VERSION ""

NS_ :

BS_:

BU_: Turbocharger OnBoardDataLogger OffBoardDiagnosticTool2 OffBoardDiagnosticTool1 FileServer ParkingBrakeController SeatController2 FanDriveController SteeringColumnUnit CommunicationUnitRadio CommunicationUnitSatellite CommunicationUnitCellular PropulsionBatteryCharger ChassisController2 ChassisController1 EngineValveControl AuxiliaryHeater2 AuxiliaryHeater1 ClutchUnit RampControl InformationSystem1 SuspensionSystemController2 OilSensor VehicleDynamicStability ExhaustEmissionController TransmissionDisplay2 TransmissionDisplay1 ClimateControl2 WaterPumpController RearAxleSteeringController LightingOperatorControl SeatController1 IgnitionController2 IgnitionController1 TirePressureController CabController2 CabController1 PneumaticSystemController SuspensionSystemController1 HydraulicPumpController EnduranceBrakingSystem RetarderExhaustEngine2 OnBoardDiagnosticUnit HeadwayController RetarderExhaustEngine1 CabDisplay1 ManagementComputer VirtualTerminal OffVehicleGateway PowerTakeOffFront HitchControl AuxiliaryValveControl BodyController TractorTrailerBridge1 StarterSystem ElectricalSystem VehicleSecurity VehicleNavigation AerodynamicControl ElectricalChargingSystem ClimateControl1 TripRecorder InstrumentCluster SuspensionDriveAxle2 SuspensionDriveAxle1 SuspensionSteerAxle SteeringController FuelSystem CruiseControl RetarderDriveline RetarderEngine BrakesDriveAxle2 BrakesDriveAxle1 BrakesSystemController BrakesSteerAxle AxleDrive2 AxleDrive1 AxleSteering PowerTakeOff ShiftConsoleSecondary ShiftConsolePrimary Transmission2 Transmission1 Engine2 Engine1

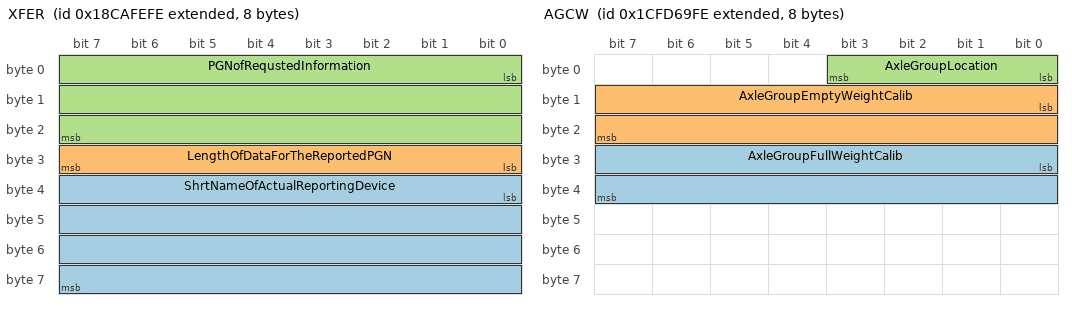
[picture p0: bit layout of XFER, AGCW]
BO_ 2563440382 XFER: 8 Vector__XXX
 SG_ ShrtNameOfActualReportingDevice : 32|32@1+ (1,0) [0|0] "(2^32 - 1)" Vector__XXX
 SG_ LengthOfDataForTheReportedPGN : 24|8@1+ (1,0) [0|255] "" Vector__XXX
 SG_ PGNofRequstedInformation : 0|24@1+ (1,0) [0|16777215] "" Vector__XXX

BO_ 2632711934 TPDT: 8 Vector__XXX
 SG_ SequenceNumber : 0|8@1+ (1,0) [0|255] "" Vector__XXX

BO_ 2632777470 TPCM: 8 Vector__XXX
 SG_ TotalNumberOfPacketsEoMA m19 : 24|8@1+ (1,0) [0|255] "" Vector__XXX
 SG_ TotalMessageSizeEoMA m19 : 8|16@1+ (1,0) [0|64255] "counts" Vector__XXX
 SG_ TotalMessageSizeBAM m32 : 8|16@1+ (1,0) [0|64255] "counts" Vector__XXX
 SG_ TotalNumberOfPacketsBAM m32 : 24|8@1+ (1,0) [0|255] "" Vector__XXX
 SG_ ConnectionAbortReason m255 : 8|8@1+ (1,0) [0|255] "" Vector__XXX
 SG_ NextPacketNumberToBeSent m17 : 16|8@1+ (1,0) [0|255] "" Vector__XXX
 SG_ NumberOfPacketsThatCanBeSent m17 : 8|8@1+ (1,0) [0|255] "" Vector__XXX
 SG_ PGNumber : 40|24@1+ (1,0) [0|16777200] "" Vector__XXX
 SG_ MaximumNumberOfPackets m16 : 32|8@1+ (1,0) [0|255] "" Vector__XXX
 SG_ TotalNumberOfPackets m16 : 24|8@1+ (1,0) [0|255] "" Vector__XXX
 SG_ TotalMessageSize m16 : 8|16@1+ (1,0) [0|64255] "counts" Vector__XXX
 SG_ ControlByte M : 0|8@1+ (1,0) [0|255] "" Vector__XXX

BO_ 2563374846 RQST2: 8 Vector__XXX
 SG_ UseTransferMode : 24|2@1+ (1,0) [0|3] "" Vector__XXX
 SG_ ParameterGroupNumber : 0|24@1+ (1,0) [0|16777215] "" Vector__XXX

BO_ 2565537534 RQST: 3 Vector__XXX
 SG_ ParameterGroupNumber : 0|24@1+ (1,0) [0|16777215] "" Vector__XXX

BO_ 2499635966 AGW: 8 Vector__XXX
 SG_ AxleGroupWeight : 8|16@1+ (2,0) [0|128510] "kg" Vector__XXX
 SG_ AxleGroupLocation : 0|4@1+ (1,0) [0|15] "" Vector__XXX

BO_ 2633853438 AGCW: 8 Vector__XXX
 SG_ AxleGroupFullWeightCalib : 24|16@1+ (2,0) [0|128510] "kg" Vector__XXX
 SG_ AxleGroupEmptyWeightCalib : 8|16@1+ (2,0) [0|128510] "kg" Vector__XXX
 SG_ AxleGroupLocation : 0|4@1+ (1,0) [0|15] "" Vector__XXX

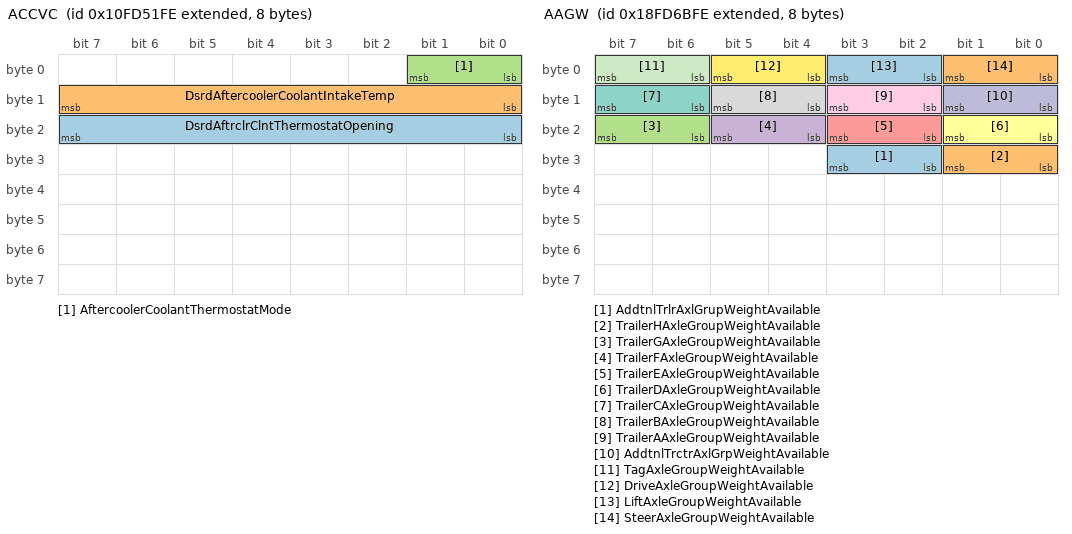
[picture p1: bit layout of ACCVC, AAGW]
BO_ 2432520702 ACCVC: 8 Vector__XXX
 SG_ DsrdAftrclrClntThermostatOpening : 16|8@1+ (0.4,0) [0|100] "%" Vector__XXX
 SG_ DsrdAftercoolerCoolantIntakeTemp : 8|8@1+ (1,-40) [-40|210] "deg C" Vector__XXX
 SG_ AftercoolerCoolantThermostatMode : 0|2@1+ (1,0) [0|3] "" Vector__XXX

BO_ 2566745086 AAGW: 8 Vector__XXX
 SG_ AddtnlTrlrAxlGrupWeightAvailable : 26|2@1+ (1,0) [0|3] "" Vector__XXX
 SG_ TrailerHAxleGroupWeightAvailable : 24|2@1+ (1,0) [0|3] "" Vector__XXX
 SG_ TrailerGAxleGroupWeightAvailable : 22|2@1+ (1,0) [0|3] "" Vector__XXX
 SG_ TrailerFAxleGroupWeightAvailable : 20|2@1+ (1,0) [0|3] "" Vector__XXX
 SG_ TrailerEAxleGroupWeightAvailable : 18|2@1+ (1,0) [0|3] "" Vector__XXX
 SG_ TrailerDAxleGroupWeightAvailable : 16|2@1+ (1,0) [0|3] "" Vector__XXX
 SG_ TrailerCAxleGroupWeightAvailable : 14|2@1+ (1,0) [0|3] "" Vector__XXX
 SG_ TrailerBAxleGroupWeightAvailable : 12|2@1+ (1,0) [0|3] "" Vector__XXX
 SG_ TrailerAAxleGroupWeightAvailable : 10|2@1+ (1,0) [0|3] "" Vector__XXX
 SG_ AddtnlTrctrAxlGrpWeightAvailable : 8|2@1+ (1,0) [0|3] "" Vector__XXX
 SG_ TagAxleGroupWeightAvailable : 6|2@1+ (1,0) [0|3] "" Vector__XXX
 SG_ DriveAxleGroupWeightAvailable : 4|2@1+ (1,0) [0|3] "" Vector__XXX
 SG_ LiftAxleGroupWeightAvailable : 2|2@1+ (1,0) [0|3] "" Vector__XXX
 SG_ SteerAxleGroupWeightAvailable : 0|2@1+ (1,0) [0|3] "" Vector__XXX

BO_ 2566739198 DM52: 22 Vector__XXX
 SG_ FlashRedStopLamp : 12|2@1+ (1,0) [0|3] "" Vector__XXX
 SG_ FlashProtectLamp : 8|2@1+ (1,0) [0|3] "" Vector__XXX
 SG_ FlashMalfuncIndicatorLamp : 14|2@1+ (1,0) [0|3] "" Vector__XXX
 SG_ FlashAmberWarningLamp : 10|2@1+ (1,0) [0|3] "" Vector__XXX
 SG_ MalfunctionIndicatorLampStatus : 6|2@1+ (1,0) [0|3] "" Vector__XXX
 SG_ AmberWarningLampStatus : 2|2@1+ (1,0) [0|3] "" Vector__XXX
 SG_ RedStopLampState : 4|2@1+ (1,0) [0|3] "" Vector__XXX
 SG_ ProtectLampStatus : 0|2@1+ (1,0) [0|3] "" Vector__XXX
 SG_ DTC5 : 144|32@1+ (1,0) [0|4294967295] "" Vector__XXX
 SG_ DTC4 : 112|32@1+ (1,0) [0|4294967295] "" Vector__XXX
 SG_ DTC3 : 80|32@1+ (1,0) [0|4294967295] "" Vector__XXX
 SG_ DTC2 : 48|32@1+ (1,0) [0|4294967295] "" Vector__XXX
 SG_ DTC1 : 16|32@1+ (1,0) [0|4294967295] "" Vector__XXX

BO_ 2566739454 DM51: 22 Vector__XXX
 SG_ FlashRedStopLamp : 12|2@1+ (1,0) [0|3] "" Vector__XXX
 SG_ FlashProtectLamp : 8|2@1+ (1,0) [0|3] "" Vector__XXX
 SG_ FlashMalfuncIndicatorLamp : 14|2@1+ (1,0) [0|3] "" Vector__XXX
 SG_ FlashAmberWarningLamp : 10|2@1+ (1,0) [0|3] "" Vector__XXX
 SG_ MalfunctionIndicatorLampStatus : 6|2@1+ (1,0) [0|3] "" Vector__XXX
 SG_ AmberWarningLampStatus : 2|2@1+ (1,0) [0|3] "" Vector__XXX
 SG_ RedStopLampState : 4|2@1+ (1,0) [0|3] "" Vector__XXX
 SG_ ProtectLampStatus : 0|2@1+ (1,0) [0|3] "" Vector__XXX
 SG_ DTC5 : 144|32@1+ (1,0) [0|4294967295] "" Vector__XXX
 SG_ DTC4 : 112|32@1+ (1,0) [0|4294967295] "" Vector__XXX
 SG_ DTC3 : 80|32@1+ (1,0) [0|4294967295] "" Vector__XXX
 SG_ DTC2 : 48|32@1+ (1,0) [0|4294967295] "" Vector__XXX
 SG_ DTC1 : 16|32@1+ (1,0) [0|4294967295] "" Vector__XXX

BO_ 2566739710 DM50: 22 Vector__XXX
 SG_ FlashRedStopLamp : 12|2@1+ (1,0) [0|3] "" Vector__XXX
 SG_ FlashProtectLamp : 8|2@1+ (1,0) [0|3] "" Vector__XXX
 SG_ FlashMalfuncIndicatorLamp : 14|2@1+ (1,0) [0|3] "" Vector__XXX
 SG_ FlashAmberWarningLamp : 10|2@1+ (1,0) [0|3] "" Vector__XXX
 SG_ MalfunctionIndicatorLampStatus : 6|2@1+ (1,0) [0|3] "" Vector__XXX
 SG_ AmberWarningLampStatus : 2|2@1+ (1,0) [0|3] "" Vector__XXX
 SG_ RedStopLampState : 4|2@1+ (1,0) [0|3] "" Vector__XXX
 SG_ ProtectLampStatus : 0|2@1+ (1,0) [0|3] "" Vector__XXX
 SG_ DTC5 : 144|32@1+ (1,0) [0|4294967295] "" Vector__XXX
 SG_ DTC4 : 112|32@1+ (1,0) [0|4294967295] "" Vector__XXX
 SG_ DTC3 : 80|32@1+ (1,0) [0|4294967295] "" Vector__XXX
 SG_ DTC2 : 48|32@1+ (1,0) [0|4294967295] "" Vector__XXX
 SG_ DTC1 : 16|32@1+ (1,0) [0|4294967295] "" Vector__XXX

BO_ 2566739966 DM49: 22 Vector__XXX
 SG_ FlashRedStopLamp : 12|2@1+ (1,0) [0|3] "" Vector__XXX
 SG_ FlashProtectLamp : 8|2@1+ (1,0) [0|3] "" Vector__XXX
 SG_ FlashMalfuncIndicatorLamp : 14|2@1+ (1,0) [0|3] "" Vector__XXX
 SG_ FlashAmberWarningLamp : 10|2@1+ (1,0) [0|3] "" Vector__XXX
 SG_ MalfunctionIndicatorLampStatus : 6|2@1+ (1,0) [0|3] "" Vector__XXX
 SG_ AmberWarningLampStatus : 2|2@1+ (1,0) [0|3] "" Vector__XXX
 SG_ RedStopLampState : 4|2@1+ (1,0) [0|3] "" Vector__XXX
 SG_ ProtectLampStatus : 0|2@1+ (1,0) [0|3] "" Vector__XXX
 SG_ DTC5 : 144|32@1+ (1,0) [0|4294967295] "" Vector__XXX
 SG_ DTC4 : 112|32@1+ (1,0) [0|4294967295] "" Vector__XXX
 SG_ DTC3 : 80|32@1+ (1,0) [0|4294967295] "" Vector__XXX
 SG_ DTC2 : 48|32@1+ (1,0) [0|4294967295] "" Vector__XXX
 SG_ DTC1 : 16|32@1+ (1,0) [0|4294967295] "" Vector__XXX

BO_ 2566740222 DM48: 22 Vector__XXX
 SG_ FlashRedStopLamp : 12|2@1+ (1,0) [0|3] "" Vector__XXX
 SG_ FlashProtectLamp : 8|2@1+ (1,0) [0|3] "" Vector__XXX
 SG_ FlashMalfuncIndicatorLamp : 14|2@1+ (1,0) [0|3] "" Vector__XXX
 SG_ FlashAmberWarningLamp : 10|2@1+ (1,0) [0|3] "" Vector__XXX
 SG_ MalfunctionIndicatorLampStatus : 6|2@1+ (1,0) [0|3] "" Vector__XXX
 SG_ AmberWarningLampStatus : 2|2@1+ (1,0) [0|3] "" Vector__XXX
 SG_ RedStopLampState : 4|2@1+ (1,0) [0|3] "" Vector__XXX
 SG_ ProtectLampStatus : 0|2@1+ (1,0) [0|3] "" Vector__XXX
 SG_ DTC5 : 144|32@1+ (1,0) [0|4294967295] "" Vector__XXX
 SG_ DTC4 : 112|32@1+ (1,0) [0|4294967295] "" Vector__XXX
 SG_ DTC3 : 80|32@1+ (1,0) [0|4294967295] "" Vector__XXX
 SG_ DTC2 : 48|32@1+ (1,0) [0|4294967295] "" Vector__XXX
 SG_ DTC1 : 16|32@1+ (1,0) [0|4294967295] "" Vector__XXX

BO_ 2566740478 DM47: 22 Vector__XXX
 SG_ FlashRedStopLamp : 12|2@1+ (1,0) [0|3] "" Vector__XXX
 SG_ FlashProtectLamp : 8|2@1+ (1,0) [0|3] "" Vector__XXX
 SG_ FlashMalfuncIndicatorLamp : 14|2@1+ (1,0) [0|3] "" Vector__XXX
 SG_ FlashAmberWarningLamp : 10|2@1+ (1,0) [0|3] "" Vector__XXX
 SG_ MalfunctionIndicatorLampStatus : 6|2@1+ (1,0) [0|3] "" Vector__XXX
 SG_ AmberWarningLampStatus : 2|2@1+ (1,0) [0|3] "" Vector__XXX
 SG_ RedStopLampState : 4|2@1+ (1,0) [0|3] "" Vector__XXX
 SG_ ProtectLampStatus : 0|2@1+ (1,0) [0|3] "" Vector__XXX
 SG_ DTC5 : 144|32@1+ (1,0) [0|4294967295] "" Vector__XXX
 SG_ DTC4 : 112|32@1+ (1,0) [0|4294967295] "" Vector__XXX
 SG_ DTC3 : 80|32@1+ (1,0) [0|4294967295] "" Vector__XXX
 SG_ DTC2 : 48|32@1+ (1,0) [0|4294967295] "" Vector__XXX
 SG_ DTC1 : 16|32@1+ (1,0) [0|4294967295] "" Vector__XXX

BO_ 2566740734 DM46: 22 Vector__XXX
 SG_ FlashRedStopLamp : 12|2@1+ (1,0) [0|3] "" Vector__XXX
 SG_ FlashProtectLamp : 8|2@1+ (1,0) [0|3] "" Vector__XXX
 SG_ FlashMalfuncIndicatorLamp : 14|2@1+ (1,0) [0|3] "" Vector__XXX
 SG_ FlashAmberWarningLamp : 10|2@1+ (1,0) [0|3] "" Vector__XXX
 SG_ MalfunctionIndicatorLampStatus : 6|2@1+ (1,0) [0|3] "" Vector__XXX
 SG_ AmberWarningLampStatus : 2|2@1+ (1,0) [0|3] "" Vector__XXX
 SG_ RedStopLampState : 4|2@1+ (1,0) [0|3] "" Vector__XXX
 SG_ ProtectLampStatus : 0|2@1+ (1,0) [0|3] "" Vector__XXX
 SG_ DTC5 : 144|32@1+ (1,0) [0|4294967295] "" Vector__XXX
 SG_ DTC4 : 112|32@1+ (1,0) [0|4294967295] "" Vector__XXX
 SG_ DTC3 : 80|32@1+ (1,0) [0|4294967295] "" Vector__XXX
 SG_ DTC2 : 48|32@1+ (1,0) [0|4294967295] "" Vector__XXX
 SG_ DTC1 : 16|32@1+ (1,0) [0|4294967295] "" Vector__XXX

BO_ 2566740990 DM45: 22 Vector__XXX
 SG_ FlashRedStopLamp : 12|2@1+ (1,0) [0|3] "" Vector__XXX
 SG_ FlashProtectLamp : 8|2@1+ (1,0) [0|3] "" Vector__XXX
 SG_ FlashMalfuncIndicatorLamp : 14|2@1+ (1,0) [0|3] "" Vector__XXX
 SG_ FlashAmberWarningLamp : 10|2@1+ (1,0) [0|3] "" Vector__XXX
 SG_ MalfunctionIndicatorLampStatus : 6|2@1+ (1,0) [0|3] "" Vector__XXX
 SG_ AmberWarningLampStatus : 2|2@1+ (1,0) [0|3] "" Vector__XXX
 SG_ RedStopLampState : 4|2@1+ (1,0) [0|3] "" Vector__XXX
 SG_ ProtectLampStatus : 0|2@1+ (1,0) [0|3] "" Vector__XXX
 SG_ DTC5 : 144|32@1+ (1,0) [0|4294967295] "" Vector__XXX
 SG_ DTC4 : 112|32@1+ (1,0) [0|4294967295] "" Vector__XXX
 SG_ DTC3 : 80|32@1+ (1,0) [0|4294967295] "" Vector__XXX
 SG_ DTC2 : 48|32@1+ (1,0) [0|4294967295] "" Vector__XXX
 SG_ DTC1 : 16|32@1+ (1,0) [0|4294967295] "" Vector__XXX

BO_ 2566741246 DM44: 22 Vector__XXX
 SG_ FlashRedStopLamp : 12|2@1+ (1,0) [0|3] "" Vector__XXX
 SG_ FlashProtectLamp : 8|2@1+ (1,0) [0|3] "" Vector__XXX
 SG_ FlashMalfuncIndicatorLamp : 14|2@1+ (1,0) [0|3] "" Vector__XXX
 SG_ FlashAmberWarningLamp : 10|2@1+ (1,0) [0|3] "" Vector__XXX
 SG_ MalfunctionIndicatorLampStatus : 6|2@1+ (1,0) [0|3] "" Vector__XXX
 SG_ AmberWarningLampStatus : 2|2@1+ (1,0) [0|3] "" Vector__XXX
 SG_ RedStopLampState : 4|2@1+ (1,0) [0|3] "" Vector__XXX
 SG_ ProtectLampStatus : 0|2@1+ (1,0) [0|3] "" Vector__XXX
 SG_ DTC5 : 144|32@1+ (1,0) [0|4294967295] "" Vector__XXX
 SG_ DTC4 : 112|32@1+ (1,0) [0|4294967295] "" Vector__XXX
 SG_ DTC3 : 80|32@1+ (1,0) [0|4294967295] "" Vector__XXX
 SG_ DTC2 : 48|32@1+ (1,0) [0|4294967295] "" Vector__XXX
 SG_ DTC1 : 16|32@1+ (1,0) [0|4294967295] "" Vector__XXX

BO_ 2566741502 DM43: 22 Vector__XXX
 SG_ FlashRedStopLamp : 12|2@1+ (1,0) [0|3] "" Vector__XXX
 SG_ FlashProtectLamp : 8|2@1+ (1,0) [0|3] "" Vector__XXX
 SG_ FlashMalfuncIndicatorLamp : 14|2@1+ (1,0) [0|3] "" Vector__XXX
 SG_ FlashAmberWarningLamp : 10|2@1+ (1,0) [0|3] "" Vector__XXX
 SG_ MalfunctionIndicatorLampStatus : 6|2@1+ (1,0) [0|3] "" Vector__XXX
 SG_ AmberWarningLampStatus : 2|2@1+ (1,0) [0|3] "" Vector__XXX
 SG_ RedStopLampState : 4|2@1+ (1,0) [0|3] "" Vector__XXX
 SG_ ProtectLampStatus : 0|2@1+ (1,0) [0|3] "" Vector__XXX
 SG_ DTC5 : 144|32@1+ (1,0) [0|4294967295] "" Vector__XXX
 SG_ DTC4 : 112|32@1+ (1,0) [0|4294967295] "" Vector__XXX
 SG_ DTC3 : 80|32@1+ (1,0) [0|4294967295] "" Vector__XXX
 SG_ DTC2 : 48|32@1+ (1,0) [0|4294967295] "" Vector__XXX
 SG_ DTC1 : 16|32@1+ (1,0) [0|4294967295] "" Vector__XXX

BO_ 2566741758 DM42: 22 Vector__XXX
 SG_ FlashRedStopLamp : 12|2@1+ (1,0) [0|3] "" Vector__XXX
 SG_ FlashProtectLamp : 8|2@1+ (1,0) [0|3] "" Vector__XXX
 SG_ FlashMalfuncIndicatorLamp : 14|2@1+ (1,0) [0|3] "" Vector__XXX
 SG_ FlashAmberWarningLamp : 10|2@1+ (1,0) [0|3] "" Vector__XXX
 SG_ MalfunctionIndicatorLampStatus : 6|2@1+ (1,0) [0|3] "" Vector__XXX
 SG_ AmberWarningLampStatus : 2|2@1+ (1,0) [0|3] "" Vector__XXX
 SG_ RedStopLampState : 4|2@1+ (1,0) [0|3] "" Vector__XXX
 SG_ ProtectLampStatus : 0|2@1+ (1,0) [0|3] "" Vector__XXX
 SG_ DTC5 : 144|32@1+ (1,0) [0|4294967295] "" Vector__XXX
 SG_ DTC4 : 112|32@1+ (1,0) [0|4294967295] "" Vector__XXX
 SG_ DTC3 : 80|32@1+ (1,0) [0|4294967295] "" Vector__XXX
 SG_ DTC2 : 48|32@1+ (1,0) [0|4294967295] "" Vector__XXX
 SG_ DTC1 : 16|32@1+ (1,0) [0|4294967295] "" Vector__XXX

BO_ 2566742014 DM41: 22 Vector__XXX
 SG_ FlashRedStopLamp : 12|2@1+ (1,0) [0|3] "" Vector__XXX
 SG_ FlashProtectLamp : 8|2@1+ (1,0) [0|3] "" Vector__XXX
 SG_ FlashMalfuncIndicatorLamp : 14|2@1+ (1,0) [0|3] "" Vector__XXX
 SG_ FlashAmberWarningLamp : 10|2@1+ (1,0) [0|3] "" Vector__XXX
 SG_ MalfunctionIndicatorLampStatus : 6|2@1+ (1,0) [0|3] "" Vector__XXX
 SG_ AmberWarningLampStatus : 2|2@1+ (1,0) [0|3] "" Vector__XXX
 SG_ RedStopLampState : 4|2@1+ (1,0) [0|3] "" Vector__XXX
 SG_ ProtectLampStatus : 0|2@1+ (1,0) [0|3] "" Vector__XXX
 SG_ DTC5 : 144|32@1+ (1,0) [0|4294967295] "" Vector__XXX
 SG_ DTC4 : 112|32@1+ (1,0) [0|4294967295] "" Vector__XXX
 SG_ DTC3 : 80|32@1+ (1,0) [0|4294967295] "" Vector__XXX
 SG_ DTC2 : 48|32@1+ (1,0) [0|4294967295] "" Vector__XXX
 SG_ DTC1 : 16|32@1+ (1,0) [0|4294967295] "" Vector__XXX

BO_ 2560622334 DM35: 22 Vector__XXX
 SG_ FlashRedStopLamp : 12|2@1+ (1,0) [0|3] "" Vector__XXX
 SG_ FlashProtectLamp : 8|2@1+ (1,0) [0|3] "" Vector__XXX
 SG_ FlashMalfuncIndicatorLamp : 14|2@1+ (1,0) [0|3] "" Vector__XXX
 SG_ FlashAmberWarningLamp : 10|2@1+ (1,0) [0|3] "" Vector__XXX
 SG_ MalfunctionIndicatorLampStatus : 6|2@1+ (1,0) [0|3] "" Vector__XXX
 SG_ AmberWarningLampStatus : 2|2@1+ (1,0) [0|3] "" Vector__XXX
 SG_ RedStopLampState : 4|2@1+ (1,0) [0|3] "" Vector__XXX
 SG_ ProtectLampStatus : 0|2@1+ (1,0) [0|3] "" Vector__XXX
 SG_ DTC5 : 144|32@1+ (1,0) [0|4294967295] "" Vector__XXX
 SG_ DTC4 : 112|32@1+ (1,0) [0|4294967295] "" Vector__XXX
 SG_ DTC3 : 80|32@1+ (1,0) [0|4294967295] "" Vector__XXX
 SG_ DTC2 : 48|32@1+ (1,0) [0|4294967295] "" Vector__XXX
 SG_ DTC1 : 16|32@1+ (1,0) [0|4294967295] "" Vector__XXX

BO_ 2566744062 ZNVW: 8 Vector__XXX
 SG_ ZeroNetVehicleWeightChange : 0|2@1+ (1,0) [0|3] "" Vector__XXX

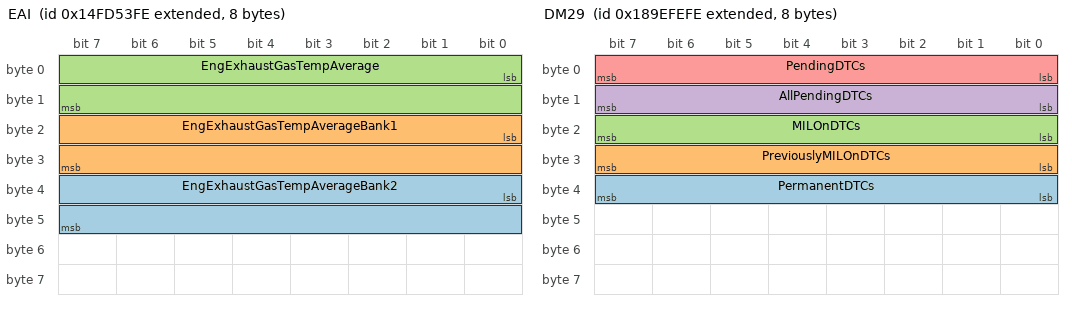
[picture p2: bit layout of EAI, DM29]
BO_ 2499630078 EAI: 8 Vector__XXX
 SG_ EngExhaustGasTempAverageBank2 : 32|16@1+ (0.03125,-273) [-273|1734.96875] "deg C" Vector__XXX
 SG_ EngExhaustGasTempAverageBank1 : 16|16@1+ (0.03125,-273) [-273|1734.96875] "deg C" Vector__XXX
 SG_ EngExhaustGasTempAverage : 0|16@1+ (0.03125,-273) [-273|1734.96875] "deg C" Vector__XXX

BO_ 2560556798 DM29: 8 Vector__XXX
 SG_ PermanentDTCs : 32|8@1+ (1,0) [0|255] "" Vector__XXX
 SG_ PreviouslyMILOnDTCs : 24|8@1+ (1,0) [0|255] "" Vector__XXX
 SG_ MILOnDTCs : 16|8@1+ (1,0) [0|255] "" Vector__XXX
 SG_ AllPendingDTCs : 8|8@1+ (1,0) [0|255] "" Vector__XXX
 SG_ PendingDTCs : 0|8@1+ (1,0) [0|255] "" Vector__XXX

BO_ 2566750462 DM28: 22 Vector__XXX
 SG_ FlashRedStopLamp : 12|2@1+ (1,0) [0|3] "" Vector__XXX
 SG_ FlashProtectLamp : 8|2@1+ (1,0) [0|3] "" Vector__XXX
 SG_ FlashMalfuncIndicatorLamp : 14|2@1+ (1,0) [0|3] "" Vector__XXX
 SG_ FlashAmberWarningLamp : 10|2@1+ (1,0) [0|3] "" Vector__XXX
 SG_ MalfunctionIndicatorLampStatus : 6|2@1+ (1,0) [0|3] "" Vector__XXX
 SG_ AmberWarningLampStatus : 2|2@1+ (1,0) [0|3] "" Vector__XXX
 SG_ RedStopLampState : 4|2@1+ (1,0) [0|3] "" Vector__XXX
 SG_ ProtectLampStatus : 0|2@1+ (1,0) [0|3] "" Vector__XXX
 SG_ DTC5 : 144|32@1+ (1,0) [0|4294967295] "" Vector__XXX
 SG_ DTC4 : 112|32@1+ (1,0) [0|4294967295] "" Vector__XXX
 SG_ DTC3 : 80|32@1+ (1,0) [0|4294967295] "" Vector__XXX
 SG_ DTC2 : 48|32@1+ (1,0) [0|4294967295] "" Vector__XXX
 SG_ DTC1 : 16|32@1+ (1,0) [0|4294967295] "" Vector__XXX

BO_ 2566750974 DM27: 22 Vector__XXX
 SG_ FlashRedStopLamp : 12|2@1+ (1,0) [0|3] "" Vector__XXX
 SG_ FlashProtectLamp : 8|2@1+ (1,0) [0|3] "" Vector__XXX
 SG_ FlashMalfuncIndicatorLamp : 14|2@1+ (1,0) [0|3] "" Vector__XXX
 SG_ FlashAmberWarningLamp : 10|2@1+ (1,0) [0|3] "" Vector__XXX
 SG_ MalfunctionIndicatorLampStatus : 6|2@1+ (1,0) [0|3] "" Vector__XXX
 SG_ AmberWarningLampStatus : 2|2@1+ (1,0) [0|3] "" Vector__XXX
 SG_ RedStopLampState : 4|2@1+ (1,0) [0|3] "" Vector__XXX
 SG_ ProtectLampStatus : 0|2@1+ (1,0) [0|3] "" Vector__XXX
 SG_ DTC5 : 144|32@1+ (1,0) [0|4294967295] "" Vector__XXX
 SG_ DTC4 : 112|32@1+ (1,0) [0|4294967295] "" Vector__XXX
 SG_ DTC3 : 80|32@1+ (1,0) [0|4294967295] "" Vector__XXX
 SG_ DTC2 : 48|32@1+ (1,0) [0|4294967295] "" Vector__XXX
 SG_ DTC1 : 16|32@1+ (1,0) [0|4294967295] "" Vector__XXX

BO_ 2566754558 AETC: 61 Vector__XXX
 SG_ AETCTorqueValue14 : 472|16@1+ (1,0) [0|65535] "Nm" Vector__XXX
 SG_ AETCTorqueValue13 : 440|16@1+ (1,0) [0|65535] "Nm" Vector__XXX
 SG_ AETCTorqueValue12 : 408|16@1+ (1,0) [0|65535] "Nm" Vector__XXX
 SG_ AETCTorqueValue11 : 376|16@1+ (1,0) [0|65535] "Nm" Vector__XXX
 SG_ AETCTorqueValue10 : 344|16@1+ (1,0) [0|65535] "Nm" Vector__XXX
 SG_ AETCTorqueValue09 : 312|16@1+ (1,0) [0|65535] "Nm" Vector__XXX
 SG_ AETCTorqueValue08 : 280|16@1+ (1,0) [0|65535] "Nm" Vector__XXX
 SG_ AETCTorqueValue07 : 248|16@1+ (1,0) [0|65535] "Nm" Vector__XXX
 SG_ AETCTorqueValue06 : 216|16@1+ (1,0) [0|65535] "Nm" Vector__XXX
 SG_ AETCTorqueValue05 : 184|16@1+ (1,0) [0|65535] "Nm" Vector__XXX
 SG_ AETCTorqueValue04 : 152|16@1+ (1,0) [0|65535] "Nm" Vector__XXX
 SG_ AETCTorqueValue03 : 120|16@1+ (1,0) [0|65535] "Nm" Vector__XXX
 SG_ AETCTorqueValue02 : 88|16@1+ (1,0) [0|65535] "Nm" Vector__XXX
 SG_ AETCTorqueValue01 : 56|16@1+ (1,0) [0|65535] "Nm" Vector__XXX
 SG_ AETCSpeedValue14 : 456|16@1+ (0.125,0) [0|8191.875] "rpm" Vector__XXX
 SG_ AETCSpeedValue13 : 424|16@1+ (0.125,0) [0|8191.875] "rpm" Vector__XXX
 SG_ AETCSpeedValue12 : 392|16@1+ (0.125,0) [0|8191.875] "rpm" Vector__XXX
 SG_ AETCSpeedValue11 : 360|16@1+ (0.125,0) [0|8191.875] "rpm" Vector__XXX
 SG_ AETCSpeedValue10 : 328|16@1+ (0.125,0) [0|8191.875] "rpm" Vector__XXX
 SG_ AETCSpeedValue09 : 296|16@1+ (0.125,0) [0|8191.875] "rpm" Vector__XXX
 SG_ AETCSpeedValue08 : 264|16@1+ (0.125,0) [0|8191.875] "rpm" Vector__XXX
 SG_ AETCSpeedValue07 : 232|16@1+ (0.125,0) [0|8191.875] "rpm" Vector__XXX
 SG_ AETCSpeedValue06 : 200|16@1+ (0.125,0) [0|8191.875] "rpm" Vector__XXX
 SG_ AETCSpeedValue05 : 168|16@1+ (0.125,0) [0|8191.875] "rpm" Vector__XXX
 SG_ AETCSpeedValue04 : 136|16@1+ (0.125,0) [0|8191.875] "rpm" Vector__XXX
 SG_ AETCSpeedValue03 : 104|16@1+ (0.125,0) [0|8191.875] "rpm" Vector__XXX
 SG_ AETCSpeedValue02 : 72|16@1+ (0.125,0) [0|8191.875] "rpm" Vector__XXX
 SG_ AETCSpeedValue01 : 40|16@1+ (0.125,0) [0|8191.875] "rpm" Vector__XXX
 SG_ AETCTorqueValue00 : 24|16@1+ (1,0) [0|65535] "Nm" Vector__XXX
 SG_ AETCSpeedValue00 : 8|16@1+ (0.125,0) [0|8191.875] "rpm" Vector__XXX
 SG_ NumberOfAETCDataPoints : 4|4@1+ (1,0) [0|15] "" Vector__XXX
 SG_ AETCDataCollectionStandard : 0|4@1+ (1,0) [0|15] "" Vector__XXX

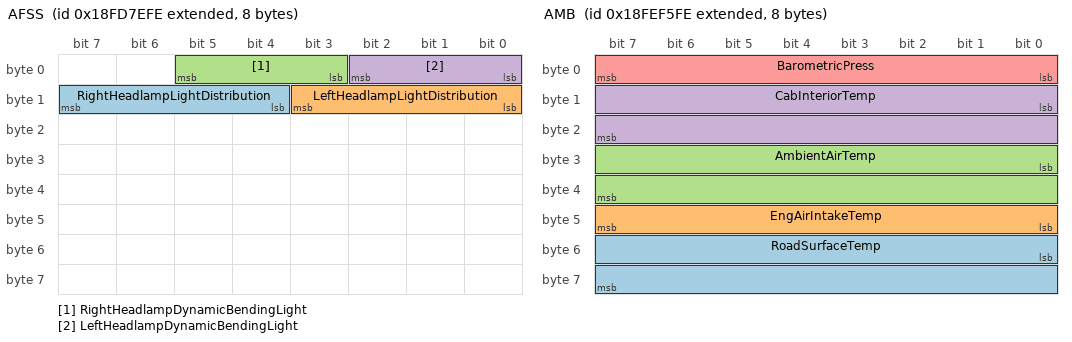
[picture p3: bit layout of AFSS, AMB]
BO_ 2566749950 AFSS: 8 Vector__XXX
 SG_ RightHeadlampLightDistribution : 12|4@1+ (1,0) [0|15] "" Vector__XXX
 SG_ LeftHeadlampLightDistribution : 8|4@1+ (1,0) [0|15] "" Vector__XXX
 SG_ RightHeadlampDynamicBendingLight : 3|3@1+ (1,0) [0|7] "" Vector__XXX
 SG_ LeftHeadlampDynamicBendingLight : 0|3@1+ (1,0) [0|7] "" Vector__XXX

BO_ 2566838782 AUXIO1: 8 Vector__XXX
 SG_ AuxI_OChannel2 : 48|16@1+ (1,0) [0|64255] "" Vector__XXX
 SG_ AuxI_OChannel1 : 32|16@1+ (1,0) [0|64255] "" Vector__XXX
 SG_ AuxI_O13 : 30|2@1+ (1,0) [0|3] "" Vector__XXX
 SG_ AuxI_O14 : 28|2@1+ (1,0) [0|3] "" Vector__XXX
 SG_ AuxI_O15 : 26|2@1+ (1,0) [0|3] "" Vector__XXX
 SG_ AuxI_O16 : 24|2@1+ (1,0) [0|3] "" Vector__XXX
 SG_ AuxI_O09 : 22|2@1+ (1,0) [0|3] "" Vector__XXX
 SG_ AuxI_O10 : 20|2@1+ (1,0) [0|3] "" Vector__XXX
 SG_ AuxI_O11 : 18|2@1+ (1,0) [0|3] "" Vector__XXX
 SG_ AuxI_O12 : 16|2@1+ (1,0) [0|3] "" Vector__XXX
 SG_ AuxI_O05 : 14|2@1+ (1,0) [0|3] "" Vector__XXX
 SG_ AuxI_O06 : 12|2@1+ (1,0) [0|3] "" Vector__XXX
 SG_ AuxI_O07 : 10|2@1+ (1,0) [0|3] "" Vector__XXX
 SG_ AuxI_O08 : 8|2@1+ (1,0) [0|3] "" Vector__XXX
 SG_ AuxI_O01 : 6|2@1+ (1,0) [0|3] "" Vector__XXX
 SG_ AuxI_O02 : 4|2@1+ (1,0) [0|3] "" Vector__XXX
 SG_ AuxI_O03 : 2|2@1+ (1,0) [0|3] "" Vector__XXX
 SG_ AuxI_O04 : 0|2@1+ (1,0) [0|3] "" Vector__XXX

BO_ 2561146622 AUXIO2: 8 Vector__XXX
 SG_ AuxI_O45 : 62|2@1+ (1,0) [0|3] "" Vector__XXX
 SG_ AuxI_O46 : 60|2@1+ (1,0) [0|3] "" Vector__XXX
 SG_ AuxI_O47 : 58|2@1+ (1,0) [0|3] "" Vector__XXX
 SG_ AuxI_O48 : 56|2@1+ (1,0) [0|3] "" Vector__XXX
 SG_ AuxI_O41 : 54|2@1+ (1,0) [0|3] "" Vector__XXX
 SG_ AuxI_O42 : 52|2@1+ (1,0) [0|3] "" Vector__XXX
 SG_ AuxI_O43 : 50|2@1+ (1,0) [0|3] "" Vector__XXX
 SG_ AuxI_O44 : 48|2@1+ (1,0) [0|3] "" Vector__XXX
 SG_ AuxI_O37 : 46|2@1+ (1,0) [0|3] "" Vector__XXX
 SG_ AuxI_O38 : 44|2@1+ (1,0) [0|3] "" Vector__XXX
 SG_ AuxI_O39 : 42|2@1+ (1,0) [0|3] "" Vector__XXX
 SG_ AuxI_O40 : 40|2@1+ (1,0) [0|3] "" Vector__XXX
 SG_ AuxI_O33 : 38|2@1+ (1,0) [0|3] "" Vector__XXX
 SG_ AuxI_O34 : 36|2@1+ (1,0) [0|3] "" Vector__XXX
 SG_ AuxI_O35 : 34|2@1+ (1,0) [0|3] "" Vector__XXX
 SG_ AuxI_O36 : 32|2@1+ (1,0) [0|3] "" Vector__XXX
 SG_ AuxI_O29 : 30|2@1+ (1,0) [0|3] "" Vector__XXX
 SG_ AuxI_O30 : 28|2@1+ (1,0) [0|3] "" Vector__XXX
 SG_ AuxI_O31 : 26|2@1+ (1,0) [0|3] "" Vector__XXX
 SG_ AuxI_O32 : 24|2@1+ (1,0) [0|3] "" Vector__XXX
 SG_ AuxI_O25 : 22|2@1+ (1,0) [0|3] "" Vector__XXX
 SG_ AuxI_O26 : 20|2@1+ (1,0) [0|3] "" Vector__XXX
 SG_ AuxI_O27 : 18|2@1+ (1,0) [0|3] "" Vector__XXX
 SG_ AuxI_O28 : 16|2@1+ (1,0) [0|3] "" Vector__XXX
 SG_ AuxI_O21 : 14|2@1+ (1,0) [0|3] "" Vector__XXX
 SG_ AuxI_O22 : 12|2@1+ (1,0) [0|3] "" Vector__XXX
 SG_ AuxI_O23 : 10|2@1+ (1,0) [0|3] "" Vector__XXX
 SG_ AuxI_O24 : 8|2@1+ (1,0) [0|3] "" Vector__XXX
 SG_ AuxI_O17 : 6|2@1+ (1,0) [0|3] "" Vector__XXX
 SG_ AuxI_O18 : 4|2@1+ (1,0) [0|3] "" Vector__XXX
 SG_ AuxI_O19 : 2|2@1+ (1,0) [0|3] "" Vector__XXX
 SG_ AuxI_O20 : 0|2@1+ (1,0) [0|3] "" Vector__XXX

BO_ 2561081086 AUXIO3: 8 Vector__XXX
 SG_ AuxI_O77 : 62|2@1+ (1,0) [0|3] "" Vector__XXX
 SG_ AuxI_O78 : 60|2@1+ (1,0) [0|3] "" Vector__XXX
 SG_ AuxI_O79 : 58|2@1+ (1,0) [0|3] "" Vector__XXX
 SG_ AuxI_O80 : 56|2@1+ (1,0) [0|3] "" Vector__XXX
 SG_ AuxI_O73 : 54|2@1+ (1,0) [0|3] "" Vector__XXX
 SG_ AuxI_O74 : 52|2@1+ (1,0) [0|3] "" Vector__XXX
 SG_ AuxI_O75 : 50|2@1+ (1,0) [0|3] "" Vector__XXX
 SG_ AuxI_O76 : 48|2@1+ (1,0) [0|3] "" Vector__XXX
 SG_ AuxI_O69 : 46|2@1+ (1,0) [0|3] "" Vector__XXX
 SG_ AuxI_O70 : 44|2@1+ (1,0) [0|3] "" Vector__XXX
 SG_ AuxI_O71 : 42|2@1+ (1,0) [0|3] "" Vector__XXX
 SG_ AuxI_O72 : 40|2@1+ (1,0) [0|3] "" Vector__XXX
 SG_ AuxI_O65 : 38|2@1+ (1,0) [0|3] "" Vector__XXX
 SG_ AuxI_O66 : 36|2@1+ (1,0) [0|3] "" Vector__XXX
 SG_ AuxI_O67 : 34|2@1+ (1,0) [0|3] "" Vector__XXX
 SG_ AuxI_O68 : 32|2@1+ (1,0) [0|3] "" Vector__XXX
 SG_ AuxI_O61 : 30|2@1+ (1,0) [0|3] "" Vector__XXX
 SG_ AuxI_O62 : 28|2@1+ (1,0) [0|3] "" Vector__XXX
 SG_ AuxI_O63 : 26|2@1+ (1,0) [0|3] "" Vector__XXX
 SG_ AuxI_O64 : 24|2@1+ (1,0) [0|3] "" Vector__XXX
 SG_ AuxI_O57 : 22|2@1+ (1,0) [0|3] "" Vector__XXX
 SG_ AuxI_O58 : 20|2@1+ (1,0) [0|3] "" Vector__XXX
 SG_ AuxI_O59 : 18|2@1+ (1,0) [0|3] "" Vector__XXX
 SG_ AuxI_O60 : 16|2@1+ (1,0) [0|3] "" Vector__XXX
 SG_ AuxI_O53 : 14|2@1+ (1,0) [0|3] "" Vector__XXX
 SG_ AuxI_O54 : 12|2@1+ (1,0) [0|3] "" Vector__XXX
 SG_ AuxI_O55 : 10|2@1+ (1,0) [0|3] "" Vector__XXX
 SG_ AuxI_O56 : 8|2@1+ (1,0) [0|3] "" Vector__XXX
 SG_ AuxI_O49 : 6|2@1+ (1,0) [0|3] "" Vector__XXX
 SG_ AuxI_O50 : 4|2@1+ (1,0) [0|3] "" Vector__XXX
 SG_ AuxI_O51 : 2|2@1+ (1,0) [0|3] "" Vector__XXX
 SG_ AuxI_O52 : 0|2@1+ (1,0) [0|3] "" Vector__XXX

BO_ 2561015550 AUXIO4: 8 Vector__XXX
 SG_ AuxI_O109 : 62|2@1+ (1,0) [0|3] "" Vector__XXX
 SG_ AuxI_O110 : 60|2@1+ (1,0) [0|3] "" Vector__XXX
 SG_ AuxI_O111 : 58|2@1+ (1,0) [0|3] "" Vector__XXX
 SG_ AuxI_O112 : 56|2@1+ (1,0) [0|3] "" Vector__XXX
 SG_ AuxI_O105 : 54|2@1+ (1,0) [0|3] "" Vector__XXX
 SG_ AuxI_O106 : 52|2@1+ (1,0) [0|3] "" Vector__XXX
 SG_ AuxI_O107 : 50|2@1+ (1,0) [0|3] "" Vector__XXX
 SG_ AuxI_O108 : 48|2@1+ (1,0) [0|3] "" Vector__XXX
 SG_ AuxI_O101 : 46|2@1+ (1,0) [0|3] "" Vector__XXX
 SG_ AuxI_O102 : 44|2@1+ (1,0) [0|3] "" Vector__XXX
 SG_ AuxI_O103 : 42|2@1+ (1,0) [0|3] "" Vector__XXX
 SG_ AuxI_O104 : 40|2@1+ (1,0) [0|3] "" Vector__XXX
 SG_ AuxI_O97 : 38|2@1+ (1,0) [0|3] "" Vector__XXX
 SG_ AuxI_O98 : 36|2@1+ (1,0) [0|3] "" Vector__XXX
 SG_ AuxI_O99 : 34|2@1+ (1,0) [0|3] "" Vector__XXX
 SG_ AuxI_O100 : 32|2@1+ (1,0) [0|3] "" Vector__XXX
 SG_ AuxI_O93 : 30|2@1+ (1,0) [0|3] "" Vector__XXX
 SG_ AuxI_O94 : 28|2@1+ (1,0) [0|3] "" Vector__XXX
 SG_ AuxI_O95 : 26|2@1+ (1,0) [0|3] "" Vector__XXX
 SG_ AuxI_O96 : 24|2@1+ (1,0) [0|3] "" Vector__XXX
 SG_ AuxI_O89 : 22|2@1+ (1,0) [0|3] "" Vector__XXX
 SG_ AuxI_O90 : 20|2@1+ (1,0) [0|3] "" Vector__XXX
 SG_ AuxI_O91 : 18|2@1+ (1,0) [0|3] "" Vector__XXX
 SG_ AuxI_O92 : 16|2@1+ (1,0) [0|3] "" Vector__XXX
 SG_ AuxI_O85 : 14|2@1+ (1,0) [0|3] "" Vector__XXX
 SG_ AuxI_O86 : 12|2@1+ (1,0) [0|3] "" Vector__XXX
 SG_ AuxI_O87 : 10|2@1+ (1,0) [0|3] "" Vector__XXX
 SG_ AuxI_O88 : 8|2@1+ (1,0) [0|3] "" Vector__XXX
 SG_ AuxI_O81 : 6|2@1+ (1,0) [0|3] "" Vector__XXX
 SG_ AuxI_O82 : 4|2@1+ (1,0) [0|3] "" Vector__XXX
 SG_ AuxI_O83 : 2|2@1+ (1,0) [0|3] "" Vector__XXX
 SG_ AuxI_O84 : 0|2@1+ (1,0) [0|3] "" Vector__XXX

BO_ 2566746622 BSA: 8 Vector__XXX
 SG_ TrailerBrakeStrokeAxle5Right : 57|3@1+ (1,0) [0|7] "" Vector__XXX
 SG_ TrailerBrakeStrokeAxle5Left : 54|3@1+ (1,0) [0|7] "" Vector__XXX
 SG_ TrailerBrakeStrokeAxle4Right : 51|3@1+ (1,0) [0|7] "" Vector__XXX
 SG_ TrailerBrakeStrokeAxle4Left : 48|3@1+ (1,0) [0|7] "" Vector__XXX
 SG_ TrailerBrakeStrokeAxle3Right : 45|3@1+ (1,0) [0|7] "" Vector__XXX
 SG_ TrailerBrakeStrokeAxle3Left : 42|3@1+ (1,0) [0|7] "" Vector__XXX
 SG_ TrailerBrakeStrokeAxle2Right : 39|3@1+ (1,0) [0|7] "" Vector__XXX
 SG_ TrailerBrakeStrokeAxle2Left : 36|3@1+ (1,0) [0|7] "" Vector__XXX
 SG_ TrailerBrakeStrokeAxle1Right : 33|3@1+ (1,0) [0|7] "" Vector__XXX
 SG_ TrailerBrakeStrokeAxle1Left : 30|3@1+ (1,0) [0|7] "" Vector__XXX
 SG_ TractorBrakeStrokeAxle5Right : 27|3@1+ (1,0) [0|7] "" Vector__XXX
 SG_ TractorBrakeStrokeAxle5Left : 24|3@1+ (1,0) [0|7] "" Vector__XXX
 SG_ TractorBrakeStrokeAxle4Right : 21|3@1+ (1,0) [0|7] "" Vector__XXX
 SG_ TractorBrakeStrokeAxle4Left : 18|3@1+ (1,0) [0|7] "" Vector__XXX
 SG_ TractorBrakeStrokeAxle3Right : 15|3@1+ (1,0) [0|7] "" Vector__XXX
 SG_ TractorBrakeStrokeAxle3Left : 12|3@1+ (1,0) [0|7] "" Vector__XXX
 SG_ TractorBrakeStrokeAxle2Right : 9|3@1+ (1,0) [0|7] "" Vector__XXX
 SG_ TractorBrakeStrokeAxle2Left : 6|3@1+ (1,0) [0|7] "" Vector__XXX
 SG_ TractorBrakeStrokeAxle1Right : 3|3@1+ (1,0) [0|7] "" Vector__XXX
 SG_ TractorBrakeStrokeAxle1Left : 0|3@1+ (1,0) [0|7] "" Vector__XXX

BO_ 2566845950 AMB: 8 Vector__XXX
 SG_ RoadSurfaceTemp : 48|16@1+ (0.03125,-273) [-273|1734.96875] "deg C" Vector__XXX
 SG_ EngAirIntakeTemp : 40|8@1+ (1,-40) [-40|210] "deg C" Vector__XXX
 SG_ AmbientAirTemp : 24|16@1+ (0.03125,-273) [-273|1734.96875] "deg C" Vector__XXX
 SG_ CabInteriorTemp : 8|16@1+ (0.03125,-273) [-273|1734.96875] "deg C" Vector__XXX
 SG_ BarometricPress : 0|8@1+ (0.5,0) [0|125] "kPa" Vector__XXX

BO_ 2566840062 AIR2: 8 Vector__XXX
 SG_ EngAirStartPress : 0|8@1+ (4,0) [0|1000] "kPa" Vector__XXX

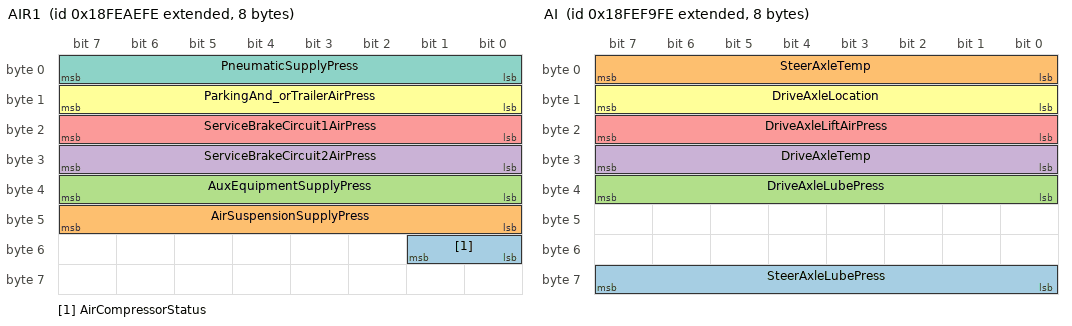
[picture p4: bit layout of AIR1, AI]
BO_ 2566827774 AIR1: 8 Vector__XXX
 SG_ AirCompressorStatus : 48|2@1+ (1,0) [0|3] "" Vector__XXX
 SG_ AirSuspensionSupplyPress : 40|8@1+ (8,0) [0|2000] "kPa" Vector__XXX
 SG_ AuxEquipmentSupplyPress : 32|8@1+ (8,0) [0|2000] "kPa" Vector__XXX
 SG_ ServiceBrakeCircuit2AirPress : 24|8@1+ (8,0) [0|2000] "kPa" Vector__XXX
 SG_ ServiceBrakeCircuit1AirPress : 16|8@1+ (8,0) [0|2000] "kPa" Vector__XXX
 SG_ ParkingAnd_orTrailerAirPress : 8|8@1+ (8,0) [0|2000] "kPa" Vector__XXX
 SG_ PneumaticSupplyPress : 0|8@1+ (8,0) [0|2000] "kPa" Vector__XXX

BO_ 2566846974 AI: 8 Vector__XXX
 SG_ SteerAxleLubePress : 56|8@1+ (4,0) [0|1000] "kPa" Vector__XXX
 SG_ SteerAxleTemp : 0|8@1+ (1,-40) [-40|210] "deg C" Vector__XXX
 SG_ DriveAxleLubePress : 32|8@1+ (4,0) [0|1000] "kPa" Vector__XXX
 SG_ DriveAxleTemp : 24|8@1+ (1,-40) [-40|210] "deg C" Vector__XXX
 SG_ DriveAxleLiftAirPress : 16|8@1+ (4,0) [0|1000] "kPa" Vector__XXX
 SG_ DriveAxleLocation : 8|8@1+ (1,0) [0|255] "" Vector__XXX

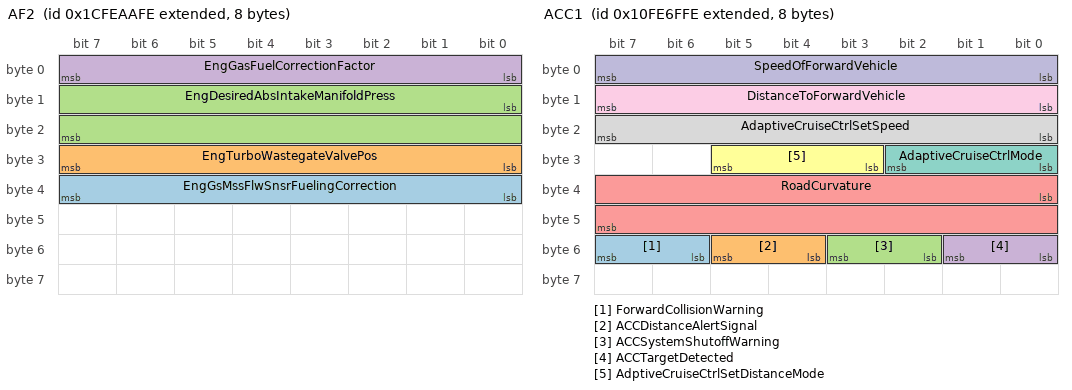
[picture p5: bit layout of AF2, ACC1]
BO_ 2633935614 AF2: 8 Vector__XXX
 SG_ EngGsMssFlwSnsrFuelingCorrection : 32|8@1+ (1,-125) [-125|125] "%" Vector__XXX
 SG_ EngTurboWastegateValvePos : 24|8@1+ (0.4,0) [0|100] "%" Vector__XXX
 SG_ EngDesiredAbsIntakeManifoldPress : 8|16@1+ (0.1,0) [0|6425.5] "kPa" Vector__XXX
 SG_ EngGasFuelCorrectionFactor : 0|8@1+ (1,0) [0|250] "%" Vector__XXX

BO_ 2566803966 ACC2: 8 Vector__XXX
 SG_ RequestedACCDistanceMode : 5|3@1+ (1,0) [0|7] "" Vector__XXX
 SG_ ACCUsageDemand : 0|2@1+ (1,0) [0|3] "" Vector__XXX

BO_ 2432593918 ACC1: 8 Vector__XXX
 SG_ ForwardCollisionWarning : 54|2@1+ (1,0) [0|3] "" Vector__XXX
 SG_ ACCDistanceAlertSignal : 52|2@1+ (1,0) [0|3] "" Vector__XXX
 SG_ ACCSystemShutoffWarning : 50|2@1+ (1,0) [0|3] "" Vector__XXX
 SG_ ACCTargetDetected : 48|2@1+ (1,0) [0|3] "" Vector__XXX
 SG_ RoadCurvature : 32|16@1+ (0.0078125,-250) [-250|251.992] "1/km" Vector__XXX
 SG_ AdptiveCruiseCtrlSetDistanceMode : 27|3@1+ (1,0) [0|7] "" Vector__XXX
 SG_ AdaptiveCruiseCtrlMode : 24|3@1+ (1,0) [0|7] "" Vector__XXX
 SG_ AdaptiveCruiseCtrlSetSpeed : 16|8@1+ (1,0) [0|250] "km/h" Vector__XXX
 SG_ DistanceToForwardVehicle : 8|8@1+ (1,0) [0|250] "m" Vector__XXX
 SG_ SpeedOfForwardVehicle : 0|8@1+ (1,0) [0|250] "km/h" Vector__XXX

BO_ 2633935102 ACTL: 8 Vector__XXX
 SG_ ArticulationAngle : 0|8@1+ (1,-125) [-125|125] "deg" Vector__XXX

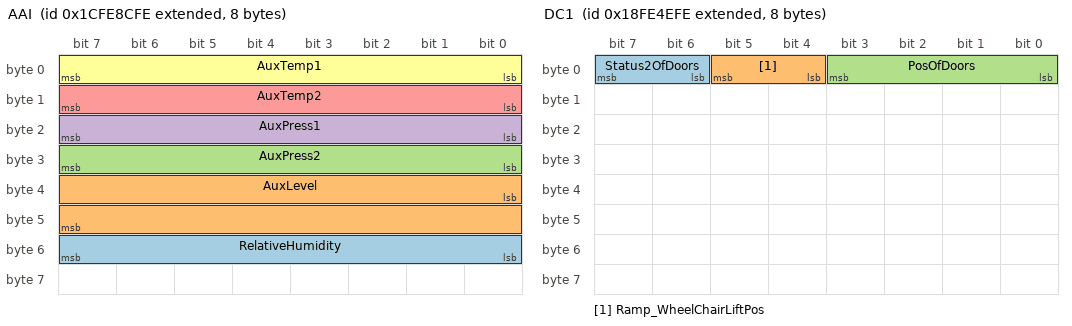
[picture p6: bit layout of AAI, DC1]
BO_ 2633927934 AAI: 8 Vector__XXX
 SG_ RelativeHumidity : 48|8@1+ (0.4,0) [0|100] "%" Vector__XXX
 SG_ AuxLevel : 32|16@1+ (0.1,0) [0|6425.5] "mm" Vector__XXX
 SG_ AuxPress2 : 24|8@1+ (16,0) [0|4000] "kPa" Vector__XXX
 SG_ AuxPress1 : 16|8@1+ (16,0) [0|4000] "kPa" Vector__XXX
 SG_ AuxTemp2 : 8|8@1+ (1,-40) [-40|210] "deg C" Vector__XXX
 SG_ AuxTemp1 : 0|8@1+ (1,-40) [-40|210] "deg C" Vector__XXX

BO_ 2566847998 A1: 8 Vector__XXX
 SG_ EngBlowerBypassValvePos : 0|8@1+ (0.4,0) [0|100] "%" Vector__XXX
 SG_ EngGasSupplyPress : 8|16@1+ (0.5,0) [0|32127.5] "kPa" Vector__XXX

BO_ 2565406462 ACKM: 8 Vector__XXX
 SG_ AddressBusy m3 : 32|8@1+ (1,0) [0|255] "" Vector__XXX
 SG_ ControlByte M : 0|8@1+ (1,0) [0|255] "" Vector__XXX
 SG_ ParameterGroupNumber : 40|24@1+ (1,0) [0|16777215] "" Vector__XXX
 SG_ GroupFunctionValue : 8|8@1+ (1,0) [0|255] "" Vector__XXX
 SG_ AddressAccessDenied m2 : 32|8@1+ (1,0) [0|255] "" Vector__XXX
 SG_ AddressNegativeAcknowledgement m1 : 32|8@1+ (1,0) [0|255] "" Vector__XXX
 SG_ AddressAcknowledged m0 : 32|8@1+ (1,0) [0|255] "" Vector__XXX

BO_ 2566803198 DC1: 8 Vector__XXX
 SG_ Status2OfDoors : 6|2@1+ (1,0) [0|3] "" Vector__XXX
 SG_ Ramp_WheelChairLiftPos : 4|2@1+ (1,0) [0|3] "" Vector__XXX
 SG_ PosOfDoors : 0|4@1+ (1,0) [0|15] "" Vector__XXX

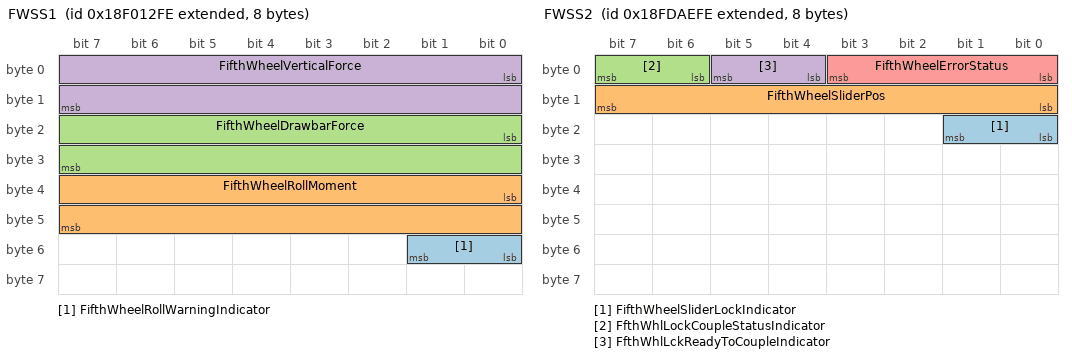
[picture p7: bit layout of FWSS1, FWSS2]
BO_ 2565870334 FWSS1: 8 Vector__XXX
 SG_ FifthWheelRollWarningIndicator : 48|2@1+ (1,0) [0|3] "" Vector__XXX
 SG_ FifthWheelRollMoment : 32|16@1+ (10,-320000) [-320000|322550] "N" Vector__XXX
 SG_ FifthWheelDrawbarForce : 16|16@1+ (10,-320000) [-320000|322550] "N" Vector__XXX
 SG_ FifthWheelVerticalForce : 0|16@1+ (5,0) [0|321275] "N" Vector__XXX

BO_ 2566762238 FWSS2: 8 Vector__XXX
 SG_ FifthWheelSliderLockIndicator : 16|2@1+ (1,0) [0|3] "" Vector__XXX
 SG_ FifthWheelSliderPos : 8|8@1+ (10,0) [0|2500] "mm" Vector__XXX
 SG_ FfthWhlLockCoupleStatusIndicator : 6|2@1+ (1,0) [0|3] "" Vector__XXX
 SG_ FfthWhlLckReadyToCoupleIndicator : 4|2@1+ (1,0) [0|3] "" Vector__XXX
 SG_ FifthWheelErrorStatus : 0|4@1+ (1,0) [0|15] "" Vector__XXX

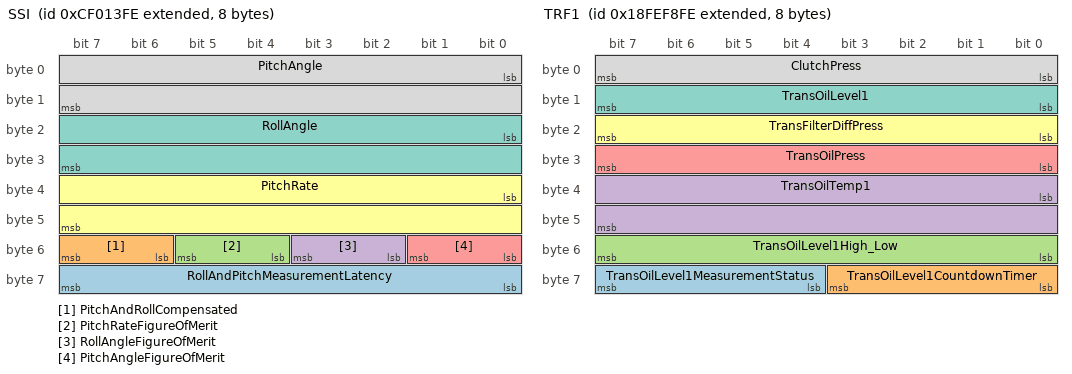
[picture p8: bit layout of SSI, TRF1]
BO_ 2364543998 SSI: 8 Vector__XXX
 SG_ RollAndPitchMeasurementLatency : 56|8@1+ (0.5,0) [0|125] "ms" Vector__XXX
 SG_ PitchAndRollCompensated : 54|2@1+ (1,0) [0|3] "" Vector__XXX
 SG_ PitchRateFigureOfMerit : 52|2@1+ (1,0) [0|3] "" Vector__XXX
 SG_ RollAngleFigureOfMerit : 50|2@1+ (1,0) [0|3] "" Vector__XXX
 SG_ PitchAngleFigureOfMerit : 48|2@1+ (1,0) [0|3] "" Vector__XXX
 SG_ PitchRate : 32|16@1+ (0.002,-64) [-64|64.51] "deg/sec" Vector__XXX
 SG_ RollAngle : 16|16@1+ (0.002,-64) [-64|64.51] "deg" Vector__XXX
 SG_ PitchAngle : 0|16@1+ (0.002,-64) [-64|64.51] "deg" Vector__XXX

BO_ 2566846718 TRF1: 8 Vector__XXX
 SG_ TransOilLevel1MeasurementStatus : 60|4@1+ (1,0) [0|15] "" Vector__XXX
 SG_ TransOilLevel1CountdownTimer : 56|4@1+ (1,0) [0|15] "" Vector__XXX
 SG_ TransOilLevel1High_Low : 48|8@1+ (0.5,-62.5) [-62.5|62.5] "L" Vector__XXX
 SG_ TransOilTemp1 : 32|16@1+ (0.03125,-273) [-273|1734.96875] "deg C" Vector__XXX
 SG_ TransOilPress : 24|8@1+ (16,0) [0|4000] "kPa" Vector__XXX
 SG_ TransFilterDiffPress : 16|8@1+ (2,0) [0|500] "kPa" Vector__XXX
 SG_ TransOilLevel1 : 8|8@1+ (0.4,0) [0|100] "%" Vector__XXX
 SG_ ClutchPress : 0|8@1+ (16,0) [0|4000] "kPa" Vector__XXX

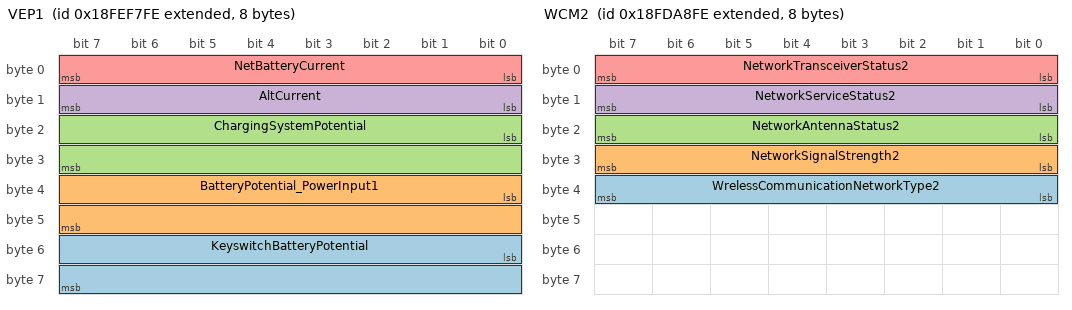
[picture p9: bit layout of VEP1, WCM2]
BO_ 2566846462 VEP1: 8 Vector__XXX
 SG_ KeyswitchBatteryPotential : 48|16@1+ (0.05,0) [0|3212.75] "V" Vector__XXX
 SG_ BatteryPotential_PowerInput1 : 32|16@1+ (0.05,0) [0|3212.75] "V" Vector__XXX
 SG_ ChargingSystemPotential : 16|16@1+ (0.05,0) [0|3212.75] "V" Vector__XXX
 SG_ AltCurrent : 8|8@1+ (1,0) [0|250] "A" Vector__XXX
 SG_ NetBatteryCurrent : 0|8@1+ (1,-125) [-125|125] "A" Vector__XXX

BO_ 2566760702 WCM2: 8 Vector__XXX
 SG_ WrelessCommunicationNetworkType2 : 32|8@1+ (1,0) [0|255] "" Vector__XXX
 SG_ NetworkSignalStrength2 : 24|8@1+ (0.4,0) [0|100] "%" Vector__XXX
 SG_ NetworkAntennaStatus2 : 16|8@1+ (1,0) [0|255] "" Vector__XXX
 SG_ NetworkServiceStatus2 : 8|8@1+ (1,0) [0|255] "" Vector__XXX
 SG_ NetworkTransceiverStatus2 : 0|8@1+ (1,0) [0|255] "" Vector__XXX

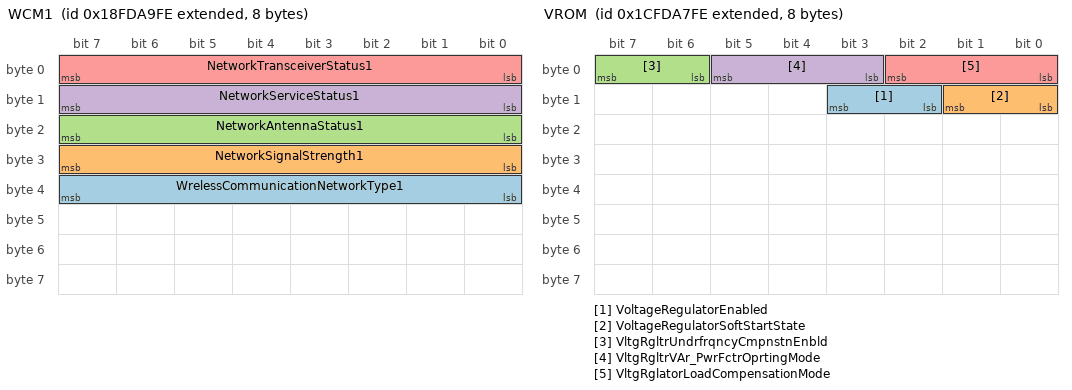
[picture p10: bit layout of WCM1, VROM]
BO_ 2566760958 WCM1: 8 Vector__XXX
 SG_ WrelessCommunicationNetworkType1 : 32|8@1+ (1,0) [0|255] "" Vector__XXX
 SG_ NetworkSignalStrength1 : 24|8@1+ (0.4,0) [0|100] "%" Vector__XXX
 SG_ NetworkAntennaStatus1 : 16|8@1+ (1,0) [0|255] "" Vector__XXX
 SG_ NetworkServiceStatus1 : 8|8@1+ (1,0) [0|255] "" Vector__XXX
 SG_ NetworkTransceiverStatus1 : 0|8@1+ (1,0) [0|255] "" Vector__XXX

BO_ 2633869310 VROM: 8 Vector__XXX
 SG_ VoltageRegulatorEnabled : 10|2@1+ (1,0) [0|3] "" Vector__XXX
 SG_ VoltageRegulatorSoftStartState : 8|2@1+ (1,0) [0|3] "" Vector__XXX
 SG_ VltgRgltrUndrfrqncyCmpnstnEnbld : 6|2@1+ (1,0) [0|3] "" Vector__XXX
 SG_ VltgRgltrVAr_PwrFctrOprtingMode : 3|3@1+ (1,0) [0|7] "" Vector__XXX
 SG_ VltgRglatorLoadCompensationMode : 0|3@1+ (1,0) [0|7] "" Vector__XXX

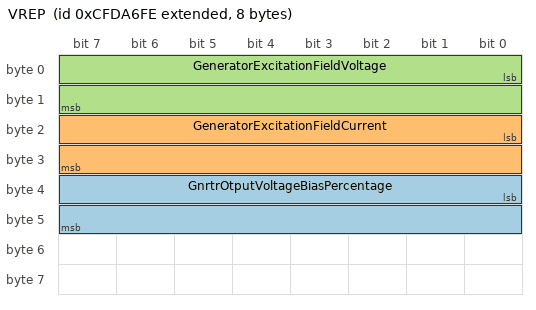
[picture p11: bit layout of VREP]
BO_ 2365433598 VREP: 8 Vector__XXX
 SG_ GnrtrOtputVoltageBiasPercentage : 32|16@1+ (0.1,-100) [-100|100] "%" Vector__XXX
 SG_ GeneratorExcitationFieldCurrent : 16|16@1+ (0.05,0) [0|3217.5] "A" Vector__XXX
 SG_ GeneratorExcitationFieldVoltage : 0|16@1+ (0.05,-1605.625) [-1605.625|1606.375] "V" Vector__XXX

CM_ BO_ 2563440382 "Transfer";
CM_ SG_ 2563440382 ShrtNameOfActualReportingDevice "Short name of reporting device of the requested PGN via the Transfer PGN.";
CM_ SG_ 2563440382 LengthOfDataForTheReportedPGN "Length of data reported with the associated PGN via the Transfer PGN.";
CM_ SG_ 2563440382 PGNofRequstedInformation "PGN associated with this transfer message";
CM_ BO_ 2632711934 "Transport Protocol - Data Transfer";
CM_ BO_ 2632777470 "Transport Protocol - Connection Management";
CM_ SG_ 2632777470 TotalNumberOfPacketsEoMA "Total number of packets for BAM message.Total number of packets received for RTS/CTS message.Total number of packets for RTS/CTS message.";
CM_ SG_ 2632777470 TotalMessageSizeEoMA "Total message size (in bytes) for BAM message.Total message size (in bytes) for RTS/CTS message.Total message size (in bytes) for RTS/CTS message.";
CM_ SG_ 2632777470 TotalMessageSizeBAM "Total message size (in bytes) for BAM message.Total message size (in bytes) for RTS/CTS message.Total message size (in bytes) for RTS/CTS message.";
CM_ SG_ 2632777470 TotalNumberOfPacketsBAM "Total number of packets for BAM message.Total number of packets received for RTS/CTS message.Total number of packets for RTS/CTS message.";
CM_ SG_ 2632777470 ConnectionAbortReason "Reason for connection abort message.";
CM_ SG_ 2632777470 NextPacketNumberToBeSent "Next Packet Number to be sent (TP.CM_CTS)";
CM_ SG_ 2632777470 NumberOfPacketsThatCanBeSent "Number of Packets that can be sent (TP.CM_CTS)";
CM_ SG_ 2632777470 MaximumNumberOfPackets "Maximum number of packets for RTS/CTS message.";
CM_ SG_ 2632777470 TotalNumberOfPackets "Total number of packets for BAM message.Total number of packets received for RTS/CTS message.Total number of packets for RTS/CTS message.";
CM_ SG_ 2632777470 TotalMessageSize "Total message size (in bytes) for BAM message.Total message size (in bytes) for RTS/CTS message.Total message size (in bytes) for RTS/CTS message.";
CM_ BO_ 2563374846 "Request 2";
CM_ SG_ 2563374846 UseTransferMode "Requester is to respond via the Transfer PGN";
CM_ SG_ 2563374846 ParameterGroupNumber "PGN which is requested by the Request message";
CM_ BO_ 2565537534 "Request";
CM_ SG_ 2565537534 ParameterGroupNumber "PGN which is requested by the Request message";
CM_ BO_ 2499635966 "Combination of specific axle group and the weight imposed on that axle group ...";
CM_ SG_ 2499635966 AxleGroupWeight "Total mass imposed on the road surface by all the tires in the axle group ...";
CM_ SG_ 2499635966 AxleGroupLocation "Specific axle group used in conjunction with and when communicating the axle group weight, listed from the front of the ...";
CM_ BO_ 2633853438 "Indicates axle group calibration weights ...";
CM_ SG_ 2633853438 AxleGroupFullWeightCalib "The full weight calibration measurement of an axle group ...";
CM_ SG_ 2633853438 AxleGroupEmptyWeightCalib "The empty weight calibration measurement of an axle group ...";
CM_ SG_ 2633853438 AxleGroupLocation "Specific axle group used in conjunction with and when communicating the axle group calibration, listed from the front of ...";
CM_ BO_ 2432520702 "Transmit status information from the Master ECU to an electronic thermostat ...";
CM_ SG_ 2432520702 DsrdAftrclrClntThermostatOpening "Used to transmit the desired position of the low temperature aftercooler temperature control valve.  0% represents the ...";
CM_ SG_ 2432520702 DsrdAftercoolerCoolantIntakeTemp "Indicates the desired temperature of the fluid in the low temperature aftercooler circuit to an electronic thermostat.  If the ...";
CM_ SG_ 2432520702 AftercoolerCoolantThermostatMode "Specifies if the aftercooler coolant thermostat valve will operate in temperature control mode or position control mode.";
CM_ BO_ 2566745086 "Indicates which axle groups are included in the current weight calculation ...";
CM_ SG_ 2566745086 AddtnlTrlrAxlGrupWeightAvailable "Indicates the availability of the additional trailer axle group for purposes of weight measurement ...";
CM_ SG_ 2566745086 TrailerHAxleGroupWeightAvailable "Indicates the availability of the trailer H axle group for purposes of weight measurement ...";
CM_ SG_ 2566745086 TrailerGAxleGroupWeightAvailable "Indicates the availability of the trailer G axle group for purposes of weight measurement ...";
CM_ SG_ 2566745086 TrailerFAxleGroupWeightAvailable "Indicates the availability of the trailer F axle group for purposes of weight measurement ...";
CM_ SG_ 2566745086 TrailerEAxleGroupWeightAvailable "Indicates the availability of the trailer E axle group for purposes of weight measurement ...";
CM_ SG_ 2566745086 TrailerDAxleGroupWeightAvailable "Indicates the availability of the trailer D axle group for purposes of weight measurement ...";
CM_ SG_ 2566745086 TrailerCAxleGroupWeightAvailable "Indicates the availability of the trailer C axle group for purposes of weight measurement ...";
CM_ SG_ 2566745086 TrailerBAxleGroupWeightAvailable "Indicates the availability of the trailer B axle group for purposes of weight measurement ...";
CM_ SG_ 2566745086 TrailerAAxleGroupWeightAvailable "Indicates the availability of the trailer A axle group for purposes of weight measurement ...";
CM_ SG_ 2566745086 AddtnlTrctrAxlGrpWeightAvailable "Indicates the availability of the additional tractor axle group for purposes of weight measurement ...";
CM_ SG_ 2566745086 TagAxleGroupWeightAvailable "Indicates the availability of the tag axle group for purposes of weight measurement ...";
CM_ SG_ 2566745086 DriveAxleGroupWeightAvailable "Indicates the availability of the drive axle group for purposes of weight measurement ...";
CM_ SG_ 2566745086 LiftAxleGroupWeightAvailable "Indicates the availability of the lift axle group for purposes of weight measurement ...";
CM_ SG_ 2566745086 SteerAxleGroupWeightAvailable "Indicates the availability of the steer axle group for purposes of weight measurement ...";
CM_ BO_ 2566739198 "Class C, Previously Active";
CM_ SG_ 2566739198 FlashRedStopLamp "This parameter provides the capability to flash the RSL (SPN 3039).";
CM_ SG_ 2566739198 FlashProtectLamp "This parameter provides the capability to flash the engine protect lamp (SPN 3041).";
CM_ SG_ 2566739198 FlashMalfuncIndicatorLamp "This parameter provides the capability to flash the MIL (SPN 3038).";
CM_ SG_ 2566739198 FlashAmberWarningLamp "This parameter provides the capability to flash the AWL (SPN 3040). ";
CM_ SG_ 2566739198 MalfunctionIndicatorLampStatus "A lamp used to relay only emissions-related trouble code information.";
CM_ SG_ 2566739198 AmberWarningLampStatus "This lamp is used to relay trouble code information that is reporting a problem with the vehicle system but the vehicle need
not be immediately stopped.";
CM_ SG_ 2566739198 RedStopLampState "This lamp is uesed to relay trouble code information that is of a severe enought condition that it warrants stopping the vehicle.";
CM_ SG_ 2566739198 ProtectLampStatus "This lamp is used to relay trouble code informatio that is reporting a problem with a vehicle system that is most
probably not electronic subsystem related.";
CM_ SG_ 2566739198 DTC5 "Diagnostic Trouble Code";
CM_ SG_ 2566739198 DTC4 "Diagnostic Trouble Code";
CM_ SG_ 2566739198 DTC3 "Diagnostic Trouble Code";
CM_ SG_ 2566739198 DTC2 "Diagnostic Trouble Code";
CM_ SG_ 2566739198 DTC1 "Diagnostic Trouble Code";
CM_ BO_ 2566739454 "Class C, Confirmed and Active";
CM_ SG_ 2566739454 FlashRedStopLamp "This parameter provides the capability to flash the RSL (SPN 3039).";
CM_ SG_ 2566739454 FlashProtectLamp "This parameter provides the capability to flash the engine protect lamp (SPN 3041).";
CM_ SG_ 2566739454 FlashMalfuncIndicatorLamp "This parameter provides the capability to flash the MIL (SPN 3038).";
CM_ SG_ 2566739454 FlashAmberWarningLamp "This parameter provides the capability to flash the AWL (SPN 3040). ";
CM_ SG_ 2566739454 MalfunctionIndicatorLampStatus "A lamp used to relay only emissions-related trouble code information.";
CM_ SG_ 2566739454 AmberWarningLampStatus "This lamp is used to relay trouble code information that is reporting a problem with the vehicle system but the vehicle need
not be immediately stopped.";
CM_ SG_ 2566739454 RedStopLampState "This lamp is uesed to relay trouble code information that is of a severe enought condition that it warrants stopping the vehicle.";
CM_ SG_ 2566739454 ProtectLampStatus "This lamp is used to relay trouble code informatio that is reporting a problem with a vehicle system that is most
probably not electronic subsystem related.";
CM_ SG_ 2566739454 DTC5 "Diagnostic Trouble Code";
CM_ SG_ 2566739454 DTC4 "Diagnostic Trouble Code";
CM_ SG_ 2566739454 DTC3 "Diagnostic Trouble Code";
CM_ SG_ 2566739454 DTC2 "Diagnostic Trouble Code";
CM_ SG_ 2566739454 DTC1 "Diagnostic Trouble Code";
CM_ BO_ 2566739710 "Class C, Pending";
CM_ SG_ 2566739710 FlashRedStopLamp "This parameter provides the capability to flash the RSL (SPN 3039).";
CM_ SG_ 2566739710 FlashProtectLamp "This parameter provides the capability to flash the engine protect lamp (SPN 3041).";
CM_ SG_ 2566739710 FlashMalfuncIndicatorLamp "This parameter provides the capability to flash the MIL (SPN 3038).";
CM_ SG_ 2566739710 FlashAmberWarningLamp "This parameter provides the capability to flash the AWL (SPN 3040). ";
CM_ SG_ 2566739710 MalfunctionIndicatorLampStatus "A lamp used to relay only emissions-related trouble code information.";
CM_ SG_ 2566739710 AmberWarningLampStatus "This lamp is used to relay trouble code information that is reporting a problem with the vehicle system but the vehicle need
not be immediately stopped.";
CM_ SG_ 2566739710 RedStopLampState "This lamp is uesed to relay trouble code information that is of a severe enought condition that it warrants stopping the vehicle.";
CM_ SG_ 2566739710 ProtectLampStatus "This lamp is used to relay trouble code informatio that is reporting a problem with a vehicle system that is most
probably not electronic subsystem related.";
CM_ SG_ 2566739710 DTC5 "Diagnostic Trouble Code";
CM_ SG_ 2566739710 DTC4 "Diagnostic Trouble Code";
CM_ SG_ 2566739710 DTC3 "Diagnostic Trouble Code";
CM_ SG_ 2566739710 DTC2 "Diagnostic Trouble Code";
CM_ SG_ 2566739710 DTC1 "Diagnostic Trouble Code";
CM_ BO_ 2566739966 "Class B2, Previously Active";
CM_ SG_ 2566739966 FlashRedStopLamp "This parameter provides the capability to flash the RSL (SPN 3039).";
CM_ SG_ 2566739966 FlashProtectLamp "This parameter provides the capability to flash the engine protect lamp (SPN 3041).";
CM_ SG_ 2566739966 FlashMalfuncIndicatorLamp "This parameter provides the capability to flash the MIL (SPN 3038).";
CM_ SG_ 2566739966 FlashAmberWarningLamp "This parameter provides the capability to flash the AWL (SPN 3040). ";
CM_ SG_ 2566739966 MalfunctionIndicatorLampStatus "A lamp used to relay only emissions-related trouble code information.";
CM_ SG_ 2566739966 AmberWarningLampStatus "This lamp is used to relay trouble code information that is reporting a problem with the vehicle system but the vehicle need
not be immediately stopped.";
CM_ SG_ 2566739966 RedStopLampState "This lamp is uesed to relay trouble code information that is of a severe enought condition that it warrants stopping the vehicle.";
CM_ SG_ 2566739966 ProtectLampStatus "This lamp is used to relay trouble code informatio that is reporting a problem with a vehicle system that is most
probably not electronic subsystem related.";
CM_ SG_ 2566739966 DTC5 "Diagnostic Trouble Code";
CM_ SG_ 2566739966 DTC4 "Diagnostic Trouble Code";
CM_ SG_ 2566739966 DTC3 "Diagnostic Trouble Code";
CM_ SG_ 2566739966 DTC2 "Diagnostic Trouble Code";
CM_ SG_ 2566739966 DTC1 "Diagnostic Trouble Code";
CM_ BO_ 2566740222 "Class B2, Confirmed and Active";
CM_ SG_ 2566740222 FlashRedStopLamp "This parameter provides the capability to flash the RSL (SPN 3039).";
CM_ SG_ 2566740222 FlashProtectLamp "This parameter provides the capability to flash the engine protect lamp (SPN 3041).";
CM_ SG_ 2566740222 FlashMalfuncIndicatorLamp "This parameter provides the capability to flash the MIL (SPN 3038).";
CM_ SG_ 2566740222 FlashAmberWarningLamp "This parameter provides the capability to flash the AWL (SPN 3040). ";
CM_ SG_ 2566740222 MalfunctionIndicatorLampStatus "A lamp used to relay only emissions-related trouble code information.";
CM_ SG_ 2566740222 AmberWarningLampStatus "This lamp is used to relay trouble code information that is reporting a problem with the vehicle system but the vehicle need
not be immediately stopped.";
CM_ SG_ 2566740222 RedStopLampState "This lamp is uesed to relay trouble code information that is of a severe enought condition that it warrants stopping the vehicle.";
CM_ SG_ 2566740222 ProtectLampStatus "This lamp is used to relay trouble code informatio that is reporting a problem with a vehicle system that is most
probably not electronic subsystem related.";
CM_ SG_ 2566740222 DTC5 "Diagnostic Trouble Code";
CM_ SG_ 2566740222 DTC4 "Diagnostic Trouble Code";
CM_ SG_ 2566740222 DTC3 "Diagnostic Trouble Code";
CM_ SG_ 2566740222 DTC2 "Diagnostic Trouble Code";
CM_ SG_ 2566740222 DTC1 "Diagnostic Trouble Code";
CM_ BO_ 2566740478 "Class B2, Pending";
CM_ SG_ 2566740478 FlashRedStopLamp "This parameter provides the capability to flash the RSL (SPN 3039).";
CM_ SG_ 2566740478 FlashProtectLamp "This parameter provides the capability to flash the engine protect lamp (SPN 3041).";
CM_ SG_ 2566740478 FlashMalfuncIndicatorLamp "This parameter provides the capability to flash the MIL (SPN 3038).";
CM_ SG_ 2566740478 FlashAmberWarningLamp "This parameter provides the capability to flash the AWL (SPN 3040). ";
CM_ SG_ 2566740478 MalfunctionIndicatorLampStatus "A lamp used to relay only emissions-related trouble code information.";
CM_ SG_ 2566740478 AmberWarningLampStatus "This lamp is used to relay trouble code information that is reporting a problem with the vehicle system but the vehicle need
not be immediately stopped.";
CM_ SG_ 2566740478 RedStopLampState "This lamp is uesed to relay trouble code information that is of a severe enought condition that it warrants stopping the vehicle.";
CM_ SG_ 2566740478 ProtectLampStatus "This lamp is used to relay trouble code informatio that is reporting a problem with a vehicle system that is most
probably not electronic subsystem related.";
CM_ SG_ 2566740478 DTC5 "Diagnostic Trouble Code";
CM_ SG_ 2566740478 DTC4 "Diagnostic Trouble Code";
CM_ SG_ 2566740478 DTC3 "Diagnostic Trouble Code";
CM_ SG_ 2566740478 DTC2 "Diagnostic Trouble Code";
CM_ SG_ 2566740478 DTC1 "Diagnostic Trouble Code";
CM_ BO_ 2566740734 "Class B1, Previously Active";
CM_ SG_ 2566740734 FlashRedStopLamp "This parameter provides the capability to flash the RSL (SPN 3039).";
CM_ SG_ 2566740734 FlashProtectLamp "This parameter provides the capability to flash the engine protect lamp (SPN 3041).";
CM_ SG_ 2566740734 FlashMalfuncIndicatorLamp "This parameter provides the capability to flash the MIL (SPN 3038).";
CM_ SG_ 2566740734 FlashAmberWarningLamp "This parameter provides the capability to flash the AWL (SPN 3040). ";
CM_ SG_ 2566740734 MalfunctionIndicatorLampStatus "A lamp used to relay only emissions-related trouble code information.";
CM_ SG_ 2566740734 AmberWarningLampStatus "This lamp is used to relay trouble code information that is reporting a problem with the vehicle system but the vehicle need
not be immediately stopped.";
CM_ SG_ 2566740734 RedStopLampState "This lamp is uesed to relay trouble code information that is of a severe enought condition that it warrants stopping the vehicle.";
CM_ SG_ 2566740734 ProtectLampStatus "This lamp is used to relay trouble code informatio that is reporting a problem with a vehicle system that is most
probably not electronic subsystem related.";
CM_ SG_ 2566740734 DTC5 "Diagnostic Trouble Code";
CM_ SG_ 2566740734 DTC4 "Diagnostic Trouble Code";
CM_ SG_ 2566740734 DTC3 "Diagnostic Trouble Code";
CM_ SG_ 2566740734 DTC2 "Diagnostic Trouble Code";
CM_ SG_ 2566740734 DTC1 "Diagnostic Trouble Code";
CM_ BO_ 2566740990 "Class B1, Confirmed and Active";
CM_ SG_ 2566740990 FlashRedStopLamp "This parameter provides the capability to flash the RSL (SPN 3039).";
CM_ SG_ 2566740990 FlashProtectLamp "This parameter provides the capability to flash the engine protect lamp (SPN 3041).";
CM_ SG_ 2566740990 FlashMalfuncIndicatorLamp "This parameter provides the capability to flash the MIL (SPN 3038).";
CM_ SG_ 2566740990 FlashAmberWarningLamp "This parameter provides the capability to flash the AWL (SPN 3040). ";
CM_ SG_ 2566740990 MalfunctionIndicatorLampStatus "A lamp used to relay only emissions-related trouble code information.";
CM_ SG_ 2566740990 AmberWarningLampStatus "This lamp is used to relay trouble code information that is reporting a problem with the vehicle system but the vehicle need
not be immediately stopped.";
CM_ SG_ 2566740990 RedStopLampState "This lamp is uesed to relay trouble code information that is of a severe enought condition that it warrants stopping the vehicle.";
CM_ SG_ 2566740990 ProtectLampStatus "This lamp is used to relay trouble code informatio that is reporting a problem with a vehicle system that is most
probably not electronic subsystem related.";
CM_ SG_ 2566740990 DTC5 "Diagnostic Trouble Code";
CM_ SG_ 2566740990 DTC4 "Diagnostic Trouble Code";
CM_ SG_ 2566740990 DTC3 "Diagnostic Trouble Code";
CM_ SG_ 2566740990 DTC2 "Diagnostic Trouble Code";
CM_ SG_ 2566740990 DTC1 "Diagnostic Trouble Code";
CM_ BO_ 2566741246 "Class B1, Pending";
CM_ SG_ 2566741246 FlashRedStopLamp "This parameter provides the capability to flash the RSL (SPN 3039).";
CM_ SG_ 2566741246 FlashProtectLamp "This parameter provides the capability to flash the engine protect lamp (SPN 3041).";
CM_ SG_ 2566741246 FlashMalfuncIndicatorLamp "This parameter provides the capability to flash the MIL (SPN 3038).";
CM_ SG_ 2566741246 FlashAmberWarningLamp "This parameter provides the capability to flash the AWL (SPN 3040). ";
CM_ SG_ 2566741246 MalfunctionIndicatorLampStatus "A lamp used to relay only emissions-related trouble code information.";
CM_ SG_ 2566741246 AmberWarningLampStatus "This lamp is used to relay trouble code information that is reporting a problem with the vehicle system but the vehicle need
not be immediately stopped.";
CM_ SG_ 2566741246 RedStopLampState "This lamp is uesed to relay trouble code information that is of a severe enought condition that it warrants stopping the vehicle.";
CM_ SG_ 2566741246 ProtectLampStatus "This lamp is used to relay trouble code informatio that is reporting a problem with a vehicle system that is most
probably not electronic subsystem related.";
CM_ SG_ 2566741246 DTC5 "Diagnostic Trouble Code";
CM_ SG_ 2566741246 DTC4 "Diagnostic Trouble Code";
CM_ SG_ 2566741246 DTC3 "Diagnostic Trouble Code";
CM_ SG_ 2566741246 DTC2 "Diagnostic Trouble Code";
CM_ SG_ 2566741246 DTC1 "Diagnostic Trouble Code";
CM_ BO_ 2566741502 "Class A, Previously Active";
CM_ SG_ 2566741502 FlashRedStopLamp "This parameter provides the capability to flash the RSL (SPN 3039).";
CM_ SG_ 2566741502 FlashProtectLamp "This parameter provides the capability to flash the engine protect lamp (SPN 3041).";
CM_ SG_ 2566741502 FlashMalfuncIndicatorLamp "This parameter provides the capability to flash the MIL (SPN 3038).";
CM_ SG_ 2566741502 FlashAmberWarningLamp "This parameter provides the capability to flash the AWL (SPN 3040). ";
CM_ SG_ 2566741502 MalfunctionIndicatorLampStatus "A lamp used to relay only emissions-related trouble code information.";
CM_ SG_ 2566741502 AmberWarningLampStatus "This lamp is used to relay trouble code information that is reporting a problem with the vehicle system but the vehicle need
not be immediately stopped.";
CM_ SG_ 2566741502 RedStopLampState "This lamp is uesed to relay trouble code information that is of a severe enought condition that it warrants stopping the vehicle.";
CM_ SG_ 2566741502 ProtectLampStatus "This lamp is used to relay trouble code informatio that is reporting a problem with a vehicle system that is most
probably not electronic subsystem related.";
CM_ SG_ 2566741502 DTC5 "Diagnostic Trouble Code";
CM_ SG_ 2566741502 DTC4 "Diagnostic Trouble Code";
CM_ SG_ 2566741502 DTC3 "Diagnostic Trouble Code";
CM_ SG_ 2566741502 DTC2 "Diagnostic Trouble Code";
CM_ SG_ 2566741502 DTC1 "Diagnostic Trouble Code";
CM_ BO_ 2566741758 "Class A, Confirmed and Active";
CM_ SG_ 2566741758 FlashRedStopLamp "This parameter provides the capability to flash the RSL (SPN 3039).";
CM_ SG_ 2566741758 FlashProtectLamp "This parameter provides the capability to flash the engine protect lamp (SPN 3041).";
CM_ SG_ 2566741758 FlashMalfuncIndicatorLamp "This parameter provides the capability to flash the MIL (SPN 3038).";
CM_ SG_ 2566741758 FlashAmberWarningLamp "This parameter provides the capability to flash the AWL (SPN 3040). ";
CM_ SG_ 2566741758 MalfunctionIndicatorLampStatus "A lamp used to relay only emissions-related trouble code information.";
CM_ SG_ 2566741758 AmberWarningLampStatus "This lamp is used to relay trouble code information that is reporting a problem with the vehicle system but the vehicle need
not be immediately stopped.";
CM_ SG_ 2566741758 RedStopLampState "This lamp is uesed to relay trouble code information that is of a severe enought condition that it warrants stopping the vehicle.";
CM_ SG_ 2566741758 ProtectLampStatus "This lamp is used to relay trouble code informatio that is reporting a problem with a vehicle system that is most
probably not electronic subsystem related.";
CM_ SG_ 2566741758 DTC5 "Diagnostic Trouble Code";
CM_ SG_ 2566741758 DTC4 "Diagnostic Trouble Code";
CM_ SG_ 2566741758 DTC3 "Diagnostic Trouble Code";
CM_ SG_ 2566741758 DTC2 "Diagnostic Trouble Code";
CM_ SG_ 2566741758 DTC1 "Diagnostic Trouble Code";
CM_ BO_ 2566742014 "Class A, Pending";
CM_ SG_ 2566742014 FlashRedStopLamp "This parameter provides the capability to flash the RSL (SPN 3039).";
CM_ SG_ 2566742014 FlashProtectLamp "This parameter provides the capability to flash the engine protect lamp (SPN 3041).";
CM_ SG_ 2566742014 FlashMalfuncIndicatorLamp "This parameter provides the capability to flash the MIL (SPN 3038).";
CM_ SG_ 2566742014 FlashAmberWarningLamp "This parameter provides the capability to flash the AWL (SPN 3040). ";
CM_ SG_ 2566742014 MalfunctionIndicatorLampStatus "A lamp used to relay only emissions-related trouble code information.";
CM_ SG_ 2566742014 AmberWarningLampStatus "This lamp is used to relay trouble code information that is reporting a problem with the vehicle system but the vehicle need
not be immediately stopped.";
CM_ SG_ 2566742014 RedStopLampState "This lamp is uesed to relay trouble code information that is of a severe enought condition that it warrants stopping the vehicle.";
CM_ SG_ 2566742014 ProtectLampStatus "This lamp is used to relay trouble code informatio that is reporting a problem with a vehicle system that is most
probably not electronic subsystem related.";
CM_ SG_ 2566742014 DTC5 "Diagnostic Trouble Code";
CM_ SG_ 2566742014 DTC4 "Diagnostic Trouble Code";
CM_ SG_ 2566742014 DTC3 "Diagnostic Trouble Code";
CM_ SG_ 2566742014 DTC2 "Diagnostic Trouble Code";
CM_ SG_ 2566742014 DTC1 "Diagnostic Trouble Code";
CM_ BO_ 2560622334 "Immediate Fault Status ";
CM_ SG_ 2560622334 FlashRedStopLamp "This parameter provides the capability to flash the RSL (SPN 3039).";
CM_ SG_ 2560622334 FlashProtectLamp "This parameter provides the capability to flash the engine protect lamp (SPN 3041).";
CM_ SG_ 2560622334 FlashMalfuncIndicatorLamp "This parameter provides the capability to flash the MIL (SPN 3038).";
CM_ SG_ 2560622334 FlashAmberWarningLamp "This parameter provides the capability to flash the AWL (SPN 3040). ";
CM_ SG_ 2560622334 MalfunctionIndicatorLampStatus "A lamp used to relay only emissions-related trouble code information.";
CM_ SG_ 2560622334 AmberWarningLampStatus "This lamp is used to relay trouble code information that is reporting a problem with the vehicle system but the vehicle need
not be immediately stopped.";
CM_ SG_ 2560622334 RedStopLampState "This lamp is uesed to relay trouble code information that is of a severe enought condition that it warrants stopping the vehicle.";
CM_ SG_ 2560622334 ProtectLampStatus "This lamp is used to relay trouble code informatio that is reporting a problem with a vehicle system that is most
probably not electronic subsystem related.";
CM_ SG_ 2560622334 DTC5 "Diagnostic Trouble Code";
CM_ SG_ 2560622334 DTC4 "Diagnostic Trouble Code";
CM_ SG_ 2560622334 DTC3 "Diagnostic Trouble Code";
CM_ SG_ 2560622334 DTC2 "Diagnostic Trouble Code";
CM_ SG_ 2560622334 DTC1 "Diagnostic Trouble Code";
CM_ BO_ 2566744062 "Zero Net Vehicle Weight Change ...";
CM_ SG_ 2566744062 ZeroNetVehicleWeightChange "Zero Net Vehicle Weight Change command.  A controller receiving this command will record the current Gross ...";
CM_ BO_ 2499630078 "Reports averaged engine information ...";
CM_ SG_ 2499630078 EngExhaustGasTempAverageBank2 "The calculated average temperature based upon all of the Bank 2 (right bank) engine exhaust port temperatures.  This is ...";
CM_ SG_ 2499630078 EngExhaustGasTempAverageBank1 "The calculated average temperature based upon all of the Bank 1 (left bank) engine exhaust port temperatures.  This is ...";
CM_ SG_ 2499630078 EngExhaustGasTempAverage "The calculated average temperature based upon all of the engine exhaust port temperatures.  This is the average ...";
CM_ BO_ 2560556798 "DTC Counts";
CM_ SG_ 2560556798 PermanentDTCs "Identifies the current number of permanent DTCs";
CM_ SG_ 2560556798 PreviouslyMILOnDTCs "Identifies the current number of previously MIL-On DTCs";
CM_ SG_ 2560556798 MILOnDTCs "Identifies the current number of MIL-On DTCs";
CM_ SG_ 2560556798 AllPendingDTCs "Identifies the current total number of pending DTCs, including emission related";
CM_ SG_ 2560556798 PendingDTCs "Identifies the current number of emission related pending DTCs";
CM_ BO_ 2566750462 "Permanent DTCs";
CM_ SG_ 2566750462 FlashRedStopLamp "This parameter provides the capability to flash the RSL (SPN 3039).";
CM_ SG_ 2566750462 FlashProtectLamp "This parameter provides the capability to flash the engine protect lamp (SPN 3041).";
CM_ SG_ 2566750462 FlashMalfuncIndicatorLamp "This parameter provides the capability to flash the MIL (SPN 3038).";
CM_ SG_ 2566750462 FlashAmberWarningLamp "This parameter provides the capability to flash the AWL (SPN 3040). ";
CM_ SG_ 2566750462 MalfunctionIndicatorLampStatus "A lamp used to relay only emissions-related trouble code information.";
CM_ SG_ 2566750462 AmberWarningLampStatus "This lamp is used to relay trouble code information that is reporting a problem with the vehicle system but the vehicle need
not be immediately stopped.";
CM_ SG_ 2566750462 RedStopLampState "This lamp is uesed to relay trouble code information that is of a severe enought condition that it warrants stopping the vehicle.";
CM_ SG_ 2566750462 ProtectLampStatus "This lamp is used to relay trouble code informatio that is reporting a problem with a vehicle system that is most
probably not electronic subsystem related.";
CM_ SG_ 2566750462 DTC5 "Diagnostic Trouble Code";
CM_ SG_ 2566750462 DTC4 "Diagnostic Trouble Code";
CM_ SG_ 2566750462 DTC3 "Diagnostic Trouble Code";
CM_ SG_ 2566750462 DTC2 "Diagnostic Trouble Code";
CM_ SG_ 2566750462 DTC1 "Diagnostic Trouble Code";
CM_ BO_ 2566750974 "All Pending DTCs";
CM_ SG_ 2566750974 FlashRedStopLamp "This parameter provides the capability to flash the RSL (SPN 3039).";
CM_ SG_ 2566750974 FlashProtectLamp "This parameter provides the capability to flash the engine protect lamp (SPN 3041).";
CM_ SG_ 2566750974 FlashMalfuncIndicatorLamp "This parameter provides the capability to flash the MIL (SPN 3038).";
CM_ SG_ 2566750974 FlashAmberWarningLamp "This parameter provides the capability to flash the AWL (SPN 3040). ";
CM_ SG_ 2566750974 MalfunctionIndicatorLampStatus "A lamp used to relay only emissions-related trouble code information.";
CM_ SG_ 2566750974 AmberWarningLampStatus "This lamp is used to relay trouble code information that is reporting a problem with the vehicle system but the vehicle need
not be immediately stopped.";
CM_ SG_ 2566750974 RedStopLampState "This lamp is uesed to relay trouble code information that is of a severe enought condition that it warrants stopping the vehicle.";
CM_ SG_ 2566750974 ProtectLampStatus "This lamp is used to relay trouble code informatio that is reporting a problem with a vehicle system that is most
probably not electronic subsystem related.";
CM_ SG_ 2566750974 DTC5 "Diagnostic Trouble Code";
CM_ SG_ 2566750974 DTC4 "Diagnostic Trouble Code";
CM_ SG_ 2566750974 DTC3 "Diagnostic Trouble Code";
CM_ SG_ 2566750974 DTC2 "Diagnostic Trouble Code";
CM_ SG_ 2566750974 DTC1 "Diagnostic Trouble Code";
CM_ BO_ 2566754558 "This message conveys the advertised torque curve for the engine, as typically seen on specification sheets available from ...";
CM_ SG_ 2566754558 AETCTorqueValue14 "Engine torque value of the data points in PGN 64912 – Advertised Engine Torque Curve (AETC).";
CM_ SG_ 2566754558 AETCTorqueValue13 "Engine torque value of the data points in PGN 64912 – Advertised Engine Torque Curve (AETC).";
CM_ SG_ 2566754558 AETCTorqueValue12 "Engine torque value of the data points in PGN 64912 – Advertised Engine Torque Curve (AETC).";
CM_ SG_ 2566754558 AETCTorqueValue11 "Engine torque value of the data points in PGN 64912 – Advertised Engine Torque Curve (AETC).";
CM_ SG_ 2566754558 AETCTorqueValue10 "Engine torque value of the data points in PGN 64912 – Advertised Engine Torque Curve (AETC).";
CM_ SG_ 2566754558 AETCTorqueValue09 "Engine torque value of the data points in PGN 64912 – Advertised Engine Torque Curve (AETC).";
CM_ SG_ 2566754558 AETCTorqueValue08 "Engine torque value of the data points in PGN 64912 – Advertised Engine Torque Curve (AETC).";
CM_ SG_ 2566754558 AETCTorqueValue07 "Engine torque value of the data points in PGN 64912 – Advertised Engine Torque Curve (AETC).";
CM_ SG_ 2566754558 AETCTorqueValue06 "Engine torque value of the data points in PGN 64912 – Advertised Engine Torque Curve (AETC).";
CM_ SG_ 2566754558 AETCTorqueValue05 "Engine torque value of the data points in PGN 64912 – Advertised Engine Torque Curve (AETC).";
CM_ SG_ 2566754558 AETCTorqueValue04 "Engine torque value of the data points in PGN 64912 – Advertised Engine Torque Curve (AETC).";
CM_ SG_ 2566754558 AETCTorqueValue03 "Engine torque value of the data points in PGN 64912 – Advertised Engine Torque Curve (AETC).";
CM_ SG_ 2566754558 AETCTorqueValue02 "Engine torque value of the data points in PGN 64912 – Advertised Engine Torque Curve (AETC).";
CM_ SG_ 2566754558 AETCTorqueValue01 "Engine torque value of the data points in PGN 64912 – Advertised Engine Torque Curve (AETC).";
CM_ SG_ 2566754558 AETCSpeedValue14 "Engine speed value of the data points in PGN 64912 – Advertised Engine Torque Curve (AETC).";
CM_ SG_ 2566754558 AETCSpeedValue13 "Engine speed value of the data points in PGN 64912 – Advertised Engine Torque Curve (AETC).";
CM_ SG_ 2566754558 AETCSpeedValue12 "Engine speed value of the data points in PGN 64912 – Advertised Engine Torque Curve (AETC).";
CM_ SG_ 2566754558 AETCSpeedValue11 "Engine speed value of the data points in PGN 64912 – Advertised Engine Torque Curve (AETC).";
CM_ SG_ 2566754558 AETCSpeedValue10 "Engine speed value of the data points in PGN 64912 – Advertised Engine Torque Curve (AETC).";
CM_ SG_ 2566754558 AETCSpeedValue09 "Engine speed value of the data points in PGN 64912 – Advertised Engine Torque Curve (AETC).";
CM_ SG_ 2566754558 AETCSpeedValue08 "Engine speed value of the data points in PGN 64912 – Advertised Engine Torque Curve (AETC).";
CM_ SG_ 2566754558 AETCSpeedValue07 "Engine speed value of the data points in PGN 64912 – Advertised Engine Torque Curve (AETC).";
CM_ SG_ 2566754558 AETCSpeedValue06 "Engine speed value of the data points in PGN 64912 – Advertised Engine Torque Curve (AETC).";
CM_ SG_ 2566754558 AETCSpeedValue05 "Engine speed value of the data points in PGN 64912 – Advertised Engine Torque Curve (AETC).";
CM_ SG_ 2566754558 AETCSpeedValue04 "Engine speed value of the data points in PGN 64912 – Advertised Engine Torque Curve (AETC).";
CM_ SG_ 2566754558 AETCSpeedValue03 "Engine speed value of the data points in PGN 64912 – Advertised Engine Torque Curve (AETC).";
CM_ SG_ 2566754558 AETCSpeedValue02 "Engine speed value of the data points in PGN 64912 – Advertised Engine Torque Curve (AETC).";
CM_ SG_ 2566754558 AETCSpeedValue01 "Engine speed value of the data points in PGN 64912 – Advertised Engine Torque Curve (AETC).";
CM_ SG_ 2566754558 AETCTorqueValue00 "Engine torque value of the data points in PGN 64912 – Advertised Engine Torque Curve (AETC).";
CM_ SG_ 2566754558 AETCSpeedValue00 "Engine speed value of the data points in PGN 64912 – Advertised Engine Torque Curve (AETC).";
CM_ SG_ 2566754558 NumberOfAETCDataPoints "Indicates the number of speed / torque data points contained in the Advertised Engine Torque Curve broadcast (AETC).";
CM_ SG_ 2566754558 AETCDataCollectionStandard "Indicates the standardized method by which torque data was obtained for the Advertised Engine Torque Curve (AETC).";
CM_ BO_ 2566749950 "This message reports information about the current operation mode of the Adaptive Front-Lighting System (AFS). The ...";
CM_ SG_ 2566749950 RightHeadlampLightDistribution "This parameter indicates what kind of light distribution is set by the AFS system for the right headlamp.";
CM_ SG_ 2566749950 LeftHeadlampLightDistribution "This parameter indicates what kind of light distribution is set by the AFS system for the left headlamp.";
CM_ SG_ 2566749950 RightHeadlampDynamicBendingLight "This parameter indicates whether the dynamic bending light of the left headlamp is working properly.";
CM_ SG_ 2566749950 LeftHeadlampDynamicBendingLight "This parameter indicates whether the dynamic bending light of the left headlamp is working properly.";
CM_ BO_ 2566838782 "Notes: Implementers are encouraged to use specific functional SPNs whenever possible.";
CM_ SG_ 2566838782 AuxI_OChannel2 "Auxiliary channel of data (16 bit) read by the ECU.  This data is in A/D counts and is manufacturer specific.  It may be ...";
CM_ SG_ 2566838782 AuxI_OChannel1 "Auxiliary channel of data (16 bit) read by the ECU.  This data is in A/D counts and is manufacturer specific.  It may be ...";
CM_ SG_ 2566838782 AuxI_O13 "Identifies the current status of auxiliary input/output functions that are configured uniquely per application.";
CM_ SG_ 2566838782 AuxI_O14 "Identifies the current status of auxiliary input/output functions that are configured uniquely per application.";
CM_ SG_ 2566838782 AuxI_O15 "Identifies the current status of auxiliary input/output functions that are configured uniquely per application.";
CM_ SG_ 2566838782 AuxI_O16 "Identifies the current status of auxiliary input/output functions that are configured uniquely per application.";
CM_ SG_ 2566838782 AuxI_O09 "Identifies the current status of auxiliary input/output functions that are configured uniquely per application.";
CM_ SG_ 2566838782 AuxI_O10 "Identifies the current status of auxiliary input/output functions that are configured uniquely per application.";
CM_ SG_ 2566838782 AuxI_O11 "Identifies the current status of auxiliary input/output functions that are configured uniquely per application.";
CM_ SG_ 2566838782 AuxI_O12 "Identifies the current status of auxiliary input/output functions that are configured uniquely per application.";
CM_ SG_ 2566838782 AuxI_O05 "Identifies the current status of auxiliary input/output functions that are configured uniquely per application.";
CM_ SG_ 2566838782 AuxI_O06 "Identifies the current status of auxiliary input/output functions that are configured uniquely per application.";
CM_ SG_ 2566838782 AuxI_O07 "Identifies the current status of auxiliary input/output functions that are configured uniquely per application.";
CM_ SG_ 2566838782 AuxI_O08 "Identifies the current status of auxiliary input/output functions that are configured uniquely per application.";
CM_ SG_ 2566838782 AuxI_O01 "Identifies the current status of auxiliary input/output functions that are configured uniquely per application.";
CM_ SG_ 2566838782 AuxI_O02 "Identifies the current status of auxiliary input/output functions that are configured uniquely per application.";
CM_ SG_ 2566838782 AuxI_O03 "Identifies the current status of auxiliary input/output functions that are configured uniquely per application.";
CM_ SG_ 2566838782 AuxI_O04 "Identifies the current status of auxiliary input/output functions that are configured uniquely per application.";
CM_ BO_ 2561146622 "Notes: Implementers are encouraged to use specific functional SPNs whenever possible.";
CM_ SG_ 2561146622 AuxI_O45 "Identifies the current status of auxiliary input/output functions that are configured uniquely per application.";
CM_ SG_ 2561146622 AuxI_O46 "Identifies the current status of auxiliary input/output functions that are configured uniquely per application.";
CM_ SG_ 2561146622 AuxI_O47 "Identifies the current status of auxiliary input/output functions that are configured uniquely per application.";
CM_ SG_ 2561146622 AuxI_O48 "Identifies the current status of auxiliary input/output functions that are configured uniquely per application.";
CM_ SG_ 2561146622 AuxI_O41 "Identifies the current status of auxiliary input/output functions that are configured uniquely per application.";
CM_ SG_ 2561146622 AuxI_O42 "Identifies the current status of auxiliary input/output functions that are configured uniquely per application.";
CM_ SG_ 2561146622 AuxI_O43 "Identifies the current status of auxiliary input/output functions that are configured uniquely per application.";
CM_ SG_ 2561146622 AuxI_O44 "Identifies the current status of auxiliary input/output functions that are configured uniquely per application.";
CM_ SG_ 2561146622 AuxI_O37 "Identifies the current status of auxiliary input/output functions that are configured uniquely per application.";
CM_ SG_ 2561146622 AuxI_O38 "Identifies the current status of auxiliary input/output functions that are configured uniquely per application.";
CM_ SG_ 2561146622 AuxI_O39 "Identifies the current status of auxiliary input/output functions that are configured uniquely per application.";
CM_ SG_ 2561146622 AuxI_O40 "Identifies the current status of auxiliary input/output functions that are configured uniquely per application.";
CM_ SG_ 2561146622 AuxI_O33 "Identifies the current status of auxiliary input/output functions that are configured uniquely per application.";
CM_ SG_ 2561146622 AuxI_O34 "Identifies the current status of auxiliary input/output functions that are configured uniquely per application.";
CM_ SG_ 2561146622 AuxI_O35 "Identifies the current status of auxiliary input/output functions that are configured uniquely per application.";
CM_ SG_ 2561146622 AuxI_O36 "Identifies the current status of auxiliary input/output functions that are configured uniquely per application.";
CM_ SG_ 2561146622 AuxI_O29 "Identifies the current status of auxiliary input/output functions that are configured uniquely per application.";
CM_ SG_ 2561146622 AuxI_O30 "Identifies the current status of auxiliary input/output functions that are configured uniquely per application.";
CM_ SG_ 2561146622 AuxI_O31 "Identifies the current status of auxiliary input/output functions that are configured uniquely per application.";
CM_ SG_ 2561146622 AuxI_O32 "Identifies the current status of auxiliary input/output functions that are configured uniquely per application.";
CM_ SG_ 2561146622 AuxI_O25 "Identifies the current status of auxiliary input/output functions that are configured uniquely per application.";
CM_ SG_ 2561146622 AuxI_O26 "Identifies the current status of auxiliary input/output functions that are configured uniquely per application.";
CM_ SG_ 2561146622 AuxI_O27 "Identifies the current status of auxiliary input/output functions that are configured uniquely per application.";
CM_ SG_ 2561146622 AuxI_O28 "Identifies the current status of auxiliary input/output functions that are configured uniquely per application.";
CM_ SG_ 2561146622 AuxI_O21 "Identifies the current status of auxiliary input/output functions that are configured uniquely per application.";
CM_ SG_ 2561146622 AuxI_O22 "Identifies the current status of auxiliary input/output functions that are configured uniquely per application.";
CM_ SG_ 2561146622 AuxI_O23 "Identifies the current status of auxiliary input/output functions that are configured uniquely per application.";
CM_ SG_ 2561146622 AuxI_O24 "Identifies the current status of auxiliary input/output functions that are configured uniquely per application.";
CM_ SG_ 2561146622 AuxI_O17 "Identifies the current status of auxiliary input/output functions that are configured uniquely per application.";
CM_ SG_ 2561146622 AuxI_O18 "Identifies the current status of auxiliary input/output functions that are configured uniquely per application.";
CM_ SG_ 2561146622 AuxI_O19 "Identifies the current status of auxiliary input/output functions that are configured uniquely per application.";
CM_ SG_ 2561146622 AuxI_O20 "Identifies the current status of auxiliary input/output functions that are configured uniquely per application.";
CM_ BO_ 2561081086 "Notes: Implementers are encouraged to use specific functional SPNs whenever possible.";
CM_ SG_ 2561081086 AuxI_O77 "Identifies the current status of auxiliary input/output functions that are configured uniquely per application.";
CM_ SG_ 2561081086 AuxI_O78 "Identifies the current status of auxiliary input/output functions that are configured uniquely per application.";
CM_ SG_ 2561081086 AuxI_O79 "Identifies the current status of auxiliary input/output functions that are configured uniquely per application.";
CM_ SG_ 2561081086 AuxI_O80 "Identifies the current status of auxiliary input/output functions that are configured uniquely per application.";
CM_ SG_ 2561081086 AuxI_O73 "Identifies the current status of auxiliary input/output functions that are configured uniquely per application.";
CM_ SG_ 2561081086 AuxI_O74 "Identifies the current status of auxiliary input/output functions that are configured uniquely per application.";
CM_ SG_ 2561081086 AuxI_O75 "Identifies the current status of auxiliary input/output functions that are configured uniquely per application.";
CM_ SG_ 2561081086 AuxI_O76 "Identifies the current status of auxiliary input/output functions that are configured uniquely per application.";
CM_ SG_ 2561081086 AuxI_O69 "Identifies the current status of auxiliary input/output functions that are configured uniquely per application.";
CM_ SG_ 2561081086 AuxI_O70 "Identifies the current status of auxiliary input/output functions that are configured uniquely per application.";
CM_ SG_ 2561081086 AuxI_O71 "Identifies the current status of auxiliary input/output functions that are configured uniquely per application.";
CM_ SG_ 2561081086 AuxI_O72 "Identifies the current status of auxiliary input/output functions that are configured uniquely per application.";
CM_ SG_ 2561081086 AuxI_O65 "Identifies the current status of auxiliary input/output functions that are configured uniquely per application.";
CM_ SG_ 2561081086 AuxI_O66 "Identifies the current status of auxiliary input/output functions that are configured uniquely per application.";
CM_ SG_ 2561081086 AuxI_O67 "Identifies the current status of auxiliary input/output functions that are configured uniquely per application.";
CM_ SG_ 2561081086 AuxI_O68 "Identifies the current status of auxiliary input/output functions that are configured uniquely per application.";
CM_ SG_ 2561081086 AuxI_O61 "Identifies the current status of auxiliary input/output functions that are configured uniquely per application.";
CM_ SG_ 2561081086 AuxI_O62 "Identifies the current status of auxiliary input/output functions that are configured uniquely per application.";
CM_ SG_ 2561081086 AuxI_O63 "Identifies the current status of auxiliary input/output functions that are configured uniquely per application.";
CM_ SG_ 2561081086 AuxI_O64 "Identifies the current status of auxiliary input/output functions that are configured uniquely per application.";
CM_ SG_ 2561081086 AuxI_O57 "Identifies the current status of auxiliary input/output functions that are configured uniquely per application.";
CM_ SG_ 2561081086 AuxI_O58 "Identifies the current status of auxiliary input/output functions that are configured uniquely per application.";
CM_ SG_ 2561081086 AuxI_O59 "Identifies the current status of auxiliary input/output functions that are configured uniquely per application.";
CM_ SG_ 2561081086 AuxI_O60 "Identifies the current status of auxiliary input/output functions that are configured uniquely per application.";
CM_ SG_ 2561081086 AuxI_O53 "Identifies the current status of auxiliary input/output functions that are configured uniquely per application.";
CM_ SG_ 2561081086 AuxI_O54 "Identifies the current status of auxiliary input/output functions that are configured uniquely per application.";
CM_ SG_ 2561081086 AuxI_O55 "Identifies the current status of auxiliary input/output functions that are configured uniquely per application.";
CM_ SG_ 2561081086 AuxI_O56 "Identifies the current status of auxiliary input/output functions that are configured uniquely per application.";
CM_ SG_ 2561081086 AuxI_O49 "Identifies the current status of auxiliary input/output functions that are configured uniquely per application.";
CM_ SG_ 2561081086 AuxI_O50 "Identifies the current status of auxiliary input/output functions that are configured uniquely per application.";
CM_ SG_ 2561081086 AuxI_O51 "Identifies the current status of auxiliary input/output functions that are configured uniquely per application.";
CM_ SG_ 2561081086 AuxI_O52 "Identifies the current status of auxiliary input/output functions that are configured uniquely per application.";
CM_ BO_ 2561015550 "Notes: Implementers are encouraged to use specific functional SPNs whenever possible.";
CM_ SG_ 2561015550 AuxI_O109 "Identifies the current status of auxiliary input/output functions that are configured uniquely per application.";
CM_ SG_ 2561015550 AuxI_O110 "Identifies the current status of auxiliary input/output functions that are configured uniquely per application.";
CM_ SG_ 2561015550 AuxI_O111 "Identifies the current status of auxiliary input/output functions that are configured uniquely per application.";
CM_ SG_ 2561015550 AuxI_O112 "Identifies the current status of auxiliary input/output functions that are configured uniquely per application.";
CM_ SG_ 2561015550 AuxI_O105 "Identifies the current status of auxiliary input/output functions that are configured uniquely per application.";
CM_ SG_ 2561015550 AuxI_O106 "Identifies the current status of auxiliary input/output functions that are configured uniquely per application.";
CM_ SG_ 2561015550 AuxI_O107 "Identifies the current status of auxiliary input/output functions that are configured uniquely per application.";
CM_ SG_ 2561015550 AuxI_O108 "Identifies the current status of auxiliary input/output functions that are configured uniquely per application.";
CM_ SG_ 2561015550 AuxI_O101 "Identifies the current status of auxiliary input/output functions that are configured uniquely per application.";
CM_ SG_ 2561015550 AuxI_O102 "Identifies the current status of auxiliary input/output functions that are configured uniquely per application.";
CM_ SG_ 2561015550 AuxI_O103 "Identifies the current status of auxiliary input/output functions that are configured uniquely per application.";
CM_ SG_ 2561015550 AuxI_O104 "Identifies the current status of auxiliary input/output functions that are configured uniquely per application.";
CM_ SG_ 2561015550 AuxI_O97 "Identifies the current status of auxiliary input/output functions that are configured uniquely per application.";
CM_ SG_ 2561015550 AuxI_O98 "Identifies the current status of auxiliary input/output functions that are configured uniquely per application.";
CM_ SG_ 2561015550 AuxI_O99 "Identifies the current status of auxiliary input/output functions that are configured uniquely per application.";
CM_ SG_ 2561015550 AuxI_O100 "Identifies the current status of auxiliary input/output functions that are configured uniquely per application.";
CM_ SG_ 2561015550 AuxI_O93 "Identifies the current status of auxiliary input/output functions that are configured uniquely per application.";
CM_ SG_ 2561015550 AuxI_O94 "Identifies the current status of auxiliary input/output functions that are configured uniquely per application.";
CM_ SG_ 2561015550 AuxI_O95 "Identifies the current status of auxiliary input/output functions that are configured uniquely per application.";
CM_ SG_ 2561015550 AuxI_O96 "Identifies the current status of auxiliary input/output functions that are configured uniquely per application.";
CM_ SG_ 2561015550 AuxI_O89 "Identifies the current status of auxiliary input/output functions that are configured uniquely per application.";
CM_ SG_ 2561015550 AuxI_O90 "Identifies the current status of auxiliary input/output functions that are configured uniquely per application.";
CM_ SG_ 2561015550 AuxI_O91 "Identifies the current status of auxiliary input/output functions that are configured uniquely per application.";
CM_ SG_ 2561015550 AuxI_O92 "Identifies the current status of auxiliary input/output functions that are configured uniquely per application.";
CM_ SG_ 2561015550 AuxI_O85 "Identifies the current status of auxiliary input/output functions that are configured uniquely per application.";
CM_ SG_ 2561015550 AuxI_O86 "Identifies the current status of auxiliary input/output functions that are configured uniquely per application.";
CM_ SG_ 2561015550 AuxI_O87 "Identifies the current status of auxiliary input/output functions that are configured uniquely per application.";
CM_ SG_ 2561015550 AuxI_O88 "Identifies the current status of auxiliary input/output functions that are configured uniquely per application.";
CM_ SG_ 2561015550 AuxI_O81 "Identifies the current status of auxiliary input/output functions that are configured uniquely per application.";
CM_ SG_ 2561015550 AuxI_O82 "Identifies the current status of auxiliary input/output functions that are configured uniquely per application.";
CM_ SG_ 2561015550 AuxI_O83 "Identifies the current status of auxiliary input/output functions that are configured uniquely per application.";
CM_ SG_ 2561015550 AuxI_O84 "Identifies the current status of auxiliary input/output functions that are configured uniquely per application.";
CM_ BO_ 2566746622 "The Brake Stroke Alert (BSA) message will provide the brake actuator stroke status for up to 20 wheel ends.";
CM_ SG_ 2566746622 TrailerBrakeStrokeAxle5Right "Brake stroke status for right brake actuator on trailer axle 5.";
CM_ SG_ 2566746622 TrailerBrakeStrokeAxle5Left "Brake stroke status for left brake actuator on trailer axle 5.";
CM_ SG_ 2566746622 TrailerBrakeStrokeAxle4Right "Brake stroke status for right brake actuator on trailer axle 4.";
CM_ SG_ 2566746622 TrailerBrakeStrokeAxle4Left "Brake stroke status for left brake actuator on trailer axle 4.";
CM_ SG_ 2566746622 TrailerBrakeStrokeAxle3Right "Brake stroke status for right brake actuator on trailer axle 3.";
CM_ SG_ 2566746622 TrailerBrakeStrokeAxle3Left "Brake stroke status for left brake actuator on trailer axle 3.";
CM_ SG_ 2566746622 TrailerBrakeStrokeAxle2Right "Brake stroke status for right brake actuator on trailer axle 2.";
CM_ SG_ 2566746622 TrailerBrakeStrokeAxle2Left "Brake stroke status for left brake actuator on trailer axle 2.";
CM_ SG_ 2566746622 TrailerBrakeStrokeAxle1Right "Brake stroke status for right brake actuator on trailer axle 1.";
CM_ SG_ 2566746622 TrailerBrakeStrokeAxle1Left "Brake stroke status for left brake actuator on trailerr axle 1.";
CM_ SG_ 2566746622 TractorBrakeStrokeAxle5Right "Brake stroke status for right brake actuator on tractor axle 5.";
CM_ SG_ 2566746622 TractorBrakeStrokeAxle5Left "Brake stroke status for left brake actuator on tractor axle 5.";
CM_ SG_ 2566746622 TractorBrakeStrokeAxle4Right "Brake stroke status for right brake actuator on tractor axle 4.";
CM_ SG_ 2566746622 TractorBrakeStrokeAxle4Left "Brake stroke status for left brake actuator on tractor axle 4.";
CM_ SG_ 2566746622 TractorBrakeStrokeAxle3Right "Brake stroke status for right brake actuator on tractor axle 3.";
CM_ SG_ 2566746622 TractorBrakeStrokeAxle3Left "Brake stroke status for left brake actuator on tractor axle 3.";
CM_ SG_ 2566746622 TractorBrakeStrokeAxle2Right "Brake stroke status for right brake actuator on tractor axle 2.";
CM_ SG_ 2566746622 TractorBrakeStrokeAxle2Left "Brake stroke status for left brake actuator on tractor axle 2.";
CM_ SG_ 2566746622 TractorBrakeStrokeAxle1Right "Brake stroke status for right brake actuator on tractor axle 1.";
CM_ SG_ 2566746622 TractorBrakeStrokeAxle1Left "Brake stroke status for left brake actuator on tractor axle 1.";
CM_ SG_ 2566845950 RoadSurfaceTemp "Indicated temperature of road surface over which vehicle is operating.";
CM_ SG_ 2566845950 EngAirIntakeTemp "Temperature of air entering vehicle air induction system.";
CM_ SG_ 2566845950 AmbientAirTemp "Temperature of air surrounding vehicle.";
CM_ SG_ 2566845950 CabInteriorTemp "Temperature of air inside the part of the vehicle that encloses the driver and vehicle operating controls.";
CM_ SG_ 2566845950 BarometricPress "Absolute air pressure of the atmosphere.  See Figures SPN16_A & SPN16_B.";
CM_ SG_ 2566840062 EngAirStartPress "Gage pressure of air in an engine starting system that utilizes compressed air to provide the force required to rotate the ...";
CM_ BO_ 2566827774 "Air Supply Pressure ...";
CM_ SG_ 2566827774 AirCompressorStatus "Indicates whether the air compressor is actively compressing air.";
CM_ SG_ 2566827774 AirSuspensionSupplyPress "The pneumatic pressure in the circuit for the electronically controlled air suspension system.";
CM_ SG_ 2566827774 AuxEquipmentSupplyPress "The pneumatic pressure in the auxiliary circuit.";
CM_ SG_ 2566827774 ServiceBrakeCircuit2AirPress "The pneumatic pressure in the secondary service brake circuit or reservoir, supplying the front axle.";
CM_ SG_ 2566827774 ServiceBrakeCircuit1AirPress "The pneumatic pressure in the primary service brake circuit or reservoir, supplying the rear axle.";
CM_ SG_ 2566827774 ParkingAnd_orTrailerAirPress "The pneumatic pressure in the circuit or reservoir for the parking brake and/or the trailer supply.";
CM_ SG_ 2566827774 PneumaticSupplyPress "The pneumatic pressure in the main reservoir, sometimes referred to as the wet tank.";
CM_ BO_ 2566846974 "Axle information message ...";
CM_ SG_ 2566846974 SteerAxleLubePress "The steering axle lubricant pressure.";
CM_ SG_ 2566846974 SteerAxleTemp "Temperature of lubricant in steering axle.";
CM_ SG_ 2566846974 DriveAxleLubePress "The drive axle lubricant pressure with location determined by Drive Axle Location (SPN 930).";
CM_ SG_ 2566846974 DriveAxleTemp "Temperature of axle lubricant in drive axle.";
CM_ SG_ 2566846974 DriveAxleLiftAirPress "Gage pressure of air in system that utilizes compressed air to provide force between axle and frame.";
CM_ SG_ 2566846974 DriveAxleLocation "To identify to which of several similar devices (such as tires or fuel tanks) the information applies.";
CM_ SG_ 2633935614 EngGsMssFlwSnsrFuelingCorrection "The amount of fuel the Gas Mass Flow Sensor is sensing should be added or subtracted compared to the maximum ...";
CM_ SG_ 2633935614 EngTurboWastegateValvePos "The position of the turbocharger wastegate valve (not the electronic wastegate control valve).";
CM_ SG_ 2633935614 EngDesiredAbsIntakeManifoldPress "The desired absolute intake manifold pressure of the engine.";
CM_ SG_ 2633935614 EngGasFuelCorrectionFactor "A correction to a predefined gaseous fuel energy (expressed in energy per unit volume) represented as a percentage.";
CM_ BO_ 2566803966 "The operator requested characteristics for the ACC systems operation.";
CM_ SG_ 2566803966 RequestedACCDistanceMode "The Requested Distance Control Mode to the ACC system from the operators interface.";
CM_ SG_ 2566803966 ACCUsageDemand "This parameter indicates the drivers demand to activate or deactivate ACC keeping distance control.";
CM_ BO_ 2432593918 "NOTE—The ACC1 message is required whenever the engine is running and ACC is powered on and not ...";
CM_ SG_ 2432593918 ForwardCollisionWarning "This parameter indicates if a collision is imminent and strong driver reaction either by braking hard or by an avoidance ...";
CM_ SG_ 2432593918 ACCDistanceAlertSignal "Signal to indicate to the operator that the ACC system is not able to maintain the distance to the target. Example: Target ...";
CM_ SG_ 2432593918 ACCSystemShutoffWarning "Signal to warn the driver of system deactivation due to non-driver actions. Example: Attempting to control vehicle speed ...";
CM_ SG_ 2432593918 ACCTargetDetected "Signal to indicate to the driver that the ACC system has detected a target.";
CM_ SG_ 2432593918 RoadCurvature "Estimated value of the current road curvature for use by the adaptive cruise control system.  Positive values are used for ...";
CM_ SG_ 2432593918 AdptiveCruiseCtrlSetDistanceMode "Selected distance mode for adaptive cruise control.";
CM_ SG_ 2432593918 AdaptiveCruiseCtrlMode "This parameter is used to indicate the current state, or mode, of operation by the Adaptive Cruise Control (ACC) device.";
CM_ SG_ 2432593918 AdaptiveCruiseCtrlSetSpeed "Value of the desired (chosen) velocity of the adaptive cruise control system.";
CM_ SG_ 2432593918 DistanceToForwardVehicle "Distance to the preceding vehicle situated within 250 m in the same lane and moving in the same direction.";
CM_ SG_ 2432593918 SpeedOfForwardVehicle "Absolute velocity of the preceding vehicle situated within 250 m in the same lane and moving in the same direction.";
CM_ SG_ 2633935102 ArticulationAngle "Angle of deflection of an articulated transit vehicle (rotation angle about the vehicles z-axis). A right turn (clockwise) is ...";
CM_ BO_ 2633927934 "Auxiliary Analog Information ...";
CM_ SG_ 2633927934 RelativeHumidity "Measures humidity of combustion air prior to entry into turbocharger ...";
CM_ SG_ 2633927934 AuxLevel "Level measured by a sensor.";
CM_ SG_ 2633927934 AuxPress2 "Pressure measured by auxiliary pressure sensor #2.  Not to be used in place of existing SPNs.";
CM_ SG_ 2633927934 AuxPress1 "Pressure measured by auxiliary pressure sensor #1.  Not to be used in place of existing SPNs.";
CM_ SG_ 2633927934 AuxTemp2 "Temperature measured by auxiliary temperature sensor #2.  Not to be used in place of existing SPNs.";
CM_ SG_ 2633927934 AuxTemp1 "Temperature measured by auxiliary temperature sensor #1.  Not to be used in place of existing SPNs.";
CM_ SG_ 2566847998 EngBlowerBypassValvePos "Relative position of the blower bypass valve.";
CM_ SG_ 2566847998 EngGasSupplyPress "Gage pressure of gas supply to fuel metering device.";
CM_ BO_ 2565406462 "Acknowledgment Message";
CM_ SG_ 2565406462 ParameterGroupNumber "PGN which is requested by the Request message";
CM_ SG_ 2565406462 GroupFunctionValue "Group Function of PGN being acknowledged. This field identifies for a device the specific group function of a PGN being acknowledged or declined.  This field is not used if the PGN being acknowledged or declined is not a group function PGN.";
CM_ BO_ 2566803198 "Used for door information.";
CM_ SG_ 2566803198 Status2OfDoors "Composite indication of all bus door statuses. Enabled means the bus doors are able to be automatically opened or ...";
CM_ SG_ 2566803198 Ramp_WheelChairLiftPos "Signal which indicates the actual position of the ramp / wheel chair lift.";
CM_ SG_ 2566803198 PosOfDoors "Signal which indicates the actual position of the doors.";
CM_ BO_ 2565870334 "Fifth wheel smart system information. Parameters used to determine the status of the tractor to trailer coupling system ...";
CM_ SG_ 2565870334 FifthWheelRollWarningIndicator "Indicates to the vehicle operator that the roll moment has exceeded a preset limit.";
CM_ SG_ 2565870334 FifthWheelRollMoment "Fifth wheel roll moment force - If the moment is positive, the trailer is rolling clockwise relative to the normal vehicle ...";
CM_ SG_ 2565870334 FifthWheelDrawbarForce "Fifth wheel drawbar force, with the trailer held stationary a positive force is generated by the vehicle pulling forward.";
CM_ SG_ 2565870334 FifthWheelVerticalForce "The amount of load being applied to the fifth wheel by the trailer. Zero load is indicated without a trailer.";
CM_ BO_ 2566762238 "Fifth wheel smart system information #2. Message to convey operator parameters associated with the tractor to trailer ...";
CM_ SG_ 2566762238 FifthWheelSliderLockIndicator "Indicates to vehicle operator that the fifth wheel slider is in position and locked.";
CM_ SG_ 2566762238 FifthWheelSliderPos "Slider position measurement. Zero equals fully back position, that is, the farthest to the rear of the vehicle.";
CM_ SG_ 2566762238 FfthWhlLockCoupleStatusIndicator "Indicates results of coupling operation to the vehicle operator. For incomplete couples further information can be obtained ...";
CM_ SG_ 2566762238 FfthWhlLckReadyToCoupleIndicator "Indicates to the vehicle operator that the fifth wheel lock is open and ready to couple.";
CM_ SG_ 2566762238 FifthWheelErrorStatus "Fifth wheel error state which conveys information when coupling status is incomplete or bad.";
CM_ BO_ 2364543998 "The Slope Sensor Information message shall provide a measurement of the vehicles pitch angle, a measurement of the ...";
CM_ SG_ 2364543998 RollAndPitchMeasurementLatency "The estimated measurement latency of the measurement.  NOTE: This is only the sensor latency and does not include ...";
CM_ SG_ 2364543998 PitchAndRollCompensated "Compensated mode for the pitch and roll measurements.  Compensation is the use of multiple sensors together to ...";
CM_ SG_ 2364543998 PitchRateFigureOfMerit "Figure of merit for the pitch rate measurement.";
CM_ SG_ 2364543998 RollAngleFigureOfMerit "Figure of merit for roll angle measurement.";
CM_ SG_ 2364543998 PitchAngleFigureOfMerit "Figure of merit for pitch angle measurement.";
CM_ SG_ 2364543998 PitchRate "Pitch rate is the rate-of-change of the pitch angle over time, where the pitch angle vector is in the direction of travel of the ...";
CM_ SG_ 2364543998 RollAngle "The angle between the vehicle y-axis and the ground plane (i.e. rotation about the X-axis).  The roll angle for a roll to the ...";
CM_ SG_ 2364543998 PitchAngle "The angle between the vehicle x-axis and the ground plane (i.e. rotation about the vehicle Y-axis).  The pitch angle for an ...";
CM_ SG_ 2566846718 TransOilLevel1MeasurementStatus "Measurement status for the first instance of a transmission oil level indicator.  Indicates if conditions are acceptable to ...";
CM_ SG_ 2566846718 TransOilLevel1CountdownTimer "Countdown timer for the first instance of a transmission oil level indicator.  Once all vehicle conditions (such as vehicle ...";
CM_ SG_ 2566846718 TransOilLevel1High_Low "First instance of a transmission oil level indicator. Conveys the amount of current volume of transmission sump oil ...";
CM_ SG_ 2566846718 TransOilTemp1 "First instance of transmission lubricant temperature.";
CM_ SG_ 2566846718 TransOilPress "Gage pressure of lubrication fluid in transmission, measured after pump.";
CM_ SG_ 2566846718 TransFilterDiffPress "Change in transmission fluid pressure, measured after the filter, due to accumulation of solid or semisolid material on or in ...";
CM_ SG_ 2566846718 TransOilLevel1 "First instance of a transmission oil level indicator. Conveys the ratio of volume of transmission sump oil to recommended ...";
CM_ SG_ 2566846718 ClutchPress "Gage pressure of oil within a wet clutch.";
CM_ SG_ 2566846462 KeyswitchBatteryPotential "Battery potential measured at the input of the electronic control unit supplied through a keyswitch or similar switching ...";
CM_ SG_ 2566846462 BatteryPotential_PowerInput1 "This parameter measures the first source of battery potential as measured at the input of the ECM/actuator etc. coming ...";
CM_ SG_ 2566846462 ChargingSystemPotential "Electrical potential measured at the charging system output.  The charging system may be any device charging the ...";
CM_ SG_ 2566846462 AltCurrent "Measure of electrical current flow from the alternator.  Alternator Current (High Range/Resolution) parameter SPN 1795 ...";
CM_ SG_ 2566846462 NetBatteryCurrent "Net flow of electrical current into/out of the battery or batteries.";
CM_ BO_ 2566760702 "Message for reporting status information regarding the second instance of a wireless communications network on a ...";
CM_ SG_ 2566760702 WrelessCommunicationNetworkType2 "Type of Wireless Communication Network ...";
CM_ SG_ 2566760702 NetworkSignalStrength2 "Indicates the signal strength for the wireless communications network type.";
CM_ SG_ 2566760702 NetworkAntennaStatus2 "Indicates the status of the antenna for the wireless communications network type ...";
CM_ SG_ 2566760702 NetworkServiceStatus2 "Indicates the status of the Service for the wireless communications network type ...";
CM_ SG_ 2566760702 NetworkTransceiverStatus2 "Indicates the status of the transceiver for the wireless communications network type ...";
CM_ BO_ 2566760958 "Message for reporting status information regarding the first instance of a wireless communications network on a device or ...";
CM_ SG_ 2566760958 WrelessCommunicationNetworkType1 "Type of Wireless Communication Network ...";
CM_ SG_ 2566760958 NetworkSignalStrength1 "Indicates the signal strength for the wireless communications network type.";
CM_ SG_ 2566760958 NetworkAntennaStatus1 "Indicates the status of the antenna for the wireless communications network type ...";
CM_ SG_ 2566760958 NetworkServiceStatus1 "Indicates the status of the Service for the wireless communications network type ...";
CM_ SG_ 2566760958 NetworkTransceiverStatus1 "Indicates the status of the transceiver for the wireless communications network type ...";
CM_ BO_ 2633869310 "Voltage Regulator Operating Mode";
CM_ SG_ 2633869310 VoltageRegulatorEnabled "State signal indicating the Voltage regulator enabled.";
CM_ SG_ 2633869310 VoltageRegulatorSoftStartState "State signal indicating the mode of the Voltage regulator soft start function.";
CM_ SG_ 2633869310 VltgRgltrUndrfrqncyCmpnstnEnbld "State signal indicating the operating mode for underfrequency compensation.";
CM_ SG_ 2633869310 VltgRglatorLoadCompensationMode "State signal indicating the voltage regulator load compensation mode.";
CM_ BO_ 2365433598 "Voltage regulator excitation status";
CM_ SG_ 2365433598 GeneratorExcitationFieldCurrent "Measured signal that represents the generator excitation field current.";
CM_ SG_ 2365433598 GeneratorExcitationFieldVoltage "Measured signal that represents the generator excitation field voltage.";
BA_DEF_ SG_  "SigType" ENUM  "Default","Range","RangeSigned","ASCII","Discrete","Control","ReferencePGN","DTC","StringDelimiter","StringLength","StringLengthControl";
BA_DEF_ SG_  "GenSigStartValue" INT 0 10000;
BA_DEF_ SG_  "GenSigSendType" ENUM  "Cyclic","OnWrite","OnWriteWithRepetition","OnChange","OnChangeWithRepetition","IfActive","IfActiveWithRepetition","NoSigSendType";
BA_DEF_ SG_  "GenSigILSupport" ENUM  "No","Yes";
BA_DEF_ SG_  "GenSigEVName" STRING ;
BA_DEF_ SG_  "SPN" INT 0 524287;
BA_DEF_ BO_  "GenMsgStartDelayTime" INT 0 100000;
BA_DEF_ BO_  "GenMsgILSupport" ENUM  "No","Yes";
BA_DEF_ BO_  "GenMsgRequestable" INT 0 1;
BA_DEF_ BO_  "GenMsgSendType" ENUM  "cyclic","NotUsed","NotUsed","NotUsed","NotUsed","NotUsed","NotUsed","IfActive","noMsgSendType";
BA_DEF_ BO_  "VFrameFormat" ENUM  "StandardCAN","ExtendedCAN","reserved","J1939PG";
BA_DEF_ BO_  "GenMsgCycleTime" INT 0 3600000;
BA_DEF_ SG_  "SystemSignalLongSymbol" STRING ;
BA_DEF_DEF_  "SigType" "Default";
BA_DEF_DEF_  "GenSigStartValue" 0;
BA_DEF_DEF_  "GenSigSendType" "NoSigSendType";
BA_DEF_DEF_  "GenSigILSupport" "Yes";
BA_DEF_DEF_  "GenSigEVName" "Env@Nodename_@Signame";
BA_DEF_DEF_  "SPN" 0;
BA_DEF_DEF_  "GenMsgStartDelayTime" 0;
BA_DEF_DEF_  "GenMsgILSupport" "Yes";
BA_DEF_DEF_  "GenMsgRequestable" 1;
BA_DEF_DEF_  "GenMsgSendType" "noMsgSendType";
BA_DEF_DEF_  "VFrameFormat" "J1939PG";
BA_DEF_DEF_  "GenMsgCycleTime" 0;
BA_DEF_DEF_  "SystemSignalLongSymbol" "";
BA_ "GenMsgSendType" BO_ 2432520702 0;
BA_ "GenMsgCycleTime" BO_ 2432520702 1000;
BA_ "GenMsgSendType" BO_ 2499630078 0;
BA_ "GenMsgCycleTime" BO_ 2499630078 500;
BA_ "GenMsgSendType" BO_ 2566838782 0;
BA_ "GenMsgCycleTime" BO_ 2566838782 100;
BA_ "GenMsgSendType" BO_ 2561146622 0;
BA_ "GenMsgCycleTime" BO_ 2561146622 100;
BA_ "GenMsgSendType" BO_ 2561081086 0;
BA_ "GenMsgCycleTime" BO_ 2561081086 100;
BA_ "GenMsgSendType" BO_ 2561015550 0;
BA_ "GenMsgCycleTime" BO_ 2561015550 100;
BA_ "GenMsgSendType" BO_ 2566746622 0;
BA_ "GenMsgCycleTime" BO_ 2566746622 1000;
BA_ "GenMsgSendType" BO_ 2566845950 0;
BA_ "GenMsgCycleTime" BO_ 2566845950 1000;
BA_ "GenMsgSendType" BO_ 2566827774 0;
BA_ "GenMsgCycleTime" BO_ 2566827774 1000;
BA_ "GenMsgSendType" BO_ 2566846974 0;
BA_ "GenMsgCycleTime" BO_ 2566846974 1000;
BA_ "GenMsgSendType" BO_ 2566803966 0;
BA_ "GenMsgCycleTime" BO_ 2566803966 250;
BA_ "GenMsgSendType" BO_ 2432593918 0;
BA_ "GenMsgCycleTime" BO_ 2432593918 20;
BA_ "GenMsgSendType" BO_ 2566847998 0;
BA_ "GenMsgCycleTime" BO_ 2566847998 500;
BA_ "GenMsgSendType" BO_ 2566803198 0;
BA_ "GenMsgCycleTime" BO_ 2566803198 100;
BA_ "GenMsgSendType" BO_ 2565870334 0;
BA_ "GenMsgCycleTime" BO_ 2565870334 50;
BA_ "GenMsgSendType" BO_ 2364543998 0;
BA_ "GenMsgCycleTime" BO_ 2364543998 10;
BA_ "GenMsgSendType" BO_ 2566846718 0;
BA_ "GenMsgCycleTime" BO_ 2566846718 1000;
BA_ "GenMsgSendType" BO_ 2566846462 0;
BA_ "GenMsgCycleTime" BO_ 2566846462 1000;
BA_ "GenMsgSendType" BO_ 2633869310 0;
BA_ "GenMsgCycleTime" BO_ 2633869310 1000;
BA_ "GenMsgSendType" BO_ 2365433598 0;
BA_ "GenMsgCycleTime" BO_ 2365433598 100;
BA_ "SigType" SG_ 2563440382 ShrtNameOfActualReportingDevice 4;
BA_ "SPN" SG_ 2563440382 ShrtNameOfActualReportingDevice 2554;
BA_ "SigType" SG_ 2563440382 LengthOfDataForTheReportedPGN 1;
BA_ "SPN" SG_ 2563440382 LengthOfDataForTheReportedPGN 2553;
BA_ "SigType" SG_ 2563440382 PGNofRequstedInformation 6;
BA_ "SPN" SG_ 2563440382 PGNofRequstedInformation 2552;
BA_ "SPN" SG_ 2632711934 SequenceNumber 2572;
BA_ "SPN" SG_ 2632777470 ConnectionAbortReason 2570;
BA_ "SPN" SG_ 2632777470 NextPacketNumberToBeSent 2562;
BA_ "SPN" SG_ 2632777470 NumberOfPacketsThatCanBeSent 2561;
BA_ "SigType" SG_ 2632777470 PGNumber 6;
BA_ "SPN" SG_ 2632777470 PGNumber 2560;
BA_ "SPN" SG_ 2632777470 MaximumNumberOfPackets 2559;
BA_ "SPN" SG_ 2632777470 TotalNumberOfPackets 2558;
BA_ "SPN" SG_ 2632777470 TotalMessageSize 2557;
BA_ "SPN" SG_ 2632777470 ControlByte 2556;
BA_ "SigType" SG_ 2563374846 UseTransferMode 4;
BA_ "SPN" SG_ 2563374846 UseTransferMode 2575;
BA_ "SigType" SG_ 2563374846 ParameterGroupNumber 6;
BA_ "SPN" SG_ 2563374846 ParameterGroupNumber 2574;
BA_ "SigType" SG_ 2565537534 ParameterGroupNumber 6;
BA_ "SPN" SG_ 2565537534 ParameterGroupNumber 2574;
BA_ "SigType" SG_ 2499635966 AxleGroupWeight 1;
BA_ "SPN" SG_ 2499635966 AxleGroupWeight 409;
BA_ "SPN" SG_ 2499635966 AxleGroupLocation 4073;
BA_ "SigType" SG_ 2633853438 AxleGroupFullWeightCalib 1;
BA_ "SPN" SG_ 2633853438 AxleGroupFullWeightCalib 407;
BA_ "SigType" SG_ 2633853438 AxleGroupEmptyWeightCalib 1;
BA_ "SPN" SG_ 2633853438 AxleGroupEmptyWeightCalib 408;
BA_ "SPN" SG_ 2633853438 AxleGroupLocation 4074;
BA_ "SPN" SG_ 2432520702 DsrdAftrclrClntThermostatOpening 4200;
BA_ "SPN" SG_ 2432520702 DsrdAftercoolerCoolantIntakeTemp 4199;
BA_ "SigType" SG_ 2432520702 AftercoolerCoolantThermostatMode 5;
BA_ "SPN" SG_ 2432520702 AftercoolerCoolantThermostatMode 4198;
BA_ "SigType" SG_ 2566745086 AddtnlTrlrAxlGrupWeightAvailable 5;
BA_ "SPN" SG_ 2566745086 AddtnlTrlrAxlGrupWeightAvailable 4072;
BA_ "SigType" SG_ 2566745086 TrailerHAxleGroupWeightAvailable 5;
BA_ "SPN" SG_ 2566745086 TrailerHAxleGroupWeightAvailable 4071;
BA_ "SigType" SG_ 2566745086 TrailerGAxleGroupWeightAvailable 5;
BA_ "SPN" SG_ 2566745086 TrailerGAxleGroupWeightAvailable 4070;
BA_ "SigType" SG_ 2566745086 TrailerFAxleGroupWeightAvailable 5;
BA_ "SPN" SG_ 2566745086 TrailerFAxleGroupWeightAvailable 4069;
BA_ "SigType" SG_ 2566745086 TrailerEAxleGroupWeightAvailable 5;
BA_ "SPN" SG_ 2566745086 TrailerEAxleGroupWeightAvailable 4068;
BA_ "SigType" SG_ 2566745086 TrailerDAxleGroupWeightAvailable 5;
BA_ "SPN" SG_ 2566745086 TrailerDAxleGroupWeightAvailable 4067;
BA_ "SigType" SG_ 2566745086 TrailerCAxleGroupWeightAvailable 5;
BA_ "SPN" SG_ 2566745086 TrailerCAxleGroupWeightAvailable 4066;
BA_ "SigType" SG_ 2566745086 TrailerBAxleGroupWeightAvailable 5;
BA_ "SPN" SG_ 2566745086 TrailerBAxleGroupWeightAvailable 4065;
BA_ "SigType" SG_ 2566745086 TrailerAAxleGroupWeightAvailable 5;
BA_ "SPN" SG_ 2566745086 TrailerAAxleGroupWeightAvailable 4064;
BA_ "SigType" SG_ 2566745086 AddtnlTrctrAxlGrpWeightAvailable 5;
BA_ "SPN" SG_ 2566745086 AddtnlTrctrAxlGrpWeightAvailable 4063;
BA_ "SigType" SG_ 2566745086 TagAxleGroupWeightAvailable 5;
BA_ "SPN" SG_ 2566745086 TagAxleGroupWeightAvailable 4062;
BA_ "SigType" SG_ 2566745086 DriveAxleGroupWeightAvailable 5;
BA_ "SPN" SG_ 2566745086 DriveAxleGroupWeightAvailable 4061;
BA_ "SigType" SG_ 2566745086 LiftAxleGroupWeightAvailable 5;
BA_ "SPN" SG_ 2566745086 LiftAxleGroupWeightAvailable 4060;
BA_ "SigType" SG_ 2566745086 SteerAxleGroupWeightAvailable 5;
BA_ "SPN" SG_ 2566745086 SteerAxleGroupWeightAvailable 4059;
BA_ "SigType" SG_ 2566739198 FlashRedStopLamp 4;
BA_ "SPN" SG_ 2566739198 FlashRedStopLamp 3039;
BA_ "SigType" SG_ 2566739198 FlashProtectLamp 4;
BA_ "SPN" SG_ 2566739198 FlashProtectLamp 3041;
BA_ "SigType" SG_ 2566739198 FlashMalfuncIndicatorLamp 4;
BA_ "SPN" SG_ 2566739198 FlashMalfuncIndicatorLamp 3038;
BA_ "SigType" SG_ 2566739198 FlashAmberWarningLamp 4;
BA_ "SPN" SG_ 2566739198 FlashAmberWarningLamp 3040;
BA_ "SigType" SG_ 2566739198 MalfunctionIndicatorLampStatus 4;
BA_ "SPN" SG_ 2566739198 MalfunctionIndicatorLampStatus 1213;
BA_ "SigType" SG_ 2566739198 AmberWarningLampStatus 4;
BA_ "SPN" SG_ 2566739198 AmberWarningLampStatus 624;
BA_ "SigType" SG_ 2566739198 RedStopLampState 4;
BA_ "SPN" SG_ 2566739198 RedStopLampState 623;
BA_ "SigType" SG_ 2566739198 ProtectLampStatus 4;
BA_ "SPN" SG_ 2566739198 ProtectLampStatus 987;
BA_ "SigType" SG_ 2566739198 DTC5 7;
BA_ "SigType" SG_ 2566739198 DTC4 7;
BA_ "SigType" SG_ 2566739198 DTC3 7;
BA_ "SigType" SG_ 2566739198 DTC2 7;
BA_ "SigType" SG_ 2566739198 DTC1 7;
BA_ "SigType" SG_ 2566739454 FlashRedStopLamp 4;
BA_ "SPN" SG_ 2566739454 FlashRedStopLamp 3039;
BA_ "SigType" SG_ 2566739454 FlashProtectLamp 4;
BA_ "SPN" SG_ 2566739454 FlashProtectLamp 3041;
BA_ "SigType" SG_ 2566739454 FlashMalfuncIndicatorLamp 4;
BA_ "SPN" SG_ 2566739454 FlashMalfuncIndicatorLamp 3038;
BA_ "SigType" SG_ 2566739454 FlashAmberWarningLamp 4;
BA_ "SPN" SG_ 2566739454 FlashAmberWarningLamp 3040;
BA_ "SigType" SG_ 2566739454 MalfunctionIndicatorLampStatus 4;
BA_ "SPN" SG_ 2566739454 MalfunctionIndicatorLampStatus 1213;
BA_ "SigType" SG_ 2566739454 AmberWarningLampStatus 4;
BA_ "SPN" SG_ 2566739454 AmberWarningLampStatus 624;
BA_ "SigType" SG_ 2566739454 RedStopLampState 4;
BA_ "SPN" SG_ 2566739454 RedStopLampState 623;
BA_ "SigType" SG_ 2566739454 ProtectLampStatus 4;
BA_ "SPN" SG_ 2566739454 ProtectLampStatus 987;
BA_ "SigType" SG_ 2566739454 DTC5 7;
BA_ "SigType" SG_ 2566739454 DTC4 7;
BA_ "SigType" SG_ 2566739454 DTC3 7;
BA_ "SigType" SG_ 2566739454 DTC2 7;
BA_ "SigType" SG_ 2566739454 DTC1 7;
BA_ "SigType" SG_ 2566739710 FlashRedStopLamp 4;
BA_ "SPN" SG_ 2566739710 FlashRedStopLamp 3039;
BA_ "SigType" SG_ 2566739710 FlashProtectLamp 4;
BA_ "SPN" SG_ 2566739710 FlashProtectLamp 3041;
BA_ "SigType" SG_ 2566739710 FlashMalfuncIndicatorLamp 4;
BA_ "SPN" SG_ 2566739710 FlashMalfuncIndicatorLamp 3038;
BA_ "SigType" SG_ 2566739710 FlashAmberWarningLamp 4;
BA_ "SPN" SG_ 2566739710 FlashAmberWarningLamp 3040;
BA_ "SigType" SG_ 2566739710 MalfunctionIndicatorLampStatus 4;
BA_ "SPN" SG_ 2566739710 MalfunctionIndicatorLampStatus 1213;
BA_ "SigType" SG_ 2566739710 AmberWarningLampStatus 4;
BA_ "SPN" SG_ 2566739710 AmberWarningLampStatus 624;
BA_ "SigType" SG_ 2566739710 RedStopLampState 4;
BA_ "SPN" SG_ 2566739710 RedStopLampState 623;
BA_ "SigType" SG_ 2566739710 ProtectLampStatus 4;
BA_ "SPN" SG_ 2566739710 ProtectLampStatus 987;
BA_ "SigType" SG_ 2566739710 DTC5 7;
BA_ "SigType" SG_ 2566739710 DTC4 7;
BA_ "SigType" SG_ 2566739710 DTC3 7;
BA_ "SigType" SG_ 2566739710 DTC2 7;
BA_ "SigType" SG_ 2566739710 DTC1 7;
BA_ "SigType" SG_ 2566739966 FlashRedStopLamp 4;
BA_ "SPN" SG_ 2566739966 FlashRedStopLamp 3039;
BA_ "SigType" SG_ 2566739966 FlashProtectLamp 4;
BA_ "SPN" SG_ 2566739966 FlashProtectLamp 3041;
BA_ "SigType" SG_ 2566739966 FlashMalfuncIndicatorLamp 4;
BA_ "SPN" SG_ 2566739966 FlashMalfuncIndicatorLamp 3038;
BA_ "SigType" SG_ 2566739966 FlashAmberWarningLamp 4;
BA_ "SPN" SG_ 2566739966 FlashAmberWarningLamp 3040;
BA_ "SigType" SG_ 2566739966 MalfunctionIndicatorLampStatus 4;
BA_ "SPN" SG_ 2566739966 MalfunctionIndicatorLampStatus 1213;
BA_ "SigType" SG_ 2566739966 AmberWarningLampStatus 4;
BA_ "SPN" SG_ 2566739966 AmberWarningLampStatus 624;
BA_ "SigType" SG_ 2566739966 RedStopLampState 4;
BA_ "SPN" SG_ 2566739966 RedStopLampState 623;
BA_ "SigType" SG_ 2566739966 ProtectLampStatus 4;
BA_ "SPN" SG_ 2566739966 ProtectLampStatus 987;
BA_ "SigType" SG_ 2566739966 DTC5 7;
BA_ "SigType" SG_ 2566739966 DTC4 7;
BA_ "SigType" SG_ 2566739966 DTC3 7;
BA_ "SigType" SG_ 2566739966 DTC2 7;
BA_ "SigType" SG_ 2566739966 DTC1 7;
BA_ "SigType" SG_ 2566740222 FlashRedStopLamp 4;
BA_ "SPN" SG_ 2566740222 FlashRedStopLamp 3039;
BA_ "SigType" SG_ 2566740222 FlashProtectLamp 4;
BA_ "SPN" SG_ 2566740222 FlashProtectLamp 3041;
BA_ "SigType" SG_ 2566740222 FlashMalfuncIndicatorLamp 4;
BA_ "SPN" SG_ 2566740222 FlashMalfuncIndicatorLamp 3038;
BA_ "SigType" SG_ 2566740222 FlashAmberWarningLamp 4;
BA_ "SPN" SG_ 2566740222 FlashAmberWarningLamp 3040;
BA_ "SigType" SG_ 2566740222 MalfunctionIndicatorLampStatus 4;
BA_ "SPN" SG_ 2566740222 MalfunctionIndicatorLampStatus 1213;
BA_ "SigType" SG_ 2566740222 AmberWarningLampStatus 4;
BA_ "SPN" SG_ 2566740222 AmberWarningLampStatus 624;
BA_ "SigType" SG_ 2566740222 RedStopLampState 4;
BA_ "SPN" SG_ 2566740222 RedStopLampState 623;
BA_ "SigType" SG_ 2566740222 ProtectLampStatus 4;
BA_ "SPN" SG_ 2566740222 ProtectLampStatus 987;
BA_ "SigType" SG_ 2566740222 DTC5 7;
BA_ "SigType" SG_ 2566740222 DTC4 7;
BA_ "SigType" SG_ 2566740222 DTC3 7;
BA_ "SigType" SG_ 2566740222 DTC2 7;
BA_ "SigType" SG_ 2566740222 DTC1 7;
BA_ "SigType" SG_ 2566740478 FlashRedStopLamp 4;
BA_ "SPN" SG_ 2566740478 FlashRedStopLamp 3039;
BA_ "SigType" SG_ 2566740478 FlashProtectLamp 4;
BA_ "SPN" SG_ 2566740478 FlashProtectLamp 3041;
BA_ "SigType" SG_ 2566740478 FlashMalfuncIndicatorLamp 4;
BA_ "SPN" SG_ 2566740478 FlashMalfuncIndicatorLamp 3038;
BA_ "SigType" SG_ 2566740478 FlashAmberWarningLamp 4;
BA_ "SPN" SG_ 2566740478 FlashAmberWarningLamp 3040;
BA_ "SigType" SG_ 2566740478 MalfunctionIndicatorLampStatus 4;
BA_ "SPN" SG_ 2566740478 MalfunctionIndicatorLampStatus 1213;
BA_ "SigType" SG_ 2566740478 AmberWarningLampStatus 4;
BA_ "SPN" SG_ 2566740478 AmberWarningLampStatus 624;
BA_ "SigType" SG_ 2566740478 RedStopLampState 4;
BA_ "SPN" SG_ 2566740478 RedStopLampState 623;
BA_ "SigType" SG_ 2566740478 ProtectLampStatus 4;
BA_ "SPN" SG_ 2566740478 ProtectLampStatus 987;
BA_ "SigType" SG_ 2566740478 DTC5 7;
BA_ "SigType" SG_ 2566740478 DTC4 7;
BA_ "SigType" SG_ 2566740478 DTC3 7;
BA_ "SigType" SG_ 2566740478 DTC2 7;
BA_ "SigType" SG_ 2566740478 DTC1 7;
BA_ "SigType" SG_ 2566740734 FlashRedStopLamp 4;
BA_ "SPN" SG_ 2566740734 FlashRedStopLamp 3039;
BA_ "SigType" SG_ 2566740734 FlashProtectLamp 4;
BA_ "SPN" SG_ 2566740734 FlashProtectLamp 3041;
BA_ "SigType" SG_ 2566740734 FlashMalfuncIndicatorLamp 4;
BA_ "SPN" SG_ 2566740734 FlashMalfuncIndicatorLamp 3038;
BA_ "SigType" SG_ 2566740734 FlashAmberWarningLamp 4;
BA_ "SPN" SG_ 2566740734 FlashAmberWarningLamp 3040;
BA_ "SigType" SG_ 2566740734 MalfunctionIndicatorLampStatus 4;
BA_ "SPN" SG_ 2566740734 MalfunctionIndicatorLampStatus 1213;
BA_ "SigType" SG_ 2566740734 AmberWarningLampStatus 4;
BA_ "SPN" SG_ 2566740734 AmberWarningLampStatus 624;
BA_ "SigType" SG_ 2566740734 RedStopLampState 4;
BA_ "SPN" SG_ 2566740734 RedStopLampState 623;
BA_ "SigType" SG_ 2566740734 ProtectLampStatus 4;
BA_ "SPN" SG_ 2566740734 ProtectLampStatus 987;
BA_ "SigType" SG_ 2566740734 DTC5 7;
BA_ "SigType" SG_ 2566740734 DTC4 7;
BA_ "SigType" SG_ 2566740734 DTC3 7;
BA_ "SigType" SG_ 2566740734 DTC2 7;
BA_ "SigType" SG_ 2566740734 DTC1 7;
BA_ "SigType" SG_ 2566740990 FlashRedStopLamp 4;
BA_ "SPN" SG_ 2566740990 FlashRedStopLamp 3039;
BA_ "SigType" SG_ 2566740990 FlashProtectLamp 4;
BA_ "SPN" SG_ 2566740990 FlashProtectLamp 3041;
BA_ "SigType" SG_ 2566740990 FlashMalfuncIndicatorLamp 4;
BA_ "SPN" SG_ 2566740990 FlashMalfuncIndicatorLamp 3038;
BA_ "SigType" SG_ 2566740990 FlashAmberWarningLamp 4;
BA_ "SPN" SG_ 2566740990 FlashAmberWarningLamp 3040;
BA_ "SigType" SG_ 2566740990 MalfunctionIndicatorLampStatus 4;
BA_ "SPN" SG_ 2566740990 MalfunctionIndicatorLampStatus 1213;
BA_ "SigType" SG_ 2566740990 AmberWarningLampStatus 4;
BA_ "SPN" SG_ 2566740990 AmberWarningLampStatus 624;
BA_ "SigType" SG_ 2566740990 RedStopLampState 4;
BA_ "SPN" SG_ 2566740990 RedStopLampState 623;
BA_ "SigType" SG_ 2566740990 ProtectLampStatus 4;
BA_ "SPN" SG_ 2566740990 ProtectLampStatus 987;
BA_ "SigType" SG_ 2566740990 DTC5 7;
BA_ "SigType" SG_ 2566740990 DTC4 7;
BA_ "SigType" SG_ 2566740990 DTC3 7;
BA_ "SigType" SG_ 2566740990 DTC2 7;
BA_ "SigType" SG_ 2566740990 DTC1 7;
BA_ "SigType" SG_ 2566741246 FlashRedStopLamp 4;
BA_ "SPN" SG_ 2566741246 FlashRedStopLamp 3039;
BA_ "SigType" SG_ 2566741246 FlashProtectLamp 4;
BA_ "SPN" SG_ 2566741246 FlashProtectLamp 3041;
BA_ "SigType" SG_ 2566741246 FlashMalfuncIndicatorLamp 4;
BA_ "SPN" SG_ 2566741246 FlashMalfuncIndicatorLamp 3038;
BA_ "SigType" SG_ 2566741246 FlashAmberWarningLamp 4;
BA_ "SPN" SG_ 2566741246 FlashAmberWarningLamp 3040;
BA_ "SigType" SG_ 2566741246 MalfunctionIndicatorLampStatus 4;
BA_ "SPN" SG_ 2566741246 MalfunctionIndicatorLampStatus 1213;
BA_ "SigType" SG_ 2566741246 AmberWarningLampStatus 4;
BA_ "SPN" SG_ 2566741246 AmberWarningLampStatus 624;
BA_ "SigType" SG_ 2566741246 RedStopLampState 4;
BA_ "SPN" SG_ 2566741246 RedStopLampState 623;
BA_ "SigType" SG_ 2566741246 ProtectLampStatus 4;
BA_ "SPN" SG_ 2566741246 ProtectLampStatus 987;
BA_ "SigType" SG_ 2566741246 DTC5 7;
BA_ "SigType" SG_ 2566741246 DTC4 7;
BA_ "SigType" SG_ 2566741246 DTC3 7;
BA_ "SigType" SG_ 2566741246 DTC2 7;
BA_ "SigType" SG_ 2566741246 DTC1 7;
BA_ "SigType" SG_ 2566741502 FlashRedStopLamp 4;
BA_ "SPN" SG_ 2566741502 FlashRedStopLamp 3039;
BA_ "SigType" SG_ 2566741502 FlashProtectLamp 4;
BA_ "SPN" SG_ 2566741502 FlashProtectLamp 3041;
BA_ "SigType" SG_ 2566741502 FlashMalfuncIndicatorLamp 4;
BA_ "SPN" SG_ 2566741502 FlashMalfuncIndicatorLamp 3038;
BA_ "SigType" SG_ 2566741502 FlashAmberWarningLamp 4;
BA_ "SPN" SG_ 2566741502 FlashAmberWarningLamp 3040;
BA_ "SigType" SG_ 2566741502 MalfunctionIndicatorLampStatus 4;
BA_ "SPN" SG_ 2566741502 MalfunctionIndicatorLampStatus 1213;
BA_ "SigType" SG_ 2566741502 AmberWarningLampStatus 4;
BA_ "SPN" SG_ 2566741502 AmberWarningLampStatus 624;
BA_ "SigType" SG_ 2566741502 RedStopLampState 4;
BA_ "SPN" SG_ 2566741502 RedStopLampState 623;
BA_ "SigType" SG_ 2566741502 ProtectLampStatus 4;
BA_ "SPN" SG_ 2566741502 ProtectLampStatus 987;
BA_ "SigType" SG_ 2566741502 DTC5 7;
BA_ "SigType" SG_ 2566741502 DTC4 7;
BA_ "SigType" SG_ 2566741502 DTC3 7;
BA_ "SigType" SG_ 2566741502 DTC2 7;
BA_ "SigType" SG_ 2566741502 DTC1 7;
BA_ "SigType" SG_ 2566741758 FlashRedStopLamp 4;
BA_ "SPN" SG_ 2566741758 FlashRedStopLamp 3039;
BA_ "SigType" SG_ 2566741758 FlashProtectLamp 4;
BA_ "SPN" SG_ 2566741758 FlashProtectLamp 3041;
BA_ "SigType" SG_ 2566741758 FlashMalfuncIndicatorLamp 4;
BA_ "SPN" SG_ 2566741758 FlashMalfuncIndicatorLamp 3038;
BA_ "SigType" SG_ 2566741758 FlashAmberWarningLamp 4;
BA_ "SPN" SG_ 2566741758 FlashAmberWarningLamp 3040;
BA_ "SigType" SG_ 2566741758 MalfunctionIndicatorLampStatus 4;
BA_ "SPN" SG_ 2566741758 MalfunctionIndicatorLampStatus 1213;
BA_ "SigType" SG_ 2566741758 AmberWarningLampStatus 4;
BA_ "SPN" SG_ 2566741758 AmberWarningLampStatus 624;
BA_ "SigType" SG_ 2566741758 RedStopLampState 4;
BA_ "SPN" SG_ 2566741758 RedStopLampState 623;
BA_ "SigType" SG_ 2566741758 ProtectLampStatus 4;
BA_ "SPN" SG_ 2566741758 ProtectLampStatus 987;
BA_ "SigType" SG_ 2566741758 DTC5 7;
BA_ "SigType" SG_ 2566741758 DTC4 7;
BA_ "SigType" SG_ 2566741758 DTC3 7;
BA_ "SigType" SG_ 2566741758 DTC2 7;
BA_ "SigType" SG_ 2566741758 DTC1 7;
BA_ "SigType" SG_ 2566742014 FlashRedStopLamp 4;
BA_ "SPN" SG_ 2566742014 FlashRedStopLamp 3039;
BA_ "SigType" SG_ 2566742014 FlashProtectLamp 4;
BA_ "SPN" SG_ 2566742014 FlashProtectLamp 3041;
BA_ "SigType" SG_ 2566742014 FlashMalfuncIndicatorLamp 4;
BA_ "SPN" SG_ 2566742014 FlashMalfuncIndicatorLamp 3038;
BA_ "SigType" SG_ 2566742014 FlashAmberWarningLamp 4;
BA_ "SPN" SG_ 2566742014 FlashAmberWarningLamp 3040;
BA_ "SigType" SG_ 2566742014 MalfunctionIndicatorLampStatus 4;
BA_ "SPN" SG_ 2566742014 MalfunctionIndicatorLampStatus 1213;
BA_ "SigType" SG_ 2566742014 AmberWarningLampStatus 4;
BA_ "SPN" SG_ 2566742014 AmberWarningLampStatus 624;
BA_ "SigType" SG_ 2566742014 RedStopLampState 4;
BA_ "SPN" SG_ 2566742014 RedStopLampState 623;
BA_ "SigType" SG_ 2566742014 ProtectLampStatus 4;
BA_ "SPN" SG_ 2566742014 ProtectLampStatus 987;
BA_ "SigType" SG_ 2566742014 DTC5 7;
BA_ "SigType" SG_ 2566742014 DTC4 7;
BA_ "SigType" SG_ 2566742014 DTC3 7;
BA_ "SigType" SG_ 2566742014 DTC2 7;
BA_ "SigType" SG_ 2566742014 DTC1 7;
BA_ "SigType" SG_ 2560622334 FlashRedStopLamp 4;
BA_ "SPN" SG_ 2560622334 FlashRedStopLamp 3039;
BA_ "SigType" SG_ 2560622334 FlashProtectLamp 4;
BA_ "SPN" SG_ 2560622334 FlashProtectLamp 3041;
BA_ "SigType" SG_ 2560622334 FlashMalfuncIndicatorLamp 4;
BA_ "SPN" SG_ 2560622334 FlashMalfuncIndicatorLamp 3038;
BA_ "SigType" SG_ 2560622334 FlashAmberWarningLamp 4;
BA_ "SPN" SG_ 2560622334 FlashAmberWarningLamp 3040;
BA_ "SigType" SG_ 2560622334 MalfunctionIndicatorLampStatus 4;
BA_ "SPN" SG_ 2560622334 MalfunctionIndicatorLampStatus 1213;
BA_ "SigType" SG_ 2560622334 AmberWarningLampStatus 4;
BA_ "SPN" SG_ 2560622334 AmberWarningLampStatus 624;
BA_ "SigType" SG_ 2560622334 RedStopLampState 4;
BA_ "SPN" SG_ 2560622334 RedStopLampState 623;
BA_ "SigType" SG_ 2560622334 ProtectLampStatus 4;
BA_ "SPN" SG_ 2560622334 ProtectLampStatus 987;
BA_ "SigType" SG_ 2560622334 DTC5 7;
BA_ "SigType" SG_ 2560622334 DTC4 7;
BA_ "SigType" SG_ 2560622334 DTC3 7;
BA_ "SigType" SG_ 2560622334 DTC2 7;
BA_ "SigType" SG_ 2560622334 DTC1 7;
BA_ "SigType" SG_ 2566744062 ZeroNetVehicleWeightChange 5;
BA_ "SPN" SG_ 2566744062 ZeroNetVehicleWeightChange 4075;
BA_ "SPN" SG_ 2499630078 EngExhaustGasTempAverageBank2 4152;
BA_ "SPN" SG_ 2499630078 EngExhaustGasTempAverageBank1 4153;
BA_ "SPN" SG_ 2499630078 EngExhaustGasTempAverage 4151;
BA_ "SigType" SG_ 2560556798 PermanentDTCs 1;
BA_ "SPN" SG_ 2560556798 PermanentDTCs 4108;
BA_ "SigType" SG_ 2560556798 PreviouslyMILOnDTCs 1;
BA_ "SPN" SG_ 2560556798 PreviouslyMILOnDTCs 4107;
BA_ "SigType" SG_ 2560556798 MILOnDTCs 1;
BA_ "SPN" SG_ 2560556798 MILOnDTCs 4106;
BA_ "SigType" SG_ 2560556798 AllPendingDTCs 1;
BA_ "SPN" SG_ 2560556798 AllPendingDTCs 4105;
BA_ "SigType" SG_ 2560556798 PendingDTCs 1;
BA_ "SPN" SG_ 2560556798 PendingDTCs 4104;
BA_ "SigType" SG_ 2566750462 FlashRedStopLamp 4;
BA_ "SPN" SG_ 2566750462 FlashRedStopLamp 3039;
BA_ "SigType" SG_ 2566750462 FlashProtectLamp 4;
BA_ "SPN" SG_ 2566750462 FlashProtectLamp 3041;
BA_ "SigType" SG_ 2566750462 FlashMalfuncIndicatorLamp 4;
BA_ "SPN" SG_ 2566750462 FlashMalfuncIndicatorLamp 3038;
BA_ "SigType" SG_ 2566750462 FlashAmberWarningLamp 4;
BA_ "SPN" SG_ 2566750462 FlashAmberWarningLamp 3040;
BA_ "SigType" SG_ 2566750462 MalfunctionIndicatorLampStatus 4;
BA_ "SPN" SG_ 2566750462 MalfunctionIndicatorLampStatus 1213;
BA_ "SigType" SG_ 2566750462 AmberWarningLampStatus 4;
BA_ "SPN" SG_ 2566750462 AmberWarningLampStatus 624;
BA_ "SigType" SG_ 2566750462 RedStopLampState 4;
BA_ "SPN" SG_ 2566750462 RedStopLampState 623;
BA_ "SigType" SG_ 2566750462 ProtectLampStatus 4;
BA_ "SPN" SG_ 2566750462 ProtectLampStatus 987;
BA_ "SigType" SG_ 2566750462 DTC5 7;
BA_ "SigType" SG_ 2566750462 DTC4 7;
BA_ "SigType" SG_ 2566750462 DTC3 7;
BA_ "SigType" SG_ 2566750462 DTC2 7;
BA_ "SigType" SG_ 2566750462 DTC1 7;
BA_ "SigType" SG_ 2566750974 FlashRedStopLamp 4;
BA_ "SPN" SG_ 2566750974 FlashRedStopLamp 3039;
BA_ "SigType" SG_ 2566750974 FlashProtectLamp 4;
BA_ "SPN" SG_ 2566750974 FlashProtectLamp 3041;
BA_ "SigType" SG_ 2566750974 FlashMalfuncIndicatorLamp 4;
BA_ "SPN" SG_ 2566750974 FlashMalfuncIndicatorLamp 3038;
BA_ "SigType" SG_ 2566750974 FlashAmberWarningLamp 4;
BA_ "SPN" SG_ 2566750974 FlashAmberWarningLamp 3040;
BA_ "SigType" SG_ 2566750974 MalfunctionIndicatorLampStatus 4;
BA_ "SPN" SG_ 2566750974 MalfunctionIndicatorLampStatus 1213;
BA_ "SigType" SG_ 2566750974 AmberWarningLampStatus 4;
BA_ "SPN" SG_ 2566750974 AmberWarningLampStatus 624;
BA_ "SigType" SG_ 2566750974 RedStopLampState 4;
BA_ "SPN" SG_ 2566750974 RedStopLampState 623;
BA_ "SigType" SG_ 2566750974 ProtectLampStatus 4;
BA_ "SPN" SG_ 2566750974 ProtectLampStatus 987;
BA_ "SigType" SG_ 2566750974 DTC5 7;
BA_ "SigType" SG_ 2566750974 DTC4 7;
BA_ "SigType" SG_ 2566750974 DTC3 7;
BA_ "SigType" SG_ 2566750974 DTC2 7;
BA_ "SigType" SG_ 2566750974 DTC1 7;
BA_ "SigType" SG_ 2566754558 AETCTorqueValue14 1;
BA_ "SigType" SG_ 2566754558 AETCTorqueValue13 1;
BA_ "SigType" SG_ 2566754558 AETCTorqueValue12 1;
BA_ "SigType" SG_ 2566754558 AETCTorqueValue11 1;
BA_ "SigType" SG_ 2566754558 AETCTorqueValue10 1;
BA_ "SigType" SG_ 2566754558 AETCTorqueValue09 1;
BA_ "SigType" SG_ 2566754558 AETCTorqueValue08 1;
BA_ "SigType" SG_ 2566754558 AETCTorqueValue07 1;
BA_ "SigType" SG_ 2566754558 AETCTorqueValue06 1;
BA_ "SigType" SG_ 2566754558 AETCTorqueValue05 1;
BA_ "SigType" SG_ 2566754558 AETCTorqueValue04 1;
BA_ "SigType" SG_ 2566754558 AETCTorqueValue03 1;
BA_ "SigType" SG_ 2566754558 AETCTorqueValue02 1;
BA_ "SigType" SG_ 2566754558 AETCTorqueValue01 1;
BA_ "SigType" SG_ 2566754558 AETCSpeedValue14 1;
BA_ "SigType" SG_ 2566754558 AETCSpeedValue13 1;
BA_ "SigType" SG_ 2566754558 AETCSpeedValue12 1;
BA_ "SigType" SG_ 2566754558 AETCSpeedValue11 1;
BA_ "SigType" SG_ 2566754558 AETCSpeedValue10 1;
BA_ "SigType" SG_ 2566754558 AETCSpeedValue09 1;
BA_ "SigType" SG_ 2566754558 AETCSpeedValue08 1;
BA_ "SigType" SG_ 2566754558 AETCSpeedValue07 1;
BA_ "SigType" SG_ 2566754558 AETCSpeedValue06 1;
BA_ "SigType" SG_ 2566754558 AETCSpeedValue05 1;
BA_ "SigType" SG_ 2566754558 AETCSpeedValue04 1;
BA_ "SigType" SG_ 2566754558 AETCSpeedValue03 1;
BA_ "SigType" SG_ 2566754558 AETCSpeedValue02 1;
BA_ "SigType" SG_ 2566754558 AETCSpeedValue01 1;
BA_ "SigType" SG_ 2566754558 AETCTorqueValue00 1;
BA_ "SigType" SG_ 2566754558 AETCSpeedValue00 1;
BA_ "SPN" SG_ 2566754558 NumberOfAETCDataPoints 3559;
BA_ "SPN" SG_ 2566754558 AETCDataCollectionStandard 3558;
BA_ "SPN" SG_ 2566749950 RightHeadlampLightDistribution 3694;
BA_ "SPN" SG_ 2566749950 LeftHeadlampLightDistribution 3693;
BA_ "SPN" SG_ 2566749950 RightHeadlampDynamicBendingLight 3692;
BA_ "SPN" SG_ 2566749950 LeftHeadlampDynamicBendingLight 3691;
BA_ "SigType" SG_ 2566838782 AuxI_OChannel2 1;
BA_ "SPN" SG_ 2566838782 AuxI_OChannel2 1084;
BA_ "SigType" SG_ 2566838782 AuxI_OChannel1 1;
BA_ "SPN" SG_ 2566838782 AuxI_OChannel1 1083;
BA_ "SPN" SG_ 2566838782 AuxI_O13 713;
BA_ "SPN" SG_ 2566838782 AuxI_O14 714;
BA_ "SPN" SG_ 2566838782 AuxI_O15 715;
BA_ "SPN" SG_ 2566838782 AuxI_O16 716;
BA_ "SPN" SG_ 2566838782 AuxI_O09 709;
BA_ "SPN" SG_ 2566838782 AuxI_O10 710;
BA_ "SPN" SG_ 2566838782 AuxI_O11 711;
BA_ "SPN" SG_ 2566838782 AuxI_O12 712;
BA_ "SPN" SG_ 2566838782 AuxI_O05 705;
BA_ "SPN" SG_ 2566838782 AuxI_O06 706;
BA_ "SPN" SG_ 2566838782 AuxI_O07 707;
BA_ "SPN" SG_ 2566838782 AuxI_O08 708;
BA_ "SPN" SG_ 2566838782 AuxI_O01 701;
BA_ "SPN" SG_ 2566838782 AuxI_O02 702;
BA_ "SPN" SG_ 2566838782 AuxI_O03 703;
BA_ "SPN" SG_ 2566838782 AuxI_O04 704;
BA_ "SPN" SG_ 2561146622 AuxI_O45 3868;
BA_ "SPN" SG_ 2561146622 AuxI_O46 3869;
BA_ "SPN" SG_ 2561146622 AuxI_O47 3870;
BA_ "SPN" SG_ 2561146622 AuxI_O48 3871;
BA_ "SPN" SG_ 2561146622 AuxI_O41 3864;
BA_ "SPN" SG_ 2561146622 AuxI_O42 3865;
BA_ "SPN" SG_ 2561146622 AuxI_O43 3866;
BA_ "SPN" SG_ 2561146622 AuxI_O44 3867;
BA_ "SPN" SG_ 2561146622 AuxI_O37 3860;
BA_ "SPN" SG_ 2561146622 AuxI_O38 3861;
BA_ "SPN" SG_ 2561146622 AuxI_O39 3862;
BA_ "SPN" SG_ 2561146622 AuxI_O40 3863;
BA_ "SPN" SG_ 2561146622 AuxI_O33 3856;
BA_ "SPN" SG_ 2561146622 AuxI_O34 3857;
BA_ "SPN" SG_ 2561146622 AuxI_O35 3858;
BA_ "SPN" SG_ 2561146622 AuxI_O36 3859;
BA_ "SPN" SG_ 2561146622 AuxI_O29 3852;
BA_ "SPN" SG_ 2561146622 AuxI_O30 3853;
BA_ "SPN" SG_ 2561146622 AuxI_O31 3854;
BA_ "SPN" SG_ 2561146622 AuxI_O32 3855;
BA_ "SPN" SG_ 2561146622 AuxI_O25 3848;
BA_ "SPN" SG_ 2561146622 AuxI_O26 3849;
BA_ "SPN" SG_ 2561146622 AuxI_O27 3850;
BA_ "SPN" SG_ 2561146622 AuxI_O28 3851;
BA_ "SPN" SG_ 2561146622 AuxI_O21 3844;
BA_ "SPN" SG_ 2561146622 AuxI_O22 3845;
BA_ "SPN" SG_ 2561146622 AuxI_O23 3846;
BA_ "SPN" SG_ 2561146622 AuxI_O24 3847;
BA_ "SPN" SG_ 2561146622 AuxI_O17 3840;
BA_ "SPN" SG_ 2561146622 AuxI_O18 3841;
BA_ "SPN" SG_ 2561146622 AuxI_O19 3842;
BA_ "SPN" SG_ 2561146622 AuxI_O20 3843;
BA_ "SPN" SG_ 2561081086 AuxI_O77 3900;
BA_ "SPN" SG_ 2561081086 AuxI_O78 3901;
BA_ "SPN" SG_ 2561081086 AuxI_O79 3902;
BA_ "SPN" SG_ 2561081086 AuxI_O80 3903;
BA_ "SPN" SG_ 2561081086 AuxI_O73 3896;
BA_ "SPN" SG_ 2561081086 AuxI_O74 3897;
BA_ "SPN" SG_ 2561081086 AuxI_O75 3898;
BA_ "SPN" SG_ 2561081086 AuxI_O76 3899;
BA_ "SPN" SG_ 2561081086 AuxI_O69 3892;
BA_ "SPN" SG_ 2561081086 AuxI_O70 3893;
BA_ "SPN" SG_ 2561081086 AuxI_O71 3894;
BA_ "SPN" SG_ 2561081086 AuxI_O72 3895;
BA_ "SPN" SG_ 2561081086 AuxI_O65 3888;
BA_ "SPN" SG_ 2561081086 AuxI_O66 3889;
BA_ "SPN" SG_ 2561081086 AuxI_O67 3890;
BA_ "SPN" SG_ 2561081086 AuxI_O68 3891;
BA_ "SPN" SG_ 2561081086 AuxI_O61 3884;
BA_ "SPN" SG_ 2561081086 AuxI_O62 3885;
BA_ "SPN" SG_ 2561081086 AuxI_O63 3886;
BA_ "SPN" SG_ 2561081086 AuxI_O64 3887;
BA_ "SPN" SG_ 2561081086 AuxI_O57 3880;
BA_ "SPN" SG_ 2561081086 AuxI_O58 3881;
BA_ "SPN" SG_ 2561081086 AuxI_O59 3882;
BA_ "SPN" SG_ 2561081086 AuxI_O60 3883;
BA_ "SPN" SG_ 2561081086 AuxI_O53 3876;
BA_ "SPN" SG_ 2561081086 AuxI_O54 3877;
BA_ "SPN" SG_ 2561081086 AuxI_O55 3878;
BA_ "SPN" SG_ 2561081086 AuxI_O56 3879;
BA_ "SPN" SG_ 2561081086 AuxI_O49 3872;
BA_ "SPN" SG_ 2561081086 AuxI_O50 3873;
BA_ "SPN" SG_ 2561081086 AuxI_O51 3874;
BA_ "SPN" SG_ 2561081086 AuxI_O52 3875;
BA_ "SPN" SG_ 2561015550 AuxI_O109 3932;
BA_ "SPN" SG_ 2561015550 AuxI_O110 3933;
BA_ "SPN" SG_ 2561015550 AuxI_O111 3934;
BA_ "SPN" SG_ 2561015550 AuxI_O112 3935;
BA_ "SPN" SG_ 2561015550 AuxI_O105 3928;
BA_ "SPN" SG_ 2561015550 AuxI_O106 3929;
BA_ "SPN" SG_ 2561015550 AuxI_O107 3930;
BA_ "SPN" SG_ 2561015550 AuxI_O108 3931;
BA_ "SPN" SG_ 2561015550 AuxI_O101 3924;
BA_ "SPN" SG_ 2561015550 AuxI_O102 3925;
BA_ "SPN" SG_ 2561015550 AuxI_O103 3926;
BA_ "SPN" SG_ 2561015550 AuxI_O104 3927;
BA_ "SPN" SG_ 2561015550 AuxI_O97 3920;
BA_ "SPN" SG_ 2561015550 AuxI_O98 3921;
BA_ "SPN" SG_ 2561015550 AuxI_O99 3922;
BA_ "SPN" SG_ 2561015550 AuxI_O100 3923;
BA_ "SPN" SG_ 2561015550 AuxI_O93 3916;
BA_ "SPN" SG_ 2561015550 AuxI_O94 3917;
BA_ "SPN" SG_ 2561015550 AuxI_O95 3918;
BA_ "SPN" SG_ 2561015550 AuxI_O96 3919;
BA_ "SPN" SG_ 2561015550 AuxI_O89 3912;
BA_ "SPN" SG_ 2561015550 AuxI_O90 3913;
BA_ "SPN" SG_ 2561015550 AuxI_O91 3914;
BA_ "SPN" SG_ 2561015550 AuxI_O92 3915;
BA_ "SPN" SG_ 2561015550 AuxI_O85 3908;
BA_ "SPN" SG_ 2561015550 AuxI_O86 3909;
BA_ "SPN" SG_ 2561015550 AuxI_O87 3910;
BA_ "SPN" SG_ 2561015550 AuxI_O88 3911;
BA_ "SPN" SG_ 2561015550 AuxI_O81 3904;
BA_ "SPN" SG_ 2561015550 AuxI_O82 3905;
BA_ "SPN" SG_ 2561015550 AuxI_O83 3906;
BA_ "SPN" SG_ 2561015550 AuxI_O84 3907;
BA_ "SPN" SG_ 2566746622 TrailerBrakeStrokeAxle5Right 3804;
BA_ "SPN" SG_ 2566746622 TrailerBrakeStrokeAxle5Left 3803;
BA_ "SPN" SG_ 2566746622 TrailerBrakeStrokeAxle4Right 3802;
BA_ "SPN" SG_ 2566746622 TrailerBrakeStrokeAxle4Left 3801;
BA_ "SPN" SG_ 2566746622 TrailerBrakeStrokeAxle3Right 3800;
BA_ "SPN" SG_ 2566746622 TrailerBrakeStrokeAxle3Left 3799;
BA_ "SPN" SG_ 2566746622 TrailerBrakeStrokeAxle2Right 3798;
BA_ "SPN" SG_ 2566746622 TrailerBrakeStrokeAxle2Left 3797;
BA_ "SPN" SG_ 2566746622 TrailerBrakeStrokeAxle1Right 3796;
BA_ "SPN" SG_ 2566746622 TrailerBrakeStrokeAxle1Left 3795;
BA_ "SPN" SG_ 2566746622 TractorBrakeStrokeAxle5Right 3794;
BA_ "SPN" SG_ 2566746622 TractorBrakeStrokeAxle5Left 3793;
BA_ "SPN" SG_ 2566746622 TractorBrakeStrokeAxle4Right 3792;
BA_ "SPN" SG_ 2566746622 TractorBrakeStrokeAxle4Left 3791;
BA_ "SPN" SG_ 2566746622 TractorBrakeStrokeAxle3Right 3790;
BA_ "SPN" SG_ 2566746622 TractorBrakeStrokeAxle3Left 3789;
BA_ "SPN" SG_ 2566746622 TractorBrakeStrokeAxle2Right 3788;
BA_ "SPN" SG_ 2566746622 TractorBrakeStrokeAxle2Left 3787;
BA_ "SPN" SG_ 2566746622 TractorBrakeStrokeAxle1Right 3786;
BA_ "SPN" SG_ 2566746622 TractorBrakeStrokeAxle1Left 3785;
BA_ "SigType" SG_ 2566845950 RoadSurfaceTemp 1;
BA_ "SPN" SG_ 2566845950 RoadSurfaceTemp 79;
BA_ "SigType" SG_ 2566845950 EngAirIntakeTemp 1;
BA_ "SPN" SG_ 2566845950 EngAirIntakeTemp 172;
BA_ "SigType" SG_ 2566845950 AmbientAirTemp 1;
BA_ "SPN" SG_ 2566845950 AmbientAirTemp 171;
BA_ "SigType" SG_ 2566845950 CabInteriorTemp 1;
BA_ "SPN" SG_ 2566845950 CabInteriorTemp 170;
BA_ "SigType" SG_ 2566845950 BarometricPress 1;
BA_ "SPN" SG_ 2566845950 BarometricPress 108;
BA_ "SigType" SG_ 2566840062 EngAirStartPress 1;
BA_ "SPN" SG_ 2566840062 EngAirStartPress 82;
BA_ "SigType" SG_ 2566827774 AirCompressorStatus 4;
BA_ "SPN" SG_ 2566827774 AirCompressorStatus 1351;
BA_ "SigType" SG_ 2566827774 AirSuspensionSupplyPress 1;
BA_ "SPN" SG_ 2566827774 AirSuspensionSupplyPress 1090;
BA_ "SigType" SG_ 2566827774 AuxEquipmentSupplyPress 1;
BA_ "SPN" SG_ 2566827774 AuxEquipmentSupplyPress 1089;
BA_ "SigType" SG_ 2566827774 ServiceBrakeCircuit2AirPress 1;
BA_ "SPN" SG_ 2566827774 ServiceBrakeCircuit2AirPress 1088;
BA_ "SigType" SG_ 2566827774 ServiceBrakeCircuit1AirPress 1;
BA_ "SPN" SG_ 2566827774 ServiceBrakeCircuit1AirPress 1087;
BA_ "SigType" SG_ 2566827774 ParkingAnd_orTrailerAirPress 1;
BA_ "SPN" SG_ 2566827774 ParkingAnd_orTrailerAirPress 1086;
BA_ "SigType" SG_ 2566827774 PneumaticSupplyPress 1;
BA_ "SPN" SG_ 2566827774 PneumaticSupplyPress 46;
BA_ "SigType" SG_ 2566846974 SteerAxleLubePress 1;
BA_ "SPN" SG_ 2566846974 SteerAxleLubePress 2614;
BA_ "SigType" SG_ 2566846974 SteerAxleTemp 1;
BA_ "SPN" SG_ 2566846974 SteerAxleTemp 75;
BA_ "SigType" SG_ 2566846974 DriveAxleLubePress 1;
BA_ "SPN" SG_ 2566846974 DriveAxleLubePress 2613;
BA_ "SigType" SG_ 2566846974 DriveAxleTemp 1;
BA_ "SPN" SG_ 2566846974 DriveAxleTemp 578;
BA_ "SigType" SG_ 2566846974 DriveAxleLiftAirPress 1;
BA_ "SPN" SG_ 2566846974 DriveAxleLiftAirPress 579;
BA_ "SPN" SG_ 2566846974 DriveAxleLocation 930;
BA_ "SigType" SG_ 2633935614 EngGsMssFlwSnsrFuelingCorrection 1;
BA_ "SPN" SG_ 2633935614 EngGsMssFlwSnsrFuelingCorrection 1694;
BA_ "SigType" SG_ 2633935614 EngTurboWastegateValvePos 1;
BA_ "SPN" SG_ 2633935614 EngTurboWastegateValvePos 1693;
BA_ "SPN" SG_ 2633935614 EngDesiredAbsIntakeManifoldPress 1692;
BA_ "SigType" SG_ 2633935614 EngGasFuelCorrectionFactor 1;
BA_ "SPN" SG_ 2633935614 EngGasFuelCorrectionFactor 1116;
BA_ "SPN" SG_ 2566803966 RequestedACCDistanceMode 1799;
BA_ "SigType" SG_ 2566803966 ACCUsageDemand 5;
BA_ "SPN" SG_ 2566803966 ACCUsageDemand 5023;
BA_ "SigType" SG_ 2432593918 ForwardCollisionWarning 5;
BA_ "SPN" SG_ 2432593918 ForwardCollisionWarning 5022;
BA_ "SigType" SG_ 2432593918 ACCDistanceAlertSignal 5;
BA_ "SPN" SG_ 2432593918 ACCDistanceAlertSignal 1796;
BA_ "SigType" SG_ 2432593918 ACCSystemShutoffWarning 5;
BA_ "SPN" SG_ 2432593918 ACCSystemShutoffWarning 1797;
BA_ "SigType" SG_ 2432593918 ACCTargetDetected 5;
BA_ "SPN" SG_ 2432593918 ACCTargetDetected 1798;
BA_ "SPN" SG_ 2432593918 RoadCurvature 1591;
BA_ "SPN" SG_ 2432593918 AdptiveCruiseCtrlSetDistanceMode 1589;
BA_ "SPN" SG_ 2432593918 AdaptiveCruiseCtrlMode 1590;
BA_ "SPN" SG_ 2432593918 AdaptiveCruiseCtrlSetSpeed 1588;
BA_ "SigType" SG_ 2432593918 DistanceToForwardVehicle 1;
BA_ "SPN" SG_ 2432593918 DistanceToForwardVehicle 1587;
BA_ "SigType" SG_ 2432593918 SpeedOfForwardVehicle 1;
BA_ "SPN" SG_ 2432593918 SpeedOfForwardVehicle 1586;
BA_ "SigType" SG_ 2633935102 ArticulationAngle 1;
BA_ "SPN" SG_ 2633935102 ArticulationAngle 1120;
BA_ "SigType" SG_ 2633927934 RelativeHumidity 1;
BA_ "SPN" SG_ 2633927934 RelativeHumidity 354;
BA_ "SigType" SG_ 2633927934 AuxLevel 1;
BA_ "SPN" SG_ 2633927934 AuxLevel 3087;
BA_ "SigType" SG_ 2633927934 AuxPress2 1;
BA_ "SPN" SG_ 2633927934 AuxPress2 1388;
BA_ "SigType" SG_ 2633927934 AuxPress1 1;
BA_ "SPN" SG_ 2633927934 AuxPress1 1387;
BA_ "SigType" SG_ 2633927934 AuxTemp2 1;
BA_ "SPN" SG_ 2633927934 AuxTemp2 442;
BA_ "SigType" SG_ 2633927934 AuxTemp1 1;
BA_ "SPN" SG_ 2633927934 AuxTemp1 441;
BA_ "SigType" SG_ 2566847998 EngBlowerBypassValvePos 1;
BA_ "SPN" SG_ 2566847998 EngBlowerBypassValvePos 72;
BA_ "SigType" SG_ 2566847998 EngGasSupplyPress 1;
BA_ "SPN" SG_ 2566847998 EngGasSupplyPress 159;
BA_ "SPN" SG_ 2565406462 ControlByte 2541;
BA_ "SigType" SG_ 2565406462 ParameterGroupNumber 6;
BA_ "SPN" SG_ 2565406462 ParameterGroupNumber 2574;
BA_ "SigType" SG_ 2565406462 GroupFunctionValue 1;
BA_ "SPN" SG_ 2565406462 GroupFunctionValue 2542;
BA_ "SigType" SG_ 2566803198 Status2OfDoors 4;
BA_ "SPN" SG_ 2566803198 Status2OfDoors 3411;
BA_ "SigType" SG_ 2566803198 Ramp_WheelChairLiftPos 4;
BA_ "SPN" SG_ 2566803198 Ramp_WheelChairLiftPos 1820;
BA_ "SPN" SG_ 2566803198 PosOfDoors 1821;
BA_ "SigType" SG_ 2565870334 FifthWheelRollWarningIndicator 5;
BA_ "SPN" SG_ 2565870334 FifthWheelRollWarningIndicator 3317;
BA_ "SigType" SG_ 2565870334 FifthWheelRollMoment 1;
BA_ "SPN" SG_ 2565870334 FifthWheelRollMoment 3310;
BA_ "SigType" SG_ 2565870334 FifthWheelDrawbarForce 1;
BA_ "SPN" SG_ 2565870334 FifthWheelDrawbarForce 3309;
BA_ "SigType" SG_ 2565870334 FifthWheelVerticalForce 1;
BA_ "SPN" SG_ 2565870334 FifthWheelVerticalForce 3308;
BA_ "SigType" SG_ 2566762238 FifthWheelSliderLockIndicator 4;
BA_ "SPN" SG_ 2566762238 FifthWheelSliderLockIndicator 3316;
BA_ "SigType" SG_ 2566762238 FifthWheelSliderPos 1;
BA_ "SPN" SG_ 2566762238 FifthWheelSliderPos 3311;
BA_ "SigType" SG_ 2566762238 FfthWhlLockCoupleStatusIndicator 5;
BA_ "SPN" SG_ 2566762238 FfthWhlLockCoupleStatusIndicator 3313;
BA_ "SigType" SG_ 2566762238 FfthWhlLckReadyToCoupleIndicator 5;
BA_ "SPN" SG_ 2566762238 FfthWhlLckReadyToCoupleIndicator 3312;
BA_ "SPN" SG_ 2566762238 FifthWheelErrorStatus 3307;
BA_ "SigType" SG_ 2364543998 RollAndPitchMeasurementLatency 1;
BA_ "SPN" SG_ 2364543998 RollAndPitchMeasurementLatency 3327;
BA_ "SigType" SG_ 2364543998 PitchAndRollCompensated 5;
BA_ "SPN" SG_ 2364543998 PitchAndRollCompensated 3326;
BA_ "SigType" SG_ 2364543998 PitchRateFigureOfMerit 5;
BA_ "SPN" SG_ 2364543998 PitchRateFigureOfMerit 3325;
BA_ "SigType" SG_ 2364543998 RollAngleFigureOfMerit 5;
BA_ "SPN" SG_ 2364543998 RollAngleFigureOfMerit 3324;
BA_ "SigType" SG_ 2364543998 PitchAngleFigureOfMerit 5;
BA_ "SPN" SG_ 2364543998 PitchAngleFigureOfMerit 3323;
BA_ "SigType" SG_ 2364543998 PitchRate 1;
BA_ "SPN" SG_ 2364543998 PitchRate 3322;
BA_ "SigType" SG_ 2364543998 RollAngle 1;
BA_ "SPN" SG_ 2364543998 RollAngle 3319;
BA_ "SigType" SG_ 2364543998 PitchAngle 1;
BA_ "SPN" SG_ 2364543998 PitchAngle 3318;
BA_ "SPN" SG_ 2566846718 TransOilLevel1MeasurementStatus 3026;
BA_ "SPN" SG_ 2566846718 TransOilLevel1CountdownTimer 3028;
BA_ "SigType" SG_ 2566846718 TransOilLevel1High_Low 1;
BA_ "SPN" SG_ 2566846718 TransOilLevel1High_Low 3027;
BA_ "SigType" SG_ 2566846718 TransOilTemp1 1;
BA_ "SPN" SG_ 2566846718 TransOilTemp1 177;
BA_ "SigType" SG_ 2566846718 TransOilPress 1;
BA_ "SPN" SG_ 2566846718 TransOilPress 127;
BA_ "SigType" SG_ 2566846718 TransFilterDiffPress 1;
BA_ "SPN" SG_ 2566846718 TransFilterDiffPress 126;
BA_ "SigType" SG_ 2566846718 TransOilLevel1 1;
BA_ "SPN" SG_ 2566846718 TransOilLevel1 124;
BA_ "SigType" SG_ 2566846718 ClutchPress 1;
BA_ "SPN" SG_ 2566846718 ClutchPress 123;
BA_ "SigType" SG_ 2566846462 KeyswitchBatteryPotential 1;
BA_ "SPN" SG_ 2566846462 KeyswitchBatteryPotential 158;
BA_ "SigType" SG_ 2566846462 BatteryPotential_PowerInput1 1;
BA_ "SPN" SG_ 2566846462 BatteryPotential_PowerInput1 168;
BA_ "SigType" SG_ 2566846462 ChargingSystemPotential 1;
BA_ "SPN" SG_ 2566846462 ChargingSystemPotential 167;
BA_ "SigType" SG_ 2566846462 AltCurrent 1;
BA_ "SPN" SG_ 2566846462 AltCurrent 115;
BA_ "SigType" SG_ 2566846462 NetBatteryCurrent 1;
BA_ "SPN" SG_ 2566846462 NetBatteryCurrent 114;
BA_ "SPN" SG_ 2566760702 WrelessCommunicationNetworkType2 3446;
BA_ "SPN" SG_ 2566760702 NetworkSignalStrength2 3445;
BA_ "SPN" SG_ 2566760702 NetworkAntennaStatus2 3444;
BA_ "SPN" SG_ 2566760702 NetworkServiceStatus2 3443;
BA_ "SPN" SG_ 2566760702 NetworkTransceiverStatus2 3442;
BA_ "SPN" SG_ 2566760958 WrelessCommunicationNetworkType1 3372;
BA_ "SPN" SG_ 2566760958 NetworkSignalStrength1 3371;
BA_ "SPN" SG_ 2566760958 NetworkAntennaStatus1 3370;
BA_ "SPN" SG_ 2566760958 NetworkServiceStatus1 3369;
BA_ "SPN" SG_ 2566760958 NetworkTransceiverStatus1 3368;
BA_ "SigType" SG_ 2633869310 VoltageRegulatorEnabled 4;
BA_ "SPN" SG_ 2633869310 VoltageRegulatorEnabled 3379;
BA_ "SigType" SG_ 2633869310 VoltageRegulatorSoftStartState 4;
BA_ "SPN" SG_ 2633869310 VoltageRegulatorSoftStartState 3378;
BA_ "SigType" SG_ 2633869310 VltgRgltrUndrfrqncyCmpnstnEnbld 4;
BA_ "SPN" SG_ 2633869310 VltgRgltrUndrfrqncyCmpnstnEnbld 3377;
BA_ "SPN" SG_ 2633869310 VltgRgltrVAr_PwrFctrOprtingMode 3376;
BA_ "SPN" SG_ 2633869310 VltgRglatorLoadCompensationMode 3375;
BA_ "SigType" SG_ 2365433598 GnrtrOtputVoltageBiasPercentage 1;
BA_ "SPN" SG_ 2365433598 GnrtrOtputVoltageBiasPercentage 3382;
BA_ "SigType" SG_ 2365433598 GeneratorExcitationFieldCurrent 1;
BA_ "SPN" SG_ 2365433598 GeneratorExcitationFieldCurrent 3381;
BA_ "SigType" SG_ 2365433598 GeneratorExcitationFieldVoltage 1;
BA_ "SPN" SG_ 2365433598 GeneratorExcitationFieldVoltage 3380;
VAL_ 2632777470 PGNumber 255 "NotAvailable" ;
VAL_ 2632777470 ControlByte 24 "EAbort" 23 "EEoMACK" 22 "EDPO" 21 "ECTS" 20 "ERTS" 255 "Abort" 32 "BAM" 19 "EoMA" 17 "CTS" 16 "RTS" ;
VAL_ 2563374846 UseTransferMode 3 "NA" 2 "Undefined" 1 "Yes" 0 "No" ;
VAL_ 2499635966 AxleGroupLocation 3 "Trailer F axle group" 2 "Trailer E axle group" ;
VAL_ 2633853438 AxleGroupLocation 3 "Trailer F axle group" 2 "Trailer E axle group" ;
VAL_ 2432520702 AftercoolerCoolantThermostatMode 3 "dont care/reserved" 2 "reserved" 1 "position control mode used for service only" 0 "temperature control mode" ;
VAL_ 2566745086 AddtnlTrlrAxlGrupWeightAvailable 3 "Not available / not applicable" 2 "Reserved" 1 "Additional trailer axle group present" 0 "Additional trailer axle group not present" ;
VAL_ 2566745086 TrailerHAxleGroupWeightAvailable 3 "Not available / not applicable" 2 "Reserved" 1 "Trailer H axle group present" 0 "Trailer H axle group not present" ;
VAL_ 2566745086 TrailerGAxleGroupWeightAvailable 3 "Not available / not applicable" 2 "Reserved" 1 "Trailer G axle group present" 0 "Trailer G axle group not present" ;
VAL_ 2566745086 TrailerFAxleGroupWeightAvailable 3 "Not available / not applicable" 2 "Reserved" 1 "Trailer F axle group present" 0 "Trailer F axle group not present" ;
VAL_ 2566745086 TrailerEAxleGroupWeightAvailable 3 "Not available / not applicable" 2 "Reserved" 1 "Trailer E axle group present" 0 "Trailer E axle group not present" ;
VAL_ 2566745086 TrailerDAxleGroupWeightAvailable 3 "Not available / not applicable" 2 "Reserved" 1 "Trailer D axle group present" 0 "Trailer D axle group not present" ;
VAL_ 2566745086 TrailerCAxleGroupWeightAvailable 3 "Not available / not applicable" 2 "Reserved" 1 "Trailer C axle group present" 0 "Trailer C axle group not present" ;
VAL_ 2566745086 TrailerBAxleGroupWeightAvailable 3 "Not available / not applicable" 2 "Reserved" 1 "Trailer B axle group present" 0 "Trailer B axle group not present" ;
VAL_ 2566745086 TrailerAAxleGroupWeightAvailable 3 "Not available / not applicable" 2 "Reserved" 1 "Trailer A axle group present" 0 "Trailer A axle group not present" ;
VAL_ 2566745086 AddtnlTrctrAxlGrpWeightAvailable 3 "Not available / not applicable" 2 "Reserved" 1 "Additional tractor axle group present" 0 "Additional tractor axle group not present" ;
VAL_ 2566745086 TagAxleGroupWeightAvailable 3 "Not available / not applicable" 2 "Reserved" 1 "Tag axle group present" 0 "Tag axle group not present" ;
VAL_ 2566745086 DriveAxleGroupWeightAvailable 3 "Not available / not applicable" 2 "Reserved" 1 "Drive axle group present" 0 "Drive axle group not present" ;
VAL_ 2566745086 LiftAxleGroupWeightAvailable 3 "Not available / not applicable" 2 "Reserved" 1 "Lift axle group present" 0 "Lift axle group not present" ;
VAL_ 2566745086 SteerAxleGroupWeightAvailable 3 "Not available / not applicable" 2 "Reserved" 1 "Steer axle group present" 0 "Steer axle group not present" ;
VAL_ 2566739198 FlashRedStopLamp 3 "Unavailable / Do Not Flash" 2 "Reserved" 1 "Fast Flash" 0 "Slow Flash" ;
VAL_ 2566739198 FlashProtectLamp 3 "Unavailable / Do Not Flash" 2 "Reserved" 1 "Fast Flash" 0 "Slow Flash" ;
VAL_ 2566739198 FlashMalfuncIndicatorLamp 3 "Unavailable / Do Not Flash" 2 "Reserved" 1 "Fast Flash" 0 "Slow Flash" ;
VAL_ 2566739198 FlashAmberWarningLamp 3 "Unavailable / Do Not Flash" 2 "Reserved" 1 "Fast Flash" 0 "Slow Flash" ;
VAL_ 2566739198 MalfunctionIndicatorLampStatus 3 "Not available" 2 "Reserved" 1 "Lamp on" 0 "Lamp off" ;
VAL_ 2566739198 AmberWarningLampStatus 3 "Not available" 2 "Reserved" 1 "Lamp on" 0 "Lamp off" ;
VAL_ 2566739198 RedStopLampState 3 "Not available" 2 "Reserved" 1 "Lamp on" 0 "Lamp off" ;
VAL_ 2566739198 ProtectLampStatus 3 "Not available" 2 "Reserved" 1 "Lamp on" 0 "Lamp off" ;
VAL_ 2566739454 FlashRedStopLamp 3 "Unavailable / Do Not Flash" 2 "Reserved" 1 "Fast Flash" 0 "Slow Flash" ;
VAL_ 2566739454 FlashProtectLamp 3 "Unavailable / Do Not Flash" 2 "Reserved" 1 "Fast Flash" 0 "Slow Flash" ;
VAL_ 2566739454 FlashMalfuncIndicatorLamp 3 "Unavailable / Do Not Flash" 2 "Reserved" 1 "Fast Flash" 0 "Slow Flash" ;
VAL_ 2566739454 FlashAmberWarningLamp 3 "Unavailable / Do Not Flash" 2 "Reserved" 1 "Fast Flash" 0 "Slow Flash" ;
VAL_ 2566739454 MalfunctionIndicatorLampStatus 3 "Not available" 2 "Reserved" 1 "Lamp on" 0 "Lamp off" ;
VAL_ 2566739454 AmberWarningLampStatus 3 "Not available" 2 "Reserved" 1 "Lamp on" 0 "Lamp off" ;
VAL_ 2566739454 RedStopLampState 3 "Not available" 2 "Reserved" 1 "Lamp on" 0 "Lamp off" ;
VAL_ 2566739454 ProtectLampStatus 3 "Not available" 2 "Reserved" 1 "Lamp on" 0 "Lamp off" ;
VAL_ 2566739710 FlashRedStopLamp 3 "Unavailable / Do Not Flash" 2 "Reserved" 1 "Fast Flash" 0 "Slow Flash" ;
VAL_ 2566739710 FlashProtectLamp 3 "Unavailable / Do Not Flash" 2 "Reserved" 1 "Fast Flash" 0 "Slow Flash" ;
VAL_ 2566739710 FlashMalfuncIndicatorLamp 3 "Unavailable / Do Not Flash" 2 "Reserved" 1 "Fast Flash" 0 "Slow Flash" ;
VAL_ 2566739710 FlashAmberWarningLamp 3 "Unavailable / Do Not Flash" 2 "Reserved" 1 "Fast Flash" 0 "Slow Flash" ;
VAL_ 2566739710 MalfunctionIndicatorLampStatus 3 "Not available" 2 "Reserved" 1 "Lamp on" 0 "Lamp off" ;
VAL_ 2566739710 AmberWarningLampStatus 3 "Not available" 2 "Reserved" 1 "Lamp on" 0 "Lamp off" ;
VAL_ 2566739710 RedStopLampState 3 "Not available" 2 "Reserved" 1 "Lamp on" 0 "Lamp off" ;
VAL_ 2566739710 ProtectLampStatus 3 "Not available" 2 "Reserved" 1 "Lamp on" 0 "Lamp off" ;
VAL_ 2566739966 FlashRedStopLamp 3 "Unavailable / Do Not Flash" 2 "Reserved" 1 "Fast Flash" 0 "Slow Flash" ;
VAL_ 2566739966 FlashProtectLamp 3 "Unavailable / Do Not Flash" 2 "Reserved" 1 "Fast Flash" 0 "Slow Flash" ;
VAL_ 2566739966 FlashMalfuncIndicatorLamp 3 "Unavailable / Do Not Flash" 2 "Reserved" 1 "Fast Flash" 0 "Slow Flash" ;
VAL_ 2566739966 FlashAmberWarningLamp 3 "Unavailable / Do Not Flash" 2 "Reserved" 1 "Fast Flash" 0 "Slow Flash" ;
VAL_ 2566739966 MalfunctionIndicatorLampStatus 3 "Not available" 2 "Reserved" 1 "Lamp on" 0 "Lamp off" ;
VAL_ 2566739966 AmberWarningLampStatus 3 "Not available" 2 "Reserved" 1 "Lamp on" 0 "Lamp off" ;
VAL_ 2566739966 RedStopLampState 3 "Not available" 2 "Reserved" 1 "Lamp on" 0 "Lamp off" ;
VAL_ 2566739966 ProtectLampStatus 3 "Not available" 2 "Reserved" 1 "Lamp on" 0 "Lamp off" ;
VAL_ 2566740222 FlashRedStopLamp 3 "Unavailable / Do Not Flash" 2 "Reserved" 1 "Fast Flash" 0 "Slow Flash" ;
VAL_ 2566740222 FlashProtectLamp 3 "Unavailable / Do Not Flash" 2 "Reserved" 1 "Fast Flash" 0 "Slow Flash" ;
VAL_ 2566740222 FlashMalfuncIndicatorLamp 3 "Unavailable / Do Not Flash" 2 "Reserved" 1 "Fast Flash" 0 "Slow Flash" ;
VAL_ 2566740222 FlashAmberWarningLamp 3 "Unavailable / Do Not Flash" 2 "Reserved" 1 "Fast Flash" 0 "Slow Flash" ;
VAL_ 2566740222 MalfunctionIndicatorLampStatus 3 "Not available" 2 "Reserved" 1 "Lamp on" 0 "Lamp off" ;
VAL_ 2566740222 AmberWarningLampStatus 3 "Not available" 2 "Reserved" 1 "Lamp on" 0 "Lamp off" ;
VAL_ 2566740222 RedStopLampState 3 "Not available" 2 "Reserved" 1 "Lamp on" 0 "Lamp off" ;
VAL_ 2566740222 ProtectLampStatus 3 "Not available" 2 "Reserved" 1 "Lamp on" 0 "Lamp off" ;
VAL_ 2566740478 FlashRedStopLamp 3 "Unavailable / Do Not Flash" 2 "Reserved" 1 "Fast Flash" 0 "Slow Flash" ;
VAL_ 2566740478 FlashProtectLamp 3 "Unavailable / Do Not Flash" 2 "Reserved" 1 "Fast Flash" 0 "Slow Flash" ;
VAL_ 2566740478 FlashMalfuncIndicatorLamp 3 "Unavailable / Do Not Flash" 2 "Reserved" 1 "Fast Flash" 0 "Slow Flash" ;
VAL_ 2566740478 FlashAmberWarningLamp 3 "Unavailable / Do Not Flash" 2 "Reserved" 1 "Fast Flash" 0 "Slow Flash" ;
VAL_ 2566740478 MalfunctionIndicatorLampStatus 3 "Not available" 2 "Reserved" 1 "Lamp on" 0 "Lamp off" ;
VAL_ 2566740478 AmberWarningLampStatus 3 "Not available" 2 "Reserved" 1 "Lamp on" 0 "Lamp off" ;
VAL_ 2566740478 RedStopLampState 3 "Not available" 2 "Reserved" 1 "Lamp on" 0 "Lamp off" ;
VAL_ 2566740478 ProtectLampStatus 3 "Not available" 2 "Reserved" 1 "Lamp on" 0 "Lamp off" ;
VAL_ 2566740734 FlashRedStopLamp 3 "Unavailable / Do Not Flash" 2 "Reserved" 1 "Fast Flash" 0 "Slow Flash" ;
VAL_ 2566740734 FlashProtectLamp 3 "Unavailable / Do Not Flash" 2 "Reserved" 1 "Fast Flash" 0 "Slow Flash" ;
VAL_ 2566740734 FlashMalfuncIndicatorLamp 3 "Unavailable / Do Not Flash" 2 "Reserved" 1 "Fast Flash" 0 "Slow Flash" ;
VAL_ 2566740734 FlashAmberWarningLamp 3 "Unavailable / Do Not Flash" 2 "Reserved" 1 "Fast Flash" 0 "Slow Flash" ;
VAL_ 2566740734 MalfunctionIndicatorLampStatus 3 "Not available" 2 "Reserved" 1 "Lamp on" 0 "Lamp off" ;
VAL_ 2566740734 AmberWarningLampStatus 3 "Not available" 2 "Reserved" 1 "Lamp on" 0 "Lamp off" ;
VAL_ 2566740734 RedStopLampState 3 "Not available" 2 "Reserved" 1 "Lamp on" 0 "Lamp off" ;
VAL_ 2566740734 ProtectLampStatus 3 "Not available" 2 "Reserved" 1 "Lamp on" 0 "Lamp off" ;
VAL_ 2566740990 FlashRedStopLamp 3 "Unavailable / Do Not Flash" 2 "Reserved" 1 "Fast Flash" 0 "Slow Flash" ;
VAL_ 2566740990 FlashProtectLamp 3 "Unavailable / Do Not Flash" 2 "Reserved" 1 "Fast Flash" 0 "Slow Flash" ;
VAL_ 2566740990 FlashMalfuncIndicatorLamp 3 "Unavailable / Do Not Flash" 2 "Reserved" 1 "Fast Flash" 0 "Slow Flash" ;
VAL_ 2566740990 FlashAmberWarningLamp 3 "Unavailable / Do Not Flash" 2 "Reserved" 1 "Fast Flash" 0 "Slow Flash" ;
VAL_ 2566740990 MalfunctionIndicatorLampStatus 3 "Not available" 2 "Reserved" 1 "Lamp on" 0 "Lamp off" ;
VAL_ 2566740990 AmberWarningLampStatus 3 "Not available" 2 "Reserved" 1 "Lamp on" 0 "Lamp off" ;
VAL_ 2566740990 RedStopLampState 3 "Not available" 2 "Reserved" 1 "Lamp on" 0 "Lamp off" ;
VAL_ 2566740990 ProtectLampStatus 3 "Not available" 2 "Reserved" 1 "Lamp on" 0 "Lamp off" ;
VAL_ 2566741246 FlashRedStopLamp 3 "Unavailable / Do Not Flash" 2 "Reserved" 1 "Fast Flash" 0 "Slow Flash" ;
VAL_ 2566741246 FlashProtectLamp 3 "Unavailable / Do Not Flash" 2 "Reserved" 1 "Fast Flash" 0 "Slow Flash" ;
VAL_ 2566741246 FlashMalfuncIndicatorLamp 3 "Unavailable / Do Not Flash" 2 "Reserved" 1 "Fast Flash" 0 "Slow Flash" ;
VAL_ 2566741246 FlashAmberWarningLamp 3 "Unavailable / Do Not Flash" 2 "Reserved" 1 "Fast Flash" 0 "Slow Flash" ;
VAL_ 2566741246 MalfunctionIndicatorLampStatus 3 "Not available" 2 "Reserved" 1 "Lamp on" 0 "Lamp off" ;
VAL_ 2566741246 AmberWarningLampStatus 3 "Not available" 2 "Reserved" 1 "Lamp on" 0 "Lamp off" ;
VAL_ 2566741246 RedStopLampState 3 "Not available" 2 "Reserved" 1 "Lamp on" 0 "Lamp off" ;
VAL_ 2566741246 ProtectLampStatus 3 "Not available" 2 "Reserved" 1 "Lamp on" 0 "Lamp off" ;
VAL_ 2566741502 FlashRedStopLamp 3 "Unavailable / Do Not Flash" 2 "Reserved" 1 "Fast Flash" 0 "Slow Flash" ;
VAL_ 2566741502 FlashProtectLamp 3 "Unavailable / Do Not Flash" 2 "Reserved" 1 "Fast Flash" 0 "Slow Flash" ;
VAL_ 2566741502 FlashMalfuncIndicatorLamp 3 "Unavailable / Do Not Flash" 2 "Reserved" 1 "Fast Flash" 0 "Slow Flash" ;
VAL_ 2566741502 FlashAmberWarningLamp 3 "Unavailable / Do Not Flash" 2 "Reserved" 1 "Fast Flash" 0 "Slow Flash" ;
VAL_ 2566741502 MalfunctionIndicatorLampStatus 3 "Not available" 2 "Reserved" 1 "Lamp on" 0 "Lamp off" ;
VAL_ 2566741502 AmberWarningLampStatus 3 "Not available" 2 "Reserved" 1 "Lamp on" 0 "Lamp off" ;
VAL_ 2566741502 RedStopLampState 3 "Not available" 2 "Reserved" 1 "Lamp on" 0 "Lamp off" ;
VAL_ 2566741502 ProtectLampStatus 3 "Not available" 2 "Reserved" 1 "Lamp on" 0 "Lamp off" ;
VAL_ 2566741758 FlashRedStopLamp 3 "Unavailable / Do Not Flash" 2 "Reserved" 1 "Fast Flash" 0 "Slow Flash" ;
VAL_ 2566741758 FlashProtectLamp 3 "Unavailable / Do Not Flash" 2 "Reserved" 1 "Fast Flash" 0 "Slow Flash" ;
VAL_ 2566741758 FlashMalfuncIndicatorLamp 3 "Unavailable / Do Not Flash" 2 "Reserved" 1 "Fast Flash" 0 "Slow Flash" ;
VAL_ 2566741758 FlashAmberWarningLamp 3 "Unavailable / Do Not Flash" 2 "Reserved" 1 "Fast Flash" 0 "Slow Flash" ;
VAL_ 2566741758 MalfunctionIndicatorLampStatus 3 "Not available" 2 "Reserved" 1 "Lamp on" 0 "Lamp off" ;
VAL_ 2566741758 AmberWarningLampStatus 3 "Not available" 2 "Reserved" 1 "Lamp on" 0 "Lamp off" ;
VAL_ 2566741758 RedStopLampState 3 "Not available" 2 "Reserved" 1 "Lamp on" 0 "Lamp off" ;
VAL_ 2566741758 ProtectLampStatus 3 "Not available" 2 "Reserved" 1 "Lamp on" 0 "Lamp off" ;
VAL_ 2566742014 FlashRedStopLamp 3 "Unavailable / Do Not Flash" 2 "Reserved" 1 "Fast Flash" 0 "Slow Flash" ;
VAL_ 2566742014 FlashProtectLamp 3 "Unavailable / Do Not Flash" 2 "Reserved" 1 "Fast Flash" 0 "Slow Flash" ;
VAL_ 2566742014 FlashMalfuncIndicatorLamp 3 "Unavailable / Do Not Flash" 2 "Reserved" 1 "Fast Flash" 0 "Slow Flash" ;
VAL_ 2566742014 FlashAmberWarningLamp 3 "Unavailable / Do Not Flash" 2 "Reserved" 1 "Fast Flash" 0 "Slow Flash" ;
VAL_ 2566742014 MalfunctionIndicatorLampStatus 3 "Not available" 2 "Reserved" 1 "Lamp on" 0 "Lamp off" ;
VAL_ 2566742014 AmberWarningLampStatus 3 "Not available" 2 "Reserved" 1 "Lamp on" 0 "Lamp off" ;
VAL_ 2566742014 RedStopLampState 3 "Not available" 2 "Reserved" 1 "Lamp on" 0 "Lamp off" ;
VAL_ 2566742014 ProtectLampStatus 3 "Not available" 2 "Reserved" 1 "Lamp on" 0 "Lamp off" ;
VAL_ 2560622334 FlashRedStopLamp 3 "Unavailable / Do Not Flash" 2 "Reserved" 1 "Fast Flash" 0 "Slow Flash" ;
VAL_ 2560622334 FlashProtectLamp 3 "Unavailable / Do Not Flash" 2 "Reserved" 1 "Fast Flash" 0 "Slow Flash" ;
VAL_ 2560622334 FlashMalfuncIndicatorLamp 3 "Unavailable / Do Not Flash" 2 "Reserved" 1 "Fast Flash" 0 "Slow Flash" ;
VAL_ 2560622334 FlashAmberWarningLamp 3 "Unavailable / Do Not Flash" 2 "Reserved" 1 "Fast Flash" 0 "Slow Flash" ;
VAL_ 2560622334 MalfunctionIndicatorLampStatus 3 "Not available" 2 "Reserved" 1 "Lamp on" 0 "Lamp off" ;
VAL_ 2560622334 AmberWarningLampStatus 3 "Not available" 2 "Reserved" 1 "Lamp on" 0 "Lamp off" ;
VAL_ 2560622334 RedStopLampState 3 "Not available" 2 "Reserved" 1 "Lamp on" 0 "Lamp off" ;
VAL_ 2560622334 ProtectLampStatus 3 "Not available" 2 "Reserved" 1 "Lamp on" 0 "Lamp off" ;
VAL_ 2566744062 ZeroNetVehicleWeightChange 3 "Not available / Not applicable" 2 "Reserved" 1 "Zero Net Vehicle Weight Change" 0 "No change to Net Vehicle Weight Change" ;
VAL_ 2566750462 FlashRedStopLamp 3 "Unavailable / Do Not Flash" 2 "Reserved" 1 "Fast Flash" 0 "Slow Flash" ;
VAL_ 2566750462 FlashProtectLamp 3 "Unavailable / Do Not Flash" 2 "Reserved" 1 "Fast Flash" 0 "Slow Flash" ;
VAL_ 2566750462 FlashMalfuncIndicatorLamp 3 "Unavailable / Do Not Flash" 2 "Reserved" 1 "Fast Flash" 0 "Slow Flash" ;
VAL_ 2566750462 FlashAmberWarningLamp 3 "Unavailable / Do Not Flash" 2 "Reserved" 1 "Fast Flash" 0 "Slow Flash" ;
VAL_ 2566750462 MalfunctionIndicatorLampStatus 3 "Not available" 2 "Reserved" 1 "Lamp on" 0 "Lamp off" ;
VAL_ 2566750462 AmberWarningLampStatus 3 "Not available" 2 "Reserved" 1 "Lamp on" 0 "Lamp off" ;
VAL_ 2566750462 RedStopLampState 3 "Not available" 2 "Reserved" 1 "Lamp on" 0 "Lamp off" ;
VAL_ 2566750462 ProtectLampStatus 3 "Not available" 2 "Reserved" 1 "Lamp on" 0 "Lamp off" ;
VAL_ 2566750974 FlashRedStopLamp 3 "Unavailable / Do Not Flash" 2 "Reserved" 1 "Fast Flash" 0 "Slow Flash" ;
VAL_ 2566750974 FlashProtectLamp 3 "Unavailable / Do Not Flash" 2 "Reserved" 1 "Fast Flash" 0 "Slow Flash" ;
VAL_ 2566750974 FlashMalfuncIndicatorLamp 3 "Unavailable / Do Not Flash" 2 "Reserved" 1 "Fast Flash" 0 "Slow Flash" ;
VAL_ 2566750974 FlashAmberWarningLamp 3 "Unavailable / Do Not Flash" 2 "Reserved" 1 "Fast Flash" 0 "Slow Flash" ;
VAL_ 2566750974 MalfunctionIndicatorLampStatus 3 "Not available" 2 "Reserved" 1 "Lamp on" 0 "Lamp off" ;
VAL_ 2566750974 AmberWarningLampStatus 3 "Not available" 2 "Reserved" 1 "Lamp on" 0 "Lamp off" ;
VAL_ 2566750974 RedStopLampState 3 "Not available" 2 "Reserved" 1 "Lamp on" 0 "Lamp off" ;
VAL_ 2566750974 ProtectLampStatus 3 "Not available" 2 "Reserved" 1 "Lamp on" 0 "Lamp off" ;
VAL_ 2566754558 AETCDataCollectionStandard 15 "Not Available" 0 "SAE J1995" ;
VAL_ 2566749950 RightHeadlampLightDistribution 15 "Not available" 8 "1110 Reserved" 7 "Different light distributions not available No AFS distributions available Head lamp has only one distribution" 6 "Light distribution failure  Module is damaged current position may affect oncoming traffic" 5 "Light distribution fail safe position  Module is damaged current light distribution does not affect oncoming traffic" 4 "Light distribution adverse weather  The adverse weather light improves the viewing situation for the driver on wet" 3 "Light distribution high beam  The high beam distribution of the module generates an illumination level that an" 2 "Light distribution motorway  The task of motorway light is an improved overall viewing distance and an optimum of" 1 "Light distribution country  Country light is mostly similar to the actual SAE low beam pattern Class C" 0 "Light distribution town  The basic light distribution for town light is generated with a symmetrical cutoff line Class" ;
VAL_ 2566749950 LeftHeadlampLightDistribution 15 "Not available" 8 "1110 Reserved" 7 "Different light distributions not available No AFS distributions available Head lamp has only one distribution" 6 "Light distribution failure  Module is damaged current position may affect oncoming traffic" 5 "Light distribution fail safe position  Module is damaged current light distribution does not affect oncoming traffic" 4 "Light distribution adverse weather  The adverse weather light improves the viewing situation for the driver on wet" 3 "Light distribution high beam  The high beam distribution of the module generates an illumination level that an" 2 "Light distribution motorway  The task of motorway light is an improved overall viewing distance and an optimum of" 1 "Light distribution country  Country light is mostly similar to the actual SAE low beam pattern Class C" 0 "Light distribution town  The basic light distribution for town light is generated with a symmetrical cutoff line Class" ;
VAL_ 2566749950 RightHeadlampDynamicBendingLight 7 "Not available" 4 "110 Reserved" 3 "Dynamic bending light failure Bending light does not work current position may affect oncoming traffic" 2 "Dynamic bending light fail safe position Bending light is damaged current position does not affect oncoming traffic" 1 "Dynamic bending light is working properly Normal operation mode Bending light is working properly" 0 "Dynamic bending light deactivated There is no problem but for some reasons eg daylight present the bending" ;
VAL_ 2566749950 LeftHeadlampDynamicBendingLight 7 "Not available" 4 "110 Reserved" 3 "Dynamic bending light failure Bending light does not work current position may affect oncoming traffic" 2 "Dynamic bending light fail safe position Bending light is damaged current position does not affect oncoming traffic" 1 "Dynamic bending light is working properly Normal operation mode Bending light is working properly" 0 "Dynamic bending light deactivated There is no problem but for some reasons eg daylight present the bending" ;
VAL_ 2566838782 AuxI_O13 3 "Not available" 2 "Error" 1 "Auxiliary channel on" 0 "Auxiliary channel off" ;
VAL_ 2566838782 AuxI_O14 3 "Not available" 2 "Error" 1 "Auxiliary channel on" 0 "Auxiliary channel off" ;
VAL_ 2566838782 AuxI_O15 3 "Not available" 2 "Error" 1 "Auxiliary channel on" 0 "Auxiliary channel off" ;
VAL_ 2566838782 AuxI_O16 3 "Not available" 2 "Error" 1 "Auxiliary channel on" 0 "Auxiliary channel off" ;
VAL_ 2566838782 AuxI_O09 3 "Not available" 2 "Error" 1 "Auxiliary channel on" 0 "Auxiliary channel off" ;
VAL_ 2566838782 AuxI_O10 3 "Not available" 2 "Error" 1 "Auxiliary channel on" 0 "Auxiliary channel off" ;
VAL_ 2566838782 AuxI_O11 3 "Not available" 2 "Error" 1 "Auxiliary channel on" 0 "Auxiliary channel off" ;
VAL_ 2566838782 AuxI_O12 3 "Not available" 2 "Error" 1 "Auxiliary channel on" 0 "Auxiliary channel off" ;
VAL_ 2566838782 AuxI_O05 3 "Not available" 2 "Error" 1 "Auxiliary channel on" 0 "Auxiliary channel off" ;
VAL_ 2566838782 AuxI_O06 3 "Not available" 2 "Error" 1 "Auxiliary channel on" 0 "Auxiliary channel off" ;
VAL_ 2566838782 AuxI_O07 3 "Not available" 2 "Error" 1 "Auxiliary channel on" 0 "Auxiliary channel off" ;
VAL_ 2566838782 AuxI_O08 3 "Not available" 2 "Error" 1 "Auxiliary channel on" 0 "Auxiliary channel off" ;
VAL_ 2566838782 AuxI_O01 3 "Not available" 2 "Error" 1 "Auxiliary channel on" 0 "Auxiliary channel off" ;
VAL_ 2566838782 AuxI_O02 3 "Not available" 2 "Error" 1 "Auxiliary channel on" 0 "Auxiliary channel off" ;
VAL_ 2566838782 AuxI_O03 3 "Not available" 2 "Error" 1 "Auxiliary channel on" 0 "Auxiliary channel off" ;
VAL_ 2566838782 AuxI_O04 3 "Not available" 2 "Error" 1 "Auxiliary channel on" 0 "Auxiliary channel off" ;
VAL_ 2561146622 AuxI_O45 3 "Not Available or Take No Action depending on application" 2 "Error Indicator or Not Used  depending on application" 1 "Auxiliary channel on" 0 "Auxiliary channel off" ;
VAL_ 2561146622 AuxI_O46 3 "Not Available or Take No Action depending on application" 2 "Error Indicator or Not Used  depending on application" 1 "Auxiliary channel on" 0 "Auxiliary channel off" ;
VAL_ 2561146622 AuxI_O47 3 "Not Available or Take No Action depending on application" 2 "Error Indicator or Not Used  depending on application" 1 "Auxiliary channel on" 0 "Auxiliary channel off" ;
VAL_ 2561146622 AuxI_O48 3 "Not Available or Take No Action depending on application" 2 "Error Indicator or Not Used  depending on application" 1 "Auxiliary channel on" 0 "Auxiliary channel off" ;
VAL_ 2561146622 AuxI_O41 3 "Not Available or Take No Action depending on application" 2 "Error Indicator or Not Used  depending on application" 1 "Auxiliary channel on" 0 "Auxiliary channel off" ;
VAL_ 2561146622 AuxI_O42 3 "Not Available or Take No Action depending on application" 2 "Error Indicator or Not Used  depending on application" 1 "Auxiliary channel on" 0 "Auxiliary channel off" ;
VAL_ 2561146622 AuxI_O43 3 "Not Available or Take No Action depending on application" 2 "Error Indicator or Not Used  depending on application" 1 "Auxiliary channel on" 0 "Auxiliary channel off" ;
VAL_ 2561146622 AuxI_O44 3 "Not Available or Take No Action depending on application" 2 "Error Indicator or Not Used  depending on application" 1 "Auxiliary channel on" 0 "Auxiliary channel off" ;
VAL_ 2561146622 AuxI_O37 3 "Not Available or Take No Action depending on application" 2 "Error Indicator or Not Used  depending on application" 1 "Auxiliary channel on" 0 "Auxiliary channel off" ;
VAL_ 2561146622 AuxI_O38 3 "Not Available or Take No Action depending on application" 2 "Error Indicator or Not Used  depending on application" 1 "Auxiliary channel on" 0 "Auxiliary channel off" ;
VAL_ 2561146622 AuxI_O39 3 "Not Available or Take No Action depending on application" 2 "Error Indicator or Not Used  depending on application" 1 "Auxiliary channel on" 0 "Auxiliary channel off" ;
VAL_ 2561146622 AuxI_O40 3 "Not Available or Take No Action depending on application" 2 "Error Indicator or Not Used  depending on application" 1 "Auxiliary channel on" 0 "Auxiliary channel off" ;
VAL_ 2561146622 AuxI_O33 3 "Not Available or Take No Action depending on application" 2 "Error Indicator or Not Used  depending on application" 1 "Auxiliary channel on" 0 "Auxiliary channel off" ;
VAL_ 2561146622 AuxI_O34 3 "Not Available or Take No Action depending on application" 2 "Error Indicator or Not Used  depending on application" 1 "Auxiliary channel on" 0 "Auxiliary channel off" ;
VAL_ 2561146622 AuxI_O35 3 "Not Available or Take No Action depending on application" 2 "Error Indicator or Not Used  depending on application" 1 "Auxiliary channel on" 0 "Auxiliary channel off" ;
VAL_ 2561146622 AuxI_O36 3 "Not Available or Take No Action depending on application" 2 "Error Indicator or Not Used  depending on application" 1 "Auxiliary channel on" 0 "Auxiliary channel off" ;
VAL_ 2561146622 AuxI_O29 3 "Not Available or Take No Action depending on application" 2 "Error Indicator or Not Used  depending on application" 1 "Auxiliary channel on" 0 "Auxiliary channel off" ;
VAL_ 2561146622 AuxI_O30 3 "Not Available or Take No Action depending on application" 2 "Error Indicator or Not Used  depending on application" 1 "Auxiliary channel on" 0 "Auxiliary channel off" ;
VAL_ 2561146622 AuxI_O31 3 "Not Available or Take No Action depending on application" 2 "Error Indicator or Not Used  depending on application" 1 "Auxiliary channel on" 0 "Auxiliary channel off" ;
VAL_ 2561146622 AuxI_O32 3 "Not Available or Take No Action depending on application" 2 "Error Indicator or Not Used  depending on application" 1 "Auxiliary channel on" 0 "Auxiliary channel off" ;
VAL_ 2561146622 AuxI_O25 3 "Not Available or Take No Action depending on application" 2 "Error Indicator or Not Used  depending on application" 1 "Auxiliary channel on" 0 "Auxiliary channel off" ;
VAL_ 2561146622 AuxI_O26 3 "Not Available or Take No Action depending on application" 2 "Error Indicator or Not Used  depending on application" 1 "Auxiliary channel on" 0 "Auxiliary channel off" ;
VAL_ 2561146622 AuxI_O27 3 "Not Available or Take No Action depending on application" 2 "Error Indicator or Not Used  depending on application" 1 "Auxiliary channel on" 0 "Auxiliary channel off" ;
VAL_ 2561146622 AuxI_O28 3 "Not Available or Take No Action depending on application" 2 "Error Indicator or Not Used  depending on application" 1 "Auxiliary channel on" 0 "Auxiliary channel off" ;
VAL_ 2561146622 AuxI_O21 3 "Not Available or Take No Action depending on application" 2 "Error Indicator or Not Used  depending on application" 1 "Auxiliary channel on" 0 "Auxiliary channel off" ;
VAL_ 2561146622 AuxI_O22 3 "Not Available or Take No Action depending on application" 2 "Error Indicator or Not Used  depending on application" 1 "Auxiliary channel on" 0 "Auxiliary channel off" ;
VAL_ 2561146622 AuxI_O23 3 "Not Available or Take No Action depending on application" 2 "Error Indicator or Not Used  depending on application" 1 "Auxiliary channel on" 0 "Auxiliary channel off" ;
VAL_ 2561146622 AuxI_O24 3 "Not Available or Take No Action depending on application" 2 "Error Indicator or Not Used  depending on application" 1 "Auxiliary channel on" 0 "Auxiliary channel off" ;
VAL_ 2561146622 AuxI_O17 3 "Not Available or Take No Action depending on application" 2 "Error Indicator or Not Used  depending on application" 1 "Auxiliary channel on" 0 "Auxiliary channel off" ;
VAL_ 2561146622 AuxI_O18 3 "Not Available or Take No Action depending on application" 2 "Error Indicator or Not Used  depending on application" 1 "Auxiliary channel on" 0 "Auxiliary channel off" ;
VAL_ 2561146622 AuxI_O19 3 "Not Available or Take No Action depending on application" 2 "Error Indicator or Not Used  depending on application" 1 "Auxiliary channel on" 0 "Auxiliary channel off" ;
VAL_ 2561146622 AuxI_O20 3 "Not Available or Take No Action depending on application" 2 "Error Indicator or Not Used  depending on application" 1 "Auxiliary channel on" 0 "Auxiliary channel off" ;
VAL_ 2561081086 AuxI_O77 3 "Not Available or Take No Action depending on application" 2 "Error Indicator or Not Used  depending on application" 1 "Auxiliary channel on" 0 "Auxiliary channel off" ;
VAL_ 2561081086 AuxI_O78 3 "Not Available or Take No Action depending on application" 2 "Error Indicator or Not Used  depending on application" 1 "Auxiliary channel on" 0 "Auxiliary channel off" ;
VAL_ 2561081086 AuxI_O79 3 "Not Available or Take No Action depending on application" 2 "Error Indicator or Not Used  depending on application" 1 "Auxiliary channel on" 0 "Auxiliary channel off" ;
VAL_ 2561081086 AuxI_O80 3 "Not Available or Take No Action depending on application" 2 "Error Indicator or Not Used  depending on application" 1 "Auxiliary channel on" 0 "Auxiliary channel off" ;
VAL_ 2561081086 AuxI_O73 3 "Not Available or Take No Action depending on application" 2 "Error Indicator or Not Used  depending on application" 1 "Auxiliary channel on" 0 "Auxiliary channel off" ;
VAL_ 2561081086 AuxI_O74 3 "Not Available or Take No Action depending on application" 2 "Error Indicator or Not Used  depending on application" 1 "Auxiliary channel on" 0 "Auxiliary channel off" ;
VAL_ 2561081086 AuxI_O75 3 "Not Available or Take No Action depending on application" 2 "Error Indicator or Not Used  depending on application" 1 "Auxiliary channel on" 0 "Auxiliary channel off" ;
VAL_ 2561081086 AuxI_O76 3 "Not Available or Take No Action depending on application" 2 "Error Indicator or Not Used  depending on application" 1 "Auxiliary channel on" 0 "Auxiliary channel off" ;
VAL_ 2561081086 AuxI_O69 3 "Not Available or Take No Action depending on application" 2 "Error Indicator or Not Used  depending on application" 1 "Auxiliary channel on" 0 "Auxiliary channel off" ;
VAL_ 2561081086 AuxI_O70 3 "Not Available or Take No Action depending on application" 2 "Error Indicator or Not Used  depending on application" 1 "Auxiliary channel on" 0 "Auxiliary channel off" ;
VAL_ 2561081086 AuxI_O71 3 "Not Available or Take No Action depending on application" 2 "Error Indicator or Not Used  depending on application" 1 "Auxiliary channel on" 0 "Auxiliary channel off" ;
VAL_ 2561081086 AuxI_O72 3 "Not Available or Take No Action depending on application" 2 "Error Indicator or Not Used  depending on application" 1 "Auxiliary channel on" 0 "Auxiliary channel off" ;
VAL_ 2561081086 AuxI_O65 3 "Not Available or Take No Action depending on application" 2 "Error Indicator or Not Used  depending on application" 1 "Auxiliary channel on" 0 "Auxiliary channel off" ;
VAL_ 2561081086 AuxI_O66 3 "Not Available or Take No Action depending on application" 2 "Error Indicator or Not Used  depending on application" 1 "Auxiliary channel on" 0 "Auxiliary channel off" ;
VAL_ 2561081086 AuxI_O67 3 "Not Available or Take No Action depending on application" 2 "Error Indicator or Not Used  depending on application" 1 "Auxiliary channel on" 0 "Auxiliary channel off" ;
VAL_ 2561081086 AuxI_O68 3 "Not Available or Take No Action depending on application" 2 "Error Indicator or Not Used  depending on application" 1 "Auxiliary channel on" 0 "Auxiliary channel off" ;
VAL_ 2561081086 AuxI_O61 3 "Not Available or Take No Action depending on application" 2 "Error Indicator or Not Used  depending on application" 1 "Auxiliary channel on" 0 "Auxiliary channel off" ;
VAL_ 2561081086 AuxI_O62 3 "Not Available or Take No Action depending on application" 2 "Error Indicator or Not Used  depending on application" 1 "Auxiliary channel on" 0 "Auxiliary channel off" ;
VAL_ 2561081086 AuxI_O63 3 "Not Available or Take No Action depending on application" 2 "Error Indicator or Not Used  depending on application" 1 "Auxiliary channel on" 0 "Auxiliary channel off" ;
VAL_ 2561081086 AuxI_O64 3 "Not Available or Take No Action depending on application" 2 "Error Indicator or Not Used  depending on application" 1 "Auxiliary channel on" 0 "Auxiliary channel off" ;
VAL_ 2561081086 AuxI_O57 3 "Not Available or Take No Action depending on application" 2 "Error Indicator or Not Used  depending on application" 1 "Auxiliary channel on" 0 "Auxiliary channel off" ;
VAL_ 2561081086 AuxI_O58 3 "Not Available or Take No Action depending on application" 2 "Error Indicator or Not Used  depending on application" 1 "Auxiliary channel on" 0 "Auxiliary channel off" ;
VAL_ 2561081086 AuxI_O59 3 "Not Available or Take No Action depending on application" 2 "Error Indicator or Not Used  depending on application" 1 "Auxiliary channel on" 0 "Auxiliary channel off" ;
VAL_ 2561081086 AuxI_O60 3 "Not Available or Take No Action depending on application" 2 "Error Indicator or Not Used  depending on application" 1 "Auxiliary channel on" 0 "Auxiliary channel off" ;
VAL_ 2561081086 AuxI_O53 3 "Not Available or Take No Action depending on application" 2 "Error Indicator or Not Used  depending on application" 1 "Auxiliary channel on" 0 "Auxiliary channel off" ;
VAL_ 2561081086 AuxI_O54 3 "Not Available or Take No Action depending on application" 2 "Error Indicator or Not Used  depending on application" 1 "Auxiliary channel on" 0 "Auxiliary channel off" ;
VAL_ 2561081086 AuxI_O55 3 "Not Available or Take No Action depending on application" 2 "Error Indicator or Not Used  depending on application" 1 "Auxiliary channel on" 0 "Auxiliary channel off" ;
VAL_ 2561081086 AuxI_O56 3 "Not Available or Take No Action depending on application" 2 "Error Indicator or Not Used  depending on application" 1 "Auxiliary channel on" 0 "Auxiliary channel off" ;
VAL_ 2561081086 AuxI_O49 3 "Not Available or Take No Action depending on application" 2 "Error Indicator or Not Used  depending on application" 1 "Auxiliary channel on" 0 "Auxiliary channel off" ;
VAL_ 2561081086 AuxI_O50 3 "Not Available or Take No Action depending on application" 2 "Error Indicator or Not Used  depending on application" 1 "Auxiliary channel on" 0 "Auxiliary channel off" ;
VAL_ 2561081086 AuxI_O51 3 "Not Available or Take No Action depending on application" 2 "Error Indicator or Not Used  depending on application" 1 "Auxiliary channel on" 0 "Auxiliary channel off" ;
VAL_ 2561081086 AuxI_O52 3 "Not Available or Take No Action depending on application" 2 "Error Indicator or Not Used  depending on application" 1 "Auxiliary channel on" 0 "Auxiliary channel off" ;
VAL_ 2561015550 AuxI_O109 3 "Not Available or Take No Action depending on application" 2 "Error Indicator or Not Used  depending on application" 1 "Auxiliary channel on" 0 "Auxiliary channel off" ;
VAL_ 2561015550 AuxI_O110 3 "Not Available or Take No Action depending on application" 2 "Error Indicator or Not Used  depending on application" 1 "Auxiliary channel on" 0 "Auxiliary channel off" ;
VAL_ 2561015550 AuxI_O111 3 "Not Available or Take No Action depending on application" 2 "Error Indicator or Not Used  depending on application" 1 "Auxiliary channel on" 0 "Auxiliary channel off" ;
VAL_ 2561015550 AuxI_O112 3 "Not Available or Take No Action depending on application" 2 "Error Indicator or Not Used  depending on application" 1 "Auxiliary channel on" 0 "Auxiliary channel off" ;
VAL_ 2561015550 AuxI_O105 3 "Not Available or Take No Action depending on application" 2 "Error Indicator or Not Used  depending on application" 1 "Auxiliary channel on" 0 "Auxiliary channel off" ;
VAL_ 2561015550 AuxI_O106 3 "Not Available or Take No Action depending on application" 2 "Error Indicator or Not Used  depending on application" 1 "Auxiliary channel on" 0 "Auxiliary channel off" ;
VAL_ 2561015550 AuxI_O107 3 "Not Available or Take No Action depending on application" 2 "Error Indicator or Not Used  depending on application" 1 "Auxiliary channel on" 0 "Auxiliary channel off" ;
VAL_ 2561015550 AuxI_O108 3 "Not Available or Take No Action depending on application" 2 "Error Indicator or Not Used  depending on application" 1 "Auxiliary channel on" 0 "Auxiliary channel off" ;
VAL_ 2561015550 AuxI_O101 2 "Error Indicator or Not Used  depending on application" 1 "Auxiliary channel on" 0 "Auxiliary channel off" 3 "Not Available or Take No Action depending on application" ;
VAL_ 2561015550 AuxI_O102 3 "Not Available or Take No Action depending on application" 2 "Error Indicator or Not Used  depending on application" 1 "Auxiliary channel on" 0 "Auxiliary channel off" ;
VAL_ 2561015550 AuxI_O103 3 "Not Available or Take No Action depending on application" 2 "Error Indicator or Not Used  depending on application" 1 "Auxiliary channel on" 0 "Auxiliary channel off" ;
VAL_ 2561015550 AuxI_O104 3 "Not Available or Take No Action depending on application" 2 "Error Indicator or Not Used  depending on application" 1 "Auxiliary channel on" 0 "Auxiliary channel off" ;
VAL_ 2561015550 AuxI_O97 3 "Not Available or Take No Action depending on application" 2 "Error Indicator or Not Used  depending on application" 1 "Auxiliary channel on" 0 "Auxiliary channel off" ;
VAL_ 2561015550 AuxI_O98 3 "Not Available or Take No Action depending on application" 2 "Error Indicator or Not Used  depending on application" 1 "Auxiliary channel on" 0 "Auxiliary channel off" ;
VAL_ 2561015550 AuxI_O99 3 "Not Available or Take No Action depending on application" 2 "Error Indicator or Not Used  depending on application" 1 "Auxiliary channel on" 0 "Auxiliary channel off" ;
VAL_ 2561015550 AuxI_O100 3 "Not Available or Take No Action depending on application" 2 "Error Indicator or Not Used  depending on application" 1 "Auxiliary channel on" 0 "Auxiliary channel off" ;
VAL_ 2561015550 AuxI_O93 3 "Not Available or Take No Action depending on application" 2 "Error Indicator or Not Used  depending on application" 1 "Auxiliary channel on" 0 "Auxiliary channel off" ;
VAL_ 2561015550 AuxI_O94 3 "Not Available or Take No Action depending on application" 2 "Error Indicator or Not Used  depending on application" 1 "Auxiliary channel on" 0 "Auxiliary channel off" ;
VAL_ 2561015550 AuxI_O95 3 "Not Available or Take No Action depending on application" 2 "Error Indicator or Not Used  depending on application" 1 "Auxiliary channel on" 0 "Auxiliary channel off" ;
VAL_ 2561015550 AuxI_O96 3 "Not Available or Take No Action depending on application" 2 "Error Indicator or Not Used  depending on application" 1 "Auxiliary channel on" 0 "Auxiliary channel off" ;
VAL_ 2561015550 AuxI_O89 3 "Not Available or Take No Action depending on application" 2 "Error Indicator or Not Used  depending on application" 1 "Auxiliary channel on" 0 "Auxiliary channel off" ;
VAL_ 2561015550 AuxI_O90 3 "Not Available or Take No Action depending on application" 2 "Error Indicator or Not Used  depending on application" 1 "Auxiliary channel on" 0 "Auxiliary channel off" ;
VAL_ 2561015550 AuxI_O91 3 "Not Available or Take No Action depending on application" 2 "Error Indicator or Not Used  depending on application" 1 "Auxiliary channel on" 0 "Auxiliary channel off" ;
VAL_ 2561015550 AuxI_O92 3 "Not Available or Take No Action depending on application" 2 "Error Indicator or Not Used  depending on application" 1 "Auxiliary channel on" 0 "Auxiliary channel off" ;
VAL_ 2561015550 AuxI_O85 3 "Not Available or Take No Action depending on application" 2 "Error Indicator or Not Used  depending on application" 1 "Auxiliary channel on" 0 "Auxiliary channel off" ;
VAL_ 2561015550 AuxI_O86 3 "Not Available or Take No Action depending on application" 2 "Error Indicator or Not Used  depending on application" 1 "Auxiliary channel on" 0 "Auxiliary channel off" ;
VAL_ 2561015550 AuxI_O87 3 "Not Available or Take No Action depending on application" 2 "Error Indicator or Not Used  depending on application" 1 "Auxiliary channel on" 0 "Auxiliary channel off" ;
VAL_ 2561015550 AuxI_O88 3 "Not Available or Take No Action depending on application" 2 "Error Indicator or Not Used  depending on application" 1 "Auxiliary channel on" 0 "Auxiliary channel off" ;
VAL_ 2561015550 AuxI_O81 3 "Not Available or Take No Action depending on application" 2 "Error Indicator or Not Used  depending on application" 1 "Auxiliary channel on" 0 "Auxiliary channel off" ;
VAL_ 2561015550 AuxI_O82 3 "Not Available or Take No Action depending on application" 2 "Error Indicator or Not Used  depending on application" 1 "Auxiliary channel on" 0 "Auxiliary channel off" ;
VAL_ 2561015550 AuxI_O83 3 "Not Available or Take No Action depending on application" 2 "Error Indicator or Not Used  depending on application" 1 "Auxiliary channel on" 0 "Auxiliary channel off" ;
VAL_ 2561015550 AuxI_O84 3 "Not Available or Take No Action depending on application" 2 "Error Indicator or Not Used  depending on application" 1 "Auxiliary channel on" 0 "Auxiliary channel off" ;
VAL_ 2566746622 TrailerBrakeStrokeAxle5Right 4 "Reserved" 7 "Not available" 6 "Sensor error" 5 "Reserved" 3 "Dragging brake" 2 "Overstroke" 1 "Nonfunctioning" 0 "OK Normal operation" ;
VAL_ 2566746622 TrailerBrakeStrokeAxle5Left 4 "Reserved" 7 "Not available" 6 "Sensor error" 5 "Reserved" 3 "Dragging brake" 2 "Overstroke" 1 "Nonfunctioning" 0 "OK Normal operation" ;
VAL_ 2566746622 TrailerBrakeStrokeAxle4Right 4 "Reserved" 7 "Not available" 6 "Sensor error" 5 "Reserved" 3 "Dragging brake" 2 "Overstroke" 1 "Nonfunctioning" 0 "OK Normal operation" ;
VAL_ 2566746622 TrailerBrakeStrokeAxle4Left 4 "Reserved" 7 "Not available" 6 "Sensor error" 5 "Reserved" 3 "Dragging brake" 2 "Overstroke" 1 "Nonfunctioning" 0 "OK Normal operation" ;
VAL_ 2566746622 TrailerBrakeStrokeAxle3Right 4 "Reserved" 7 "Not available" 6 "Sensor error" 5 "Reserved" 3 "Dragging brake" 2 "Overstroke" 1 "Nonfunctioning" 0 "OK Normal operation" ;
VAL_ 2566746622 TrailerBrakeStrokeAxle3Left 4 "Reserved" 7 "Not available" 6 "Sensor error" 5 "Reserved" 3 "Dragging brake" 2 "Overstroke" 1 "Nonfunctioning" 0 "OK Normal operation" ;
VAL_ 2566746622 TrailerBrakeStrokeAxle2Right 4 "Reserved" 7 "Not available" 6 "Sensor error" 5 "Reserved" 3 "Dragging brake" 2 "Overstroke" 1 "Nonfunctioning" 0 "OK Normal operation" ;
VAL_ 2566746622 TrailerBrakeStrokeAxle2Left 4 "Reserved" 7 "Not available" 6 "Sensor error" 5 "Reserved" 3 "Dragging brake" 2 "Overstroke" 1 "Nonfunctioning" 0 "OK Normal operation" ;
VAL_ 2566746622 TrailerBrakeStrokeAxle1Right 4 "Reserved" 7 "Not available" 6 "Sensor error" 5 "Reserved" 3 "Dragging brake" 2 "Overstroke" 1 "Nonfunctioning" 0 "OK Normal operation" ;
VAL_ 2566746622 TrailerBrakeStrokeAxle1Left 4 "Reserved" 7 "Not available" 6 "Sensor error" 5 "Reserved" 3 "Dragging brake" 2 "Overstroke" 1 "Nonfunctioning" 0 "OK Normal operation" ;
VAL_ 2566746622 TractorBrakeStrokeAxle5Right 4 "Reserved" 7 "Not available" 6 "Sensor error" 5 "Reserved" 3 "Dragging brake" 2 "Overstroke" 1 "Nonfunctioning" 0 "OK Normal operation" ;
VAL_ 2566746622 TractorBrakeStrokeAxle5Left 4 "Reserved" 7 "Not available" 6 "Sensor error" 5 "Reserved" 3 "Dragging brake" 2 "Overstroke" 1 "Nonfunctioning" 0 "OK Normal operation" ;
VAL_ 2566746622 TractorBrakeStrokeAxle4Right 4 "Reserved" 7 "Not available" 6 "Sensor error" 5 "Reserved" 3 "Dragging brake" 2 "Overstroke" 1 "Nonfunctioning" 0 "OK Normal operation" ;
VAL_ 2566746622 TractorBrakeStrokeAxle4Left 4 "Reserved" 7 "Not available" 6 "Sensor error" 5 "Reserved" 3 "Dragging brake" 2 "Overstroke" 1 "Nonfunctioning" 0 "OK Normal operation" ;
VAL_ 2566746622 TractorBrakeStrokeAxle3Right 4 "Reserved" 7 "Not available" 6 "Sensor error" 5 "Reserved" 3 "Dragging brake" 2 "Overstroke" 1 "Nonfunctioning" 0 "OK Normal operation" ;
VAL_ 2566746622 TractorBrakeStrokeAxle3Left 4 "Reserved" 7 "Not available" 6 "Sensor error" 5 "Reserved" 3 "Dragging brake" 2 "Overstroke" 1 "Nonfunctioning" 0 "OK Normal operation" ;
VAL_ 2566746622 TractorBrakeStrokeAxle2Right 4 "Reserved" 7 "Not available" 6 "Sensor error" 5 "Reserved" 3 "Dragging brake" 2 "Overstroke" 1 "Nonfunctioning" 0 "OK Normal operation" ;
VAL_ 2566746622 TractorBrakeStrokeAxle2Left 4 "Reserved" 7 "Not available" 6 "Sensor error" 5 "Reserved" 3 "Dragging brake" 2 "Overstroke" 1 "Nonfunctioning" 0 "OK Normal operation" ;
VAL_ 2566746622 TractorBrakeStrokeAxle1Right 4 "Reserved" 7 "Not available" 6 "Sensor error" 5 "Reserved" 3 "Dragging brake" 2 "Overstroke" 1 "Nonfunctioning" 0 "OK Normal operation" ;
VAL_ 2566746622 TractorBrakeStrokeAxle1Left 4 "Reserved" 7 "Not available" 6 "Sensor error" 5 "Reserved" 3 "Dragging brake" 2 "Overstroke" 1 "Nonfunctioning" 0 "OK Normal operation" ;
VAL_ 2566827774 AirCompressorStatus 3 "Not available" 2 "Error indicator" 1 "Compressor active" 0 "Compressor not active" ;
VAL_ 2566803966 RequestedACCDistanceMode 7 "not available" 6 "error condition" 5 "not defined" 4 "Requested ACC Distance Mode 5 shortest distance" 3 "Requested ACC Distance Mode 4" 2 "Requested ACC Distance Mode 3" 1 "Requested ACC Distance Mode 2" 0 "Requested ACC Distance Mode 1 largest distance" ;
VAL_ 2566803966 ACCUsageDemand 3 "dont care" 2 "reserved" 1 "driver demand for using ACC distance keeping control" 0 "driver demand for not using ACC distance keeping control" ;
VAL_ 2432593918 ForwardCollisionWarning 3 "not available" 2 "Error indicator" 1 "Collision is imminent" 0 "No warning" ;
VAL_ 2432593918 ACCDistanceAlertSignal 3 "Take no action" 2 "Reserved" 1 "ACC DAS Active" 0 "ACC DAS Not Active" ;
VAL_ 2432593918 ACCSystemShutoffWarning 3 "Take no action" 2 "Reserved" 1 "ACC SSOW Active" 0 "ACC SSOW Not Active" ;
VAL_ 2432593918 ACCTargetDetected 3 "Take no action" 2 "Reserved" 1 "Target detected" 0 "No targets detected" ;
VAL_ 2432593918 AdptiveCruiseCtrlSetDistanceMode 7 "Not available/not valid" 6 "Error condition" 5 "Conventional cruise control mode" 4 "ACC Distance mode 5 shortest distance" 3 "ACC Distance mode 4" 2 "ACC Distance mode 3" 1 "ACC Distance mode 2" 0 "ACC Distance mode 1 largest distance" ;
VAL_ 2432593918 AdaptiveCruiseCtrlMode 7 "Not available/not valid" 6 "Disabled or error condition" 5 "Finish mode" 4 "Hold mode" 3 "Overtake mode" 2 "Distance control active" 1 "Speed control active" 0 "Off Standby enabled ready for activation" ;
VAL_ 2565406462 ControlByte 3 "CannotRespond" 2 "AccessDenied" 1 "NACK" 0 "ACK" ;
VAL_ 2566803198 Status2OfDoors 3 "not available" 2 "error" 1 "at least 1 bus door enabled" 0 "all bus doors are disabled" ;
VAL_ 2566803198 Ramp_WheelChairLiftPos 3 "Not available" 2 "Error" 1 "Outside bus" 0 "Inside bus" ;
VAL_ 2566803198 PosOfDoors 15 "Not available" 14 "Error" 2 "All doors closed" 1 "Closing last door" 0 "At least 1 door is open" ;
VAL_ 2565870334 FifthWheelRollWarningIndicator 3 "Not Available" 2 "error" 1 "Limit exceeded" 0 "Limit not exceeded" ;
VAL_ 2566762238 FifthWheelSliderLockIndicator 3 "Not Available" 2 "Error" 1 "Locked" 0 "Not Locked" ;
VAL_ 2566762238 FfthWhlLockCoupleStatusIndicator 3 "Not Available" 2 "Error" 1 "Successful couple detected" 0 "Incomplete or bad couple truck should not be moved" ;
VAL_ 2566762238 FfthWhlLckReadyToCoupleIndicator 3 "Not Available" 2 "Error" 1 "Lock open ready to couple" 0 "Lock not open not ready to couple" ;
VAL_ 2566762238 FifthWheelErrorStatus 13 "13  Not Used" 12 "12  Not Used" 11 "11  Not Used" 10 "10  Not Used" 4 "4  Not Used" 3 "3  Not Used" 15 "15  Not available" 9 "9  Kingpin / Lock Open Handle Pulled" 8 "8  Kingpin Missing More Than 5 Seconds" 7 "7  Coupling Timing Error" 6 "6  Coupling Sequence Error / Kingpin" 5 "5  Coupling Sequence Error" 14 "14  Not Used" 2 "2  Kingpin / Locks Open at Startup" 1 "1  Locks Closed / No Kingpin at Startup" 0 "0  Improper Couple" ;
VAL_ 2566846718 TransOilLevel1MeasurementStatus 15 "Not available" 14 "Error" 13 "Conditions not valid  Other" 12 "Not defined" 9 "Conditions not valid  No request for reading" 8 "Conditions not valid  Engine speed too high" 7 "Conditions not valid  Engine speed too low" 6 "Conditions not valid  Vehicle not level" 5 "Conditions not valid  Vehicle moving output shaft speed too high" 4 "Conditions not valid  Transmission fluid temperature too high" 3 "Conditions not valid  Transmission fluid temperature too low" 2 "Conditions not valid  Transmission in gear" 1 "Conditions not valid  Settling timer still counting down" 0 "Conditions valid for transmission oil level measurement" 11 "Not defined" 10 "Not defined" ;
VAL_ 2566846718 TransOilLevel1CountdownTimer 15 "Not Available" 14 "Error" 13 "Thirteen minutes" 12 "Twelve minutes" 11 "Eleven minutes" 10 "Ten minutes" 9 "Nine minutes" 8 "Eight minutes" 7 "Seven minutes" 6 "Six minutes" 5 "Five minutes" 4 "Four minutes" 3 "Three minutes" 2 "Two minutes" 1 "One minute" 0 "less than 1 minute" ;
VAL_ 2633869310 VoltageRegulatorEnabled 3 "NotAvailable" 2 "Error" 1 "RegulatingVoltage" 0 "NtRegulatingVoltageUnitDisabled" ;
VAL_ 2633869310 VoltageRegulatorSoftStartState 3 "NotAvailable" 2 "Error" 1 "SoftStartIsActive" 0 "SoftStartIsInactive" ;
VAL_ 2633869310 VltgRgltrUndrfrqncyCmpnstnEnbld 3 "NotAvailable" 2 "Error" 1 "UndrfrquencyCompensationEnabled" 0 "UndrfrqencyCompensationDisabled" ;
VAL_ 2633869310 VltgRgltrVAr_PwrFctrOprtingMode 7 "NotAvailable" 6 "Error" 5 "Reserved" 2 "VArRegulationEnabled" 1 "PowerFactorRegulationEnabled" 0 "VAr_PwrFactorRegulationDisabled" ;
VAL_ 2633869310 VltgRglatorLoadCompensationMode 7 "NotAvailable" 6 "Error" 5 "Reserved" 2 "IRLineDropCompensationEnabled" 1 "VoltageDroopCompensationEnabled" 0 "LoadCompensationDisabled" ;
